VERSION "dbc-export 1 2026.26.6.5"

NS_ :

BS_:

BU_: ADSP APSB BB CMP DAS DPB EPAS3P EPASTP EPASTS GTW IDB OCS1P PTC RCM RCU TCU TCU2 UDS UI UIS VCLEFT VCSEAT2L VCSEAT2R

BO_ 942 APSB_warningMatrix2: 8 APSB
 SG_ APSB_w129_ECU_Power_Issue : 0|1@1+ (1,0) [0|1] "" Vector__XXX
 SG_ APSB_w130_ECU_Thermal_Issue : 1|1@1+ (1,0) [0|1] "" Vector__XXX
 SG_ APSB_w131_trap_exception : 2|1@1+ (1,0) [0|1] "" Vector__XXX
 SG_ APSB_w132_appVersionMismatch : 3|1@1+ (1,0) [0|1] "" Vector__XXX
 SG_ APSB_w133_ETHSwitchError : 4|1@1+ (1,0) [0|1] "" Vector__XXX
 SG_ APSB_w134_appMia : 5|1@1+ (1,0) [0|1] "" Vector__XXX
 SG_ APSB_w135_appCritical : 6|1@1+ (1,0) [0|1] "" Vector__XXX
 SG_ APSB_w136_gpsDisabled : 7|1@1+ (1,0) [0|1] "" Vector__XXX
 SG_ APSB_w137_gpsFaultReset : 8|1@1+ (1,0) [0|1] "" Vector__XXX
 SG_ APSB_w138_gpsComIssue : 9|1@1+ (1,0) [0|1] "" Vector__XXX
 SG_ APSB_w139_udpBufferOverflow : 10|1@1+ (1,0) [0|1] "" Vector__XXX
 SG_ APSB_w140_vcfrontMiaVehicleBus : 11|1@1+ (1,0) [0|1] "" Vector__XXX
 SG_ APSB_w141_rcmMiaPartyBus : 12|1@1+ (1,0) [0|1] "" Vector__XXX
 SG_ APSB_w142_diMiaPartyBus : 13|1@1+ (1,0) [0|1] "" Vector__XXX
 SG_ APSB_w143_espMiaPartyBus : 14|1@1+ (1,0) [0|1] "" Vector__XXX
 SG_ APSB_w144_vcleftMiaPartyBus : 15|1@1+ (1,0) [0|1] "" Vector__XXX
 SG_ APSB_w145_vcrightMiaPartyBus : 16|1@1+ (1,0) [0|1] "" Vector__XXX
 SG_ APSB_w146_epas3pMiaPartyBus : 17|1@1+ (1,0) [0|1] "" Vector__XXX
 SG_ APSB_w147_vcleftMiaVehBus : 18|1@1+ (1,0) [0|1] "" Vector__XXX
 SG_ APSB_w148_vcrightMiaVehBus : 19|1@1+ (1,0) [0|1] "" Vector__XXX
 SG_ APSB_w149_epblMiaVehBus : 20|1@1+ (1,0) [0|1] "" Vector__XXX
 SG_ APSB_w150_sccmMiaVehBus : 21|1@1+ (1,0) [0|1] "" Vector__XXX
 SG_ APSB_w151_apRecovered : 22|1@1+ (1,0) [0|1] "" Vector__XXX
 SG_ APSB_w152_gpsFusionStatus : 23|1@1+ (1,0) [0|1] "" Vector__XXX
 SG_ APSB_w153_eacInhibit : 24|1@1+ (1,0) [0|1] "" Vector__XXX
 SG_ APSB_w155_ethLwipError : 26|1@1+ (1,0) [0|1] "" Vector__XXX
 SG_ APSB_w156_lwipAssert : 27|1@1+ (1,0) [0|1] "" Vector__XXX
 SG_ APSB_w157_autopilotReboot : 28|1@1+ (1,0) [0|1] "" Vector__XXX
 SG_ APSB_w158_apbMia : 29|1@1+ (1,0) [0|1] "" Vector__XXX
 SG_ APSB_w159_apbCritical : 30|1@1+ (1,0) [0|1] "" Vector__XXX
 SG_ APSB_w160_apbVersionMismatch : 31|1@1+ (1,0) [0|1] "" Vector__XXX
 SG_ APSB_w161_gpsAntennaDisconnected : 32|1@1+ (1,0) [0|1] "" Vector__XXX
 SG_ APSB_w162_TurboA_DisRegPgoodErr : 33|1@1+ (1,0) [0|1] "" Vector__XXX
 SG_ APSB_w163_TurboA_DisRegNFault : 34|1@1+ (1,0) [0|1] "" Vector__XXX
 SG_ APSB_w164_TurboA_12VFuseFault : 35|1@1+ (1,0) [0|1] "" Vector__XXX
 SG_ APSB_w165_TurboA_Temp_NOS : 36|1@1+ (1,0) [0|1] "" Vector__XXX
 SG_ APSB_w166_TurboA_SMSLockStepErr : 37|1@1+ (1,0) [0|1] "" Vector__XXX
 SG_ APSB_w167_TurboA_TMU_Throttle : 38|1@1+ (1,0) [0|1] "" Vector__XXX
 SG_ APSB_w168_TurboA_SMS_WDOG : 39|1@1+ (1,0) [0|1] "" Vector__XXX
 SG_ APSB_w169_TurboA_SCS_LKUP : 40|1@1+ (1,0) [0|1] "" Vector__XXX
 SG_ APSB_w170_TurboA_A72_watchdog : 41|1@1+ (1,0) [0|1] "" Vector__XXX
 SG_ APSB_w171_TurboA_SMS_taskUtilErr : 42|1@1+ (1,0) [0|1] "" Vector__XXX
 SG_ APSB_w172_apFeaturesUnavailable : 43|1@1+ (1,0) [0|1] "" Vector__XXX
 SG_ APSB_w178_TurboB_DisRegPgoodErr : 49|1@1+ (1,0) [0|1] "" Vector__XXX
 SG_ APSB_w179_TurboB_DisRegNFault : 50|1@1+ (1,0) [0|1] "" Vector__XXX
 SG_ APSB_w180_TurboB_12VFuseFault : 51|1@1+ (1,0) [0|1] "" Vector__XXX
 SG_ APSB_w181_TurboB_Temp_NOS : 52|1@1+ (1,0) [0|1] "" Vector__XXX
 SG_ APSB_w182_TurboB_SMSLockStepErr : 53|1@1+ (1,0) [0|1] "" Vector__XXX
 SG_ APSB_w183_TurboB_TMU_Throttle : 54|1@1+ (1,0) [0|1] "" Vector__XXX
 SG_ APSB_w184_TurboB_SMS_WDOG : 55|1@1+ (1,0) [0|1] "" Vector__XXX
 SG_ APSB_w185_TurboB_SCS_LKUP : 56|1@1+ (1,0) [0|1] "" Vector__XXX
 SG_ APSB_w186_TurboB_A72_watchdog : 57|1@1+ (1,0) [0|1] "" Vector__XXX
 SG_ APSB_w187_TurboB_SMS_taskUtilErr : 58|1@1+ (1,0) [0|1] "" Vector__XXX
 SG_ APSB_w188_otherTurboUartMIA : 59|1@1+ (1,0) [0|1] "" Vector__XXX
 SG_ APSB_w189_vcfrontMiaPartyBus : 60|1@1+ (1,0) [0|1] "" Vector__XXX
 SG_ APSB_w190_iboosterMia : 61|1@1+ (1,0) [0|1] "" Vector__XXX
 SG_ APSB_w191_timesyncError : 62|1@1+ (1,0) [0|1] "" Vector__XXX
 SG_ APSB_w192_CANFault : 63|1@1+ (1,0) [0|1] "" Vector__XXX

BO_ 976 APSB_warningMatrix3: 8 APSB
 SG_ APSB_w193_camWindshieldUnclean : 0|1@1+ (1,0) [0|1] "" Vector__XXX
 SG_ APSB_w194_accDriverResumeRqrd : 1|1@1+ (1,0) [0|1] "" Vector__XXX
 SG_ APSB_w195_scwUnavailable : 2|1@1+ (1,0) [0|1] "" Vector__XXX
 SG_ APSB_w196_stopSignWarning : 3|1@1+ (1,0) [0|1] "" Vector__XXX
 SG_ APSB_w197_redLightWarning : 4|1@1+ (1,0) [0|1] "" Vector__XXX
 SG_ APSB_w198_tsrUnavailable : 5|1@1+ (1,0) [0|1] "" Vector__XXX
 SG_ APSB_w199_apcAbort : 6|1@1+ (1,0) [0|1] "" Vector__XXX
 SG_ APSB_w200_lcSlowdown : 7|1@1+ (1,0) [0|1] "" Vector__XXX
 SG_ APSB_w201_lcAborting : 8|1@1+ (1,0) [0|1] "" Vector__XXX
 SG_ APSB_w202_scwNoisyEnvironment : 9|1@1+ (1,0) [0|1] "" Vector__XXX
 SG_ APSB_w203_apcActivation : 10|1@1+ (1,0) [0|1] "" Vector__XXX
 SG_ APSB_w204_apcFinalFront : 11|1@1+ (1,0) [0|1] "" Vector__XXX
 SG_ APSB_w205_apcFinalRear : 12|1@1+ (1,0) [0|1] "" Vector__XXX
 SG_ APSB_w206_autosteerNotEnabled : 13|1@1+ (1,0) [0|1] "" Vector__XXX
 SG_ APSB_w207_autosteerUnavailable : 14|1@1+ (1,0) [0|1] "" Vector__XXX
 SG_ APSB_w208_rackDetected : 15|1@1+ (1,0) [0|1] "" Vector__XXX
 SG_ APSB_w209_autoSummonRequest : 16|1@1+ (1,0) [0|1] "" Vector__XXX
 SG_ APSB_w210_camObstrcted : 17|1@1+ (1,0) [0|1] "" Vector__XXX
 SG_ APSB_w211_accNoSeatBelt : 18|1@1+ (1,0) [0|1] "" Vector__XXX
 SG_ APSB_w212_lcUnavailableStrikeOut : 19|1@1+ (1,0) [0|1] "" Vector__XXX
 SG_ APSB_w213_autosteerStruckOut : 20|1@1+ (1,0) [0|1] "" Vector__XXX
 SG_ APSB_w214_driverNotIntracting : 21|1@1+ (1,0) [0|1] "" Vector__XXX
 SG_ APSB_w215_contDriverNotIntractin : 22|1@1+ (1,0) [0|1] "" Vector__XXX
 SG_ APSB_w216_driverOverriding : 23|1@1+ (1,0) [0|1] "" Vector__XXX
 SG_ APSB_w217_lcUnavailableSpeeding : 24|1@1+ (1,0) [0|1] "" Vector__XXX
 SG_ APSB_w218_lcSpeedExceededLimit : 25|1@1+ (1,0) [0|1] "" Vector__XXX
 SG_ APSB_w219_lcTempUnavailableSpeed : 26|1@1+ (1,0) [0|1] "" Vector__XXX
 SG_ APSB_w220_lcTempUnavailableRoad : 27|1@1+ (1,0) [0|1] "" Vector__XXX
 SG_ APSB_w221_accRadarBlind : 28|1@1+ (1,0) [0|1] "" Vector__XXX
 SG_ APSB_w222_accCameraBlind : 29|1@1+ (1,0) [0|1] "" Vector__XXX
 SG_ APSB_w223_accObjectInPath : 30|1@1+ (1,0) [0|1] "" Vector__XXX
 SG_ APSB_w224_accCameraCalibration : 31|1@1+ (1,0) [0|1] "" Vector__XXX
 SG_ APSB_w225_lcDegradedVisSpeedLmt : 32|1@1+ (1,0) [0|1] "" Vector__XXX
 SG_ APSB_w226_lcCamCalNeededSpeedLmt : 33|1@1+ (1,0) [0|1] "" Vector__XXX
 SG_ APSB_w227_virtualWallBlocked : 34|1@1+ (1,0) [0|1] "" Vector__XXX
 SG_ APSB_w228_DEPRECATED : 35|1@1+ (1,0) [0|1] "" Vector__XXX
 SG_ APSB_w229_alcUltrasoundDamaged : 36|1@1+ (1,0) [0|1] "" Vector__XXX
 SG_ APSB_w230_alcUltrasoundBlocked : 37|1@1+ (1,0) [0|1] "" Vector__XXX
 SG_ APSB_w231_idfEvent : 38|1@1+ (1,0) [0|1] "" Vector__XXX
 SG_ APSB_w232_laneChangeRequested : 39|1@1+ (1,0) [0|1] "" Vector__XXX
 SG_ APSB_w235_a72LoopDetected : 42|1@1+ (1,0) [0|1] "" Vector__XXX
 SG_ APSB_w236_canSharedMemError : 43|1@1+ (1,0) [0|1] "" Vector__XXX
 SG_ APSB_w237_faultMgrEventDetected : 44|1@1+ (1,0) [0|1] "" Vector__XXX
 SG_ APSB_w238_resetReason : 45|1@1+ (1,0) [0|1] "" Vector__XXX
 SG_ APSB_w241_ddrInitFailures : 48|1@1+ (1,0) [0|1] "" Vector__XXX
 SG_ APSB_w242_tripMBISTFailure : 49|1@1+ (1,0) [0|1] "" Vector__XXX
 SG_ APSB_w243_tripHWErrorStatus : 50|1@1+ (1,0) [0|1] "" Vector__XXX
 SG_ APSB_w244_gpuHWFaultStatus : 51|1@1+ (1,0) [0|1] "" Vector__XXX
 SG_ APSB_w245_eloopRxFromUnexpectedS : 52|1@1+ (1,0) [0|1] "" Vector__XXX
 SG_ APSB_w246_ethloopSwitchPortLinkD : 53|1@1+ (1,0) [0|1] "" Vector__XXX
 SG_ APSB_w247_ethernetFrameError : 54|1@1+ (1,0) [0|1] "" Vector__XXX
 SG_ APSB_w248_ethloopSwitchPoorSqi : 55|1@1+ (1,0) [0|1] "" Vector__XXX
 SG_ APSB_w249_ufsFailures : 56|1@1+ (1,0) [0|1] "" Vector__XXX
 SG_ APSB_w250_ethloopSwitchMemUsageT : 57|1@1+ (1,0) [0|1] "" Vector__XXX
 SG_ APSB_w251_ethloopSwitchMemUsageT : 58|1@1+ (1,0) [0|1] "" Vector__XXX
 SG_ APSB_w252_ethSwitchPortLinkDown : 59|1@1+ (1,0) [0|1] "" Vector__XXX
 SG_ APSB_w253_powerStateTimeout : 60|1@1+ (1,0) [0|1] "" Vector__XXX
 SG_ APSB_w254_sleepStateTimeout : 61|1@1+ (1,0) [0|1] "" Vector__XXX
 SG_ APSB_w255_bootHealth : 62|1@1+ (1,0) [0|1] "" Vector__XXX

BO_ 1003 APSB_warningMatrix4: 8 APSB
 SG_ APSB_w257_assertFailure : 0|1@1+ (1,0) [0|1] "" Vector__XXX
 SG_ APSB_w258_qspiFlashSectorChecksu : 1|1@1+ (1,0) [0|1] "" Vector__XXX
 SG_ APSB_w259_qspiFailure : 2|1@1+ (1,0) [0|1] "" Vector__XXX
 SG_ APSB_w260_pgoodFailure : 3|1@1+ (1,0) [0|1] "" Vector__XXX
 SG_ APSB_w261_vrmFaultGrpA : 4|1@1+ (1,0) [0|1] "" Vector__XXX
 SG_ APSB_w262_vrmFaultGrpB : 5|1@1+ (1,0) [0|1] "" Vector__XXX
 SG_ APSB_w263_vrmFaultGrpC : 6|1@1+ (1,0) [0|1] "" Vector__XXX
 SG_ APSB_w264_ddrPhy0Failures : 7|1@1+ (1,0) [0|1] "" Vector__XXX
 SG_ APSB_w265_ddrPhy1Failures : 8|1@1+ (1,0) [0|1] "" Vector__XXX
 SG_ APSB_w266_ddrPhy2Failures : 9|1@1+ (1,0) [0|1] "" Vector__XXX
 SG_ APSB_w267_ddrPhy3Failures : 10|1@1+ (1,0) [0|1] "" Vector__XXX
 SG_ APSB_w268_ddrControllerFailures : 11|1@1+ (1,0) [0|1] "" Vector__XXX
 SG_ APSB_w269_ethSwitchRxPageCountTo : 12|1@1+ (1,0) [0|1] "" Vector__XXX
 SG_ APSB_w270_ethSwitchRxPageCountTo : 13|1@1+ (1,0) [0|1] "" Vector__XXX
 SG_ APSB_w271_ddrScheduler0EccErrors : 14|1@1+ (1,0) [0|1] "" Vector__XXX
 SG_ APSB_w272_ddrScheduler1EccErrors : 15|1@1+ (1,0) [0|1] "" Vector__XXX
 SG_ APSB_w273_ddrScheduler2EccErrors : 16|1@1+ (1,0) [0|1] "" Vector__XXX
 SG_ APSB_w274_ddrScheduler3EccErrors : 17|1@1+ (1,0) [0|1] "" Vector__XXX
 SG_ APSB_w275_ddrScheduler4EccErrors : 18|1@1+ (1,0) [0|1] "" Vector__XXX
 SG_ APSB_w276_ddrScheduler5EccErrors : 19|1@1+ (1,0) [0|1] "" Vector__XXX
 SG_ APSB_w277_ddrScheduler6EccErrors : 20|1@1+ (1,0) [0|1] "" Vector__XXX
 SG_ APSB_w278_ddrScheduler7EccErrors : 21|1@1+ (1,0) [0|1] "" Vector__XXX
 SG_ APSB_w279_ufsPartitionError : 22|1@1+ (1,0) [0|1] "" Vector__XXX
 SG_ APSB_w280_pepsMia : 23|1@1+ (1,0) [0|1] "" Vector__XXX
 SG_ APSB_w281_rsaMia : 24|1@1+ (1,0) [0|1] "" Vector__XXX
 SG_ APSB_w282_smmuError : 25|1@1+ (1,0) [0|1] "" Vector__XXX
 SG_ APSB_w283_psfaMia : 26|1@1+ (1,0) [0|1] "" Vector__XXX
 SG_ APSB_w284_cam12VBuckBoostAPwrIss : 27|1@1+ (1,0) [0|1] "" Vector__XXX
 SG_ APSB_w285_cam12VBuckBoostBPwrIss : 28|1@1+ (1,0) [0|1] "" Vector__XXX
 SG_ APSB_w286_cam12VEFuseAPrimaryIss : 29|1@1+ (1,0) [0|1] "" Vector__XXX
 SG_ APSB_w287_cam12VEFuseASecondaryI : 30|1@1+ (1,0) [0|1] "" Vector__XXX
 SG_ APSB_w288_brakeboosterMia : 31|1@1+ (1,0) [0|1] "" Vector__XXX
 SG_ APSB_w289_turboTemperatureWarnin : 32|1@1+ (1,0) [0|1] "" Vector__XXX
 SG_ APSB_w290_cam12VBuckBoostBPwrRin : 33|1@1+ (1,0) [0|1] "" Vector__XXX
 SG_ APSB_w291_eplannerError : 34|1@1+ (1,0) [0|1] "" Vector__XXX
 SG_ APSB_w292_CH_busOff : 35|1@1+ (1,0) [0|1] "" Vector__XXX
 SG_ APSB_w293_PARTY_busOff : 36|1@1+ (1,0) [0|1] "" Vector__XXX
 SG_ APSB_w294_VEH_busOff : 37|1@1+ (1,0) [0|1] "" Vector__XXX
 SG_ APSB_w295_PT_busOff : 38|1@1+ (1,0) [0|1] "" Vector__XXX
 SG_ APSB_w296_wdogMonTaskDeadlineMis : 39|1@1+ (1,0) [0|1] "" Vector__XXX
 SG_ APSB_w297_earlyWDogAlert : 40|1@1+ (1,0) [0|1] "" Vector__XXX
 SG_ APSB_w298_cpuToApCanSharedMemErr : 41|1@1+ (1,0) [0|1] "" Vector__XXX
 SG_ APSB_w299_apToCpuCanSharedMemErr : 42|1@1+ (1,0) [0|1] "" Vector__XXX
 SG_ APSB_w300_sharedMemoryAccessErro : 43|1@1+ (1,0) [0|1] "" Vector__XXX
 SG_ APSB_w301_nocTimeoutDetected : 44|1@1+ (1,0) [0|1] "" Vector__XXX
 SG_ APSB_w302_canAPShmFifoFull : 45|1@1+ (1,0) [0|1] "" Vector__XXX
 SG_ APSB_w303_canAPShmFifoEmpty : 46|1@1+ (1,0) [0|1] "" Vector__XXX
 SG_ APSB_w304_dataAbort : 47|1@1+ (1,0) [0|1] "" Vector__XXX
 SG_ APSB_w305_gpsPgoodFailure : 48|1@1+ (1,0) [0|1] "" Vector__XXX
 SG_ APSB_w306_ethPgoodFailure : 49|1@1+ (1,0) [0|1] "" Vector__XXX
 SG_ APSB_w307_eccEventDetected : 50|1@1+ (1,0) [0|1] "" Vector__XXX
 SG_ APSB_w308_pmicErrorDetected : 51|1@1+ (1,0) [0|1] "" Vector__XXX
 SG_ APSB_w309_ethBridgeDown : 52|1@1+ (1,0) [0|1] "" Vector__XXX
 SG_ APSB_w310_wakeBootMetrics : 53|1@1+ (1,0) [0|1] "" Vector__XXX
 SG_ APSB_w311_apbdgDasMia : 54|1@1+ (1,0) [0|1] "" Vector__XXX
 SG_ APSB_w312_apbdgApMia : 55|1@1+ (1,0) [0|1] "" Vector__XXX
 SG_ APSB_w313_BDY_busOff : 56|1@1+ (1,0) [0|1] "" Vector__XXX
 SG_ APSB_w315_epas3pMiaBdyBus : 58|1@1+ (1,0) [0|1] "" Vector__XXX
 SG_ APSB_w316_apBootHealth : 59|1@1+ (1,0) [0|1] "" Vector__XXX
 SG_ APSB_w317_uiMia : 60|1@1+ (1,0) [0|1] "" Vector__XXX
 SG_ APSB_w318_ethernetNetworkBufferH : 61|1@1+ (1,0) [0|1] "" Vector__XXX
 SG_ APSB_w319_vehDasImposterDetected : 62|1@1+ (1,0) [0|1] "" Vector__XXX
 SG_ APSB_w320_eplannerPreconditionsM : 63|1@1+ (1,0) [0|1] "" Vector__XXX

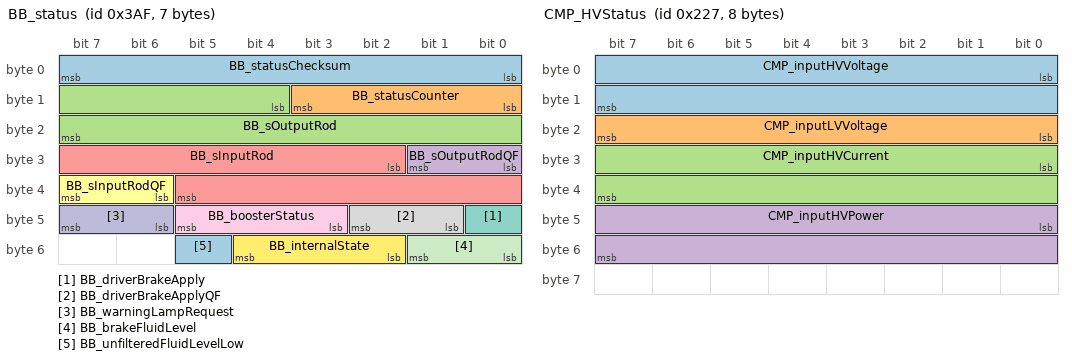
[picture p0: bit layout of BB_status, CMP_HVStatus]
BO_ 943 BB_status: 7 BB
 SG_ BB_statusChecksum : 0|8@1+ (1,0) [0|255] "" Vector__XXX
 SG_ BB_statusCounter : 8|4@1+ (1,0) [0|15] "" Vector__XXX
 SG_ BB_sOutputRod : 12|12@1+ (0.015625,-5) [-5|47] "mm" Vector__XXX
 SG_ BB_sOutputRodQF : 24|2@1+ (1,0) [0|3] "" Vector__XXX
 SG_ BB_sInputRod : 26|12@1+ (0.015625,-5) [-5|47] "mm" Vector__XXX
 SG_ BB_sInputRodQF : 38|2@1+ (1,0) [0|3] "" Vector__XXX
 SG_ BB_driverBrakeApply : 40|1@1+ (1,0) [0|1] "" Vector__XXX
 SG_ BB_driverBrakeApplyQF : 41|2@1+ (1,0) [0|3] "" Vector__XXX
 SG_ BB_boosterStatus : 43|3@1+ (1,0) [0|7] "" Vector__XXX
 SG_ BB_warningLampRequest : 46|2@1+ (1,0) [0|3] "" Vector__XXX
 SG_ BB_brakeFluidLevel : 48|2@1+ (1,0) [0|3] "" Vector__XXX
 SG_ BB_internalState : 50|3@1+ (1,0) [0|7] "" Vector__XXX
 SG_ BB_unfilteredFluidLevelLow : 53|1@1+ (1,0) [0|1] "" Vector__XXX

BO_ 551 CMP_HVStatus: 8 CMP
 SG_ CMP_inputHVVoltage : 0|16@1+ (0.1,0) [0|6553.4] "V" Vector__XXX
 SG_ CMP_inputLVVoltage : 16|8@1+ (0.1,0) [0|25.5] "V" Vector__XXX
 SG_ CMP_inputHVCurrent : 24|16@1+ (0.1,0) [0|6553.4] "A" Vector__XXX
 SG_ CMP_inputHVPower : 40|16@1+ (1,0) [0|65534] "W" Vector__XXX

BO_ 778 DAS_object: 8 DAS
 SG_ DAS_objectId M : 0|3@1+ (1,0) [0|7] "" Vector__XXX
 SG_ DAS_leadVehType m0 : 3|3@1+ (1,0) [0|7] "" Vector__XXX
 SG_ DAS_leadVehRelevantForControl m0 : 7|1@1+ (1,0) [0|1] "" Vector__XXX
 SG_ DAS_leadVehDx m0 : 8|8@1+ (0.5,0) [0|127] "m" Vector__XXX
 SG_ DAS_leadVehVxRel m0 : 16|4@1+ (4,-30) [-30|26] "m/s" Vector__XXX
 SG_ DAS_leadVehDy m0 : 20|7@1+ (0.35,-22.05) [-22.05|22.4] "m" Vector__XXX
 SG_ DAS_leadVehId m0 : 27|7@1+ (1,0) [0|126] "" Vector__XXX
 SG_ DAS_leadVeh2Type m0 : 34|3@1+ (1,0) [0|7] "" Vector__XXX
 SG_ DAS_leadVeh2RelevantForControl m0 : 38|1@1+ (1,0) [0|1] "" Vector__XXX
 SG_ DAS_leadVeh2Dx m0 : 39|8@1+ (0.5,0) [0|127] "m" Vector__XXX
 SG_ DAS_leadVeh2VxRel m0 : 47|4@1+ (4,-30) [-30|26] "m/s" Vector__XXX
 SG_ DAS_leadVeh2Dy m0 : 51|7@1+ (0.35,-22.05) [-22.05|22.4] "m" Vector__XXX
 SG_ DAS_leadVeh2Id m0 : 58|6@1+ (1,0) [1|63] "" Vector__XXX
 SG_ DAS_leftVehType m1 : 3|3@1+ (1,0) [0|7] "" Vector__XXX
 SG_ DAS_leftVehRelevantForControl m1 : 7|1@1+ (1,0) [0|1] "" Vector__XXX
 SG_ DAS_leftVehDx m1 : 8|8@1+ (0.5,0) [0|127] "m" Vector__XXX
 SG_ DAS_leftVehVxRel m1 : 16|4@1+ (4,-30) [-30|26] "m/s" Vector__XXX
 SG_ DAS_leftVehDy m1 : 20|7@1+ (0.35,-22.05) [-22.05|22.4] "m" Vector__XXX
 SG_ DAS_leftVehId m1 : 27|7@1+ (1,0) [0|126] "" Vector__XXX
 SG_ DAS_leftVeh2Type m1 : 34|3@1+ (1,0) [0|7] "" Vector__XXX
 SG_ DAS_leftVeh2RelevantForControl m1 : 38|1@1+ (1,0) [0|1] "" Vector__XXX
 SG_ DAS_leftVeh2Dx m1 : 39|8@1+ (0.5,0) [0|127] "m" Vector__XXX
 SG_ DAS_leftVeh2VxRel m1 : 47|4@1+ (4,-30) [-30|26] "m/s" Vector__XXX
 SG_ DAS_leftVeh2Dy m1 : 51|7@1+ (0.35,-22.05) [-22.05|22.4] "m" Vector__XXX
 SG_ DAS_leftVeh2Id m1 : 58|6@1+ (1,0) [1|63] "" Vector__XXX
 SG_ DAS_rightVehType m2 : 3|3@1+ (1,0) [0|7] "" Vector__XXX
 SG_ DAS_rightVehRelevantForControl m2 : 7|1@1+ (1,0) [0|1] "" Vector__XXX
 SG_ DAS_rightVehDx m2 : 8|8@1+ (0.5,0) [0|127] "m" Vector__XXX
 SG_ DAS_rightVehVxRel m2 : 16|4@1+ (4,-30) [-30|26] "m/s" Vector__XXX
 SG_ DAS_rightVehDy m2 : 20|7@1+ (0.35,-22.05) [-22.05|22.4] "m" Vector__XXX
 SG_ DAS_rightVehId m2 : 27|7@1+ (1,0) [0|126] "" Vector__XXX
 SG_ DAS_rightVeh2Type m2 : 34|3@1+ (1,0) [0|7] "" Vector__XXX
 SG_ DAS_rightVeh2RelevantForControl m2 : 38|1@1+ (1,0) [0|1] "" Vector__XXX
 SG_ DAS_rightVeh2Dx m2 : 39|8@1+ (0.5,0) [0|127] "m" Vector__XXX
 SG_ DAS_rightVeh2VxRel m2 : 47|4@1+ (4,-30) [-30|26] "m/s" Vector__XXX
 SG_ DAS_rightVeh2Dy m2 : 51|7@1+ (0.35,-22.05) [-22.05|22.4] "m" Vector__XXX
 SG_ DAS_rightVeh2Id m2 : 58|6@1+ (1,0) [1|63] "" Vector__XXX
 SG_ DAS_cutinVehType m3 : 3|3@1+ (1,0) [0|7] "" Vector__XXX
 SG_ DAS_cutinVehRelevantForControl m3 : 7|1@1+ (1,0) [0|1] "" Vector__XXX
 SG_ DAS_cutinVehDx m3 : 8|8@1+ (0.5,0) [0|127] "m" Vector__XXX
 SG_ DAS_cutinVehVxRel m3 : 16|4@1+ (4,-30) [-30|26] "m/s" Vector__XXX
 SG_ DAS_cutinVehDy m3 : 20|7@1+ (0.35,-22.05) [-22.05|22.4] "m" Vector__XXX
 SG_ DAS_cutinVehId m3 : 27|7@1+ (1,0) [0|126] "" Vector__XXX
 SG_ DAS_roadSignColor m4 : 3|3@1+ (1,0) [0|7] "" Vector__XXX
 SG_ DAS_roadSignId m4 : 6|8@1+ (1,0) [0|254] "" Vector__XXX
 SG_ DAS_roadSignStopLineDist m4 : 14|10@1+ (0.2,-20) [-20|184.4] "m" Vector__XXX
 SG_ DAS_roadSignControlActive m4 : 24|1@1+ (1,0) [0|1] "" Vector__XXX
 SG_ DAS_roadSignSource m4 : 25|2@1+ (1,0) [0|3] "" Vector__XXX
 SG_ DAS_roadSignArrow m4 : 27|3@1+ (1,0) [0|7] "" Vector__XXX
 SG_ DAS_roadSignOrientation m4 : 30|2@1+ (1,0) [0|3] "" Vector__XXX

BO_ 781 DAS_positioningEngineStatus: 8 DAS
 SG_ DAS_positioningEngineStatusMulti M : 0|4@1+ (1,0) [0|15] "" Vector__XXX
 SG_ DAS_meoSolverNumRuns m2 : 4|2@1+ (1,0) [0|3] "" Vector__XXX
 SG_ DAS_meoSolverReportTerminationTy m2 : 6|3@1+ (1,0) [0|7] "" Vector__XXX
 SG_ DAS_meoSolverReportTotalTimeS m2 : 9|3@1+ (1,0) [0|7] "" Vector__XXX
 SG_ DAS_meoHorizontalAccuracyM m2 : 12|6@1+ (1,0) [0|63] "m" Vector__XXX
 SG_ DAS_meoVerticalAccuracyM m2 : 18|6@1+ (1,0) [0|63] "m" Vector__XXX
 SG_ DAS_meoHeadingAccuracyDeg m2 : 24|3@1+ (1,0) [0|7] "deg" Vector__XXX
 SG_ DAS_meoHeadingValid m2 : 27|1@1+ (1,0) [0|1] "" Vector__XXX
 SG_ DAS_meoNumSatellitesUsed m2 : 28|5@1+ (1,0) [0|31] "" Vector__XXX
 SG_ DAS_meoGpsQualityLevel m2 : 33|3@1+ (1,0) [0|7] "" Vector__XXX
 SG_ DAS_meoFixType m2 : 36|3@1+ (1,0) [0|7] "" Vector__XXX
 SG_ DAS_meoResetCount m2 : 39|3@1+ (1,0) [0|7] "" Vector__XXX
 SG_ DAS_lastMeoResetReason m2 : 42|2@1+ (1,0) [0|3] "" Vector__XXX
 SG_ DAS_vioMultiGpsSelectedSource m3 : 4|3@1+ (1,0) [0|7] "" Vector__XXX
 SG_ DAS_vioMultiGpsPeCooldownActive m3 : 7|1@1+ (1,0) [0|1] "" Vector__XXX
 SG_ DAS_vioMultiGpsPeSppTdcpConsiste m3 : 8|1@1+ (1,0) [0|1] "" Vector__XXX
 SG_ DAS_vioMultiGpsPeMeoConsistentWi m3 : 9|1@1+ (1,0) [0|1] "" Vector__XXX
 SG_ DAS_vioMultiGpsPeSppTdcpVsR_0001 m3 : 10|4@1+ (1,0) [0|15] "m" Vector__XXX
 SG_ DAS_vioMultiGpsPeMeoVsRawGpsTran m3 : 14|4@1+ (1,0) [0|15] "m" Vector__XXX
 SG_ DAS_vioMultiGpsPeSppTdcpVsRawGps m3 : 18|3@1+ (1,0) [0|7] "deg" Vector__XXX
 SG_ DAS_vioMultiGpsPeMeoVsRawGpsRotD m3 : 21|3@1+ (1,0) [0|7] "deg" Vector__XXX
 SG_ DAS_publishedGpsSource m3 : 24|2@1+ (1,0) [0|3] "" Vector__XXX
 SG_ DAS_bluefinEnabled m3 : 26|1@1+ (1,0) [0|1] "" Vector__XXX
 SG_ DAS_orioleDisabled m3 : 27|1@1+ (1,0) [0|1] "" Vector__XXX
 SG_ DAS_disableMonarch m3 : 28|1@1+ (1,0) [0|1] "" Vector__XXX

BO_ 1548 DAS_telemetryRadar: 8 DAS
 SG_ DAS_TR_ObjIndex M : 0|5@1+ (1,0) [0|31] "" Vector__XXX
 SG_ DAS_TR_Counter : 54|2@1+ (1,0) [0|3] "" Vector__XXX
 SG_ DAS_TR_Obj00_Class m0 : 5|3@1+ (1,0) [0|7] "" Vector__XXX
 SG_ DAS_TR_Obj00_Dx m0 : 8|10@1+ (0.15625,0) [0|159.84375] "m" Vector__XXX
 SG_ DAS_TR_Obj00_Dy m0 : 18|6@1+ (0.5,-15.5) [-15.5|16] "m" Vector__XXX
 SG_ DAS_TR_Obj00_Vx m0 : 24|8@1+ (0.5,-63.5) [-63.5|64] "m/s" Vector__XXX
 SG_ DAS_TR_Obj00_RCS m0 : 32|8@1+ (0.25,-14) [-14|49.75] "dB" Vector__XXX
 SG_ DAS_TR_Obj00_Length m0 : 40|6@1+ (0.125,0) [0|7.875] "m" Vector__XXX
 SG_ DAS_TR_Obj00_MovingState m0 : 46|2@1+ (1,0) [0|3] "" Vector__XXX
 SG_ DAS_TR_Obj00_Dz m0 : 48|6@1+ (0.25,-5) [-5|10.75] "m" Vector__XXX
 SG_ DAS_TR_Obj00_Exist m0 : 56|5@1+ (3.125,0) [0|96.875] "%" Vector__XXX

BO_ 1237 DPB_alertLog: 8 DPB
 SG_ DPB_alertID : 0|9@1+ (1,0) [0|511] "" Vector__XXX
 SG_ DPB_alertState : 15|1@1+ (1,0) [0|1] "" Vector__XXX

BO_ 999 DPB_alertMatrix: 8 DPB
 SG_ DPB_matrixIndex M : 0|4@1+ (1,0) [0|15] "" Vector__XXX
 SG_ DPB_a001_pPlungerSensorOffsetHig m0 : 4|1@1+ (1,0) [0|1] "" Vector__XXX
 SG_ DPB_a002_pMC2SensorOffsetHigh m0 : 5|1@1+ (1,0) [0|1] "" Vector__XXX
 SG_ DPB_a003_AswEEPROMReadFailure m0 : 6|1@1+ (1,0) [0|1] "" Vector__XXX
 SG_ DPB_a004_assertionFault m0 : 7|1@1+ (1,0) [0|1] "" Vector__XXX
 SG_ DPB_a005_hardPedalChar m0 : 8|1@1+ (1,0) [0|1] "" Vector__XXX
 SG_ DPB_a006_hardPedalCharGoodCheck m0 : 9|1@1+ (1,0) [0|1] "" Vector__XXX
 SG_ DPB_a007_PMCLeakageDetected m0 : 10|1@1+ (1,0) [0|1] "" Vector__XXX
 SG_ DPB_a008_LiPSPts1Offset m0 : 11|1@1+ (1,0) [0|1] "" Vector__XXX
 SG_ DPB_a009_LiPSPts2Offset m0 : 12|1@1+ (1,0) [0|1] "" Vector__XXX
 SG_ DPB_a010_LiPSPtsConsistency m0 : 13|1@1+ (1,0) [0|1] "" Vector__XXX
 SG_ DPB_a011_PtsNonZeroStage1 m0 : 14|1@1+ (1,0) [0|1] "" Vector__XXX
 SG_ DPB_a012_PtsNonZeroStage2 m0 : 15|1@1+ (1,0) [0|1] "" Vector__XXX
 SG_ DPB_a013_softPedalChar m0 : 16|1@1+ (1,0) [0|1] "" Vector__XXX
 SG_ DPB_a014_CANControllerHWFault m0 : 17|1@1+ (1,0) [0|1] "" Vector__XXX
 SG_ DPB_a015_CAN1BusOff m0 : 18|1@1+ (1,0) [0|1] "" Vector__XXX
 SG_ DPB_a016_CAN2BusOff m0 : 19|1@1+ (1,0) [0|1] "" Vector__XXX
 SG_ DPB_a017_largeLeakageDetected m0 : 20|1@1+ (1,0) [0|1] "" Vector__XXX
 SG_ DPB_a018_largeLeakageDetectedGoo m0 : 21|1@1+ (1,0) [0|1] "" Vector__XXX
 SG_ DPB_a019_DETReportError m0 : 22|1@1+ (1,0) [0|1] "" Vector__XXX
 SG_ DPB_a020_ecuHuMismatch m0 : 23|1@1+ (1,0) [0|1] "" Vector__XXX
 SG_ DPB_a021_brakeSystemOverheatLvl1 m0 : 24|1@1+ (1,0) [0|1] "" Vector__XXX
 SG_ DPB_a022_brakeSystemOverheatLvl2 m0 : 25|1@1+ (1,0) [0|1] "" Vector__XXX
 SG_ DPB_a023_initialPlungerCheckFail m0 : 26|1@1+ (1,0) [0|1] "" Vector__XXX
 SG_ DPB_a024_ESPLDMFailure m0 : 27|1@1+ (1,0) [0|1] "" Vector__XXX
 SG_ DPB_a025_backupCircuitLeakage m0 : 28|1@1+ (1,0) [0|1] "" Vector__XXX
 SG_ DPB_a026_LiPSIDTimeout m0 : 29|1@1+ (1,0) [0|1] "" Vector__XXX
 SG_ DPB_a027_motorTempHighLevel1 m0 : 30|1@1+ (1,0) [0|1] "" Vector__XXX
 SG_ DPB_a028_motorTempHighLevel2 m0 : 31|1@1+ (1,0) [0|1] "" Vector__XXX
 SG_ DPB_a029_motorTestFault m0 : 32|1@1+ (1,0) [0|1] "" Vector__XXX
 SG_ DPB_a030_notShutDownRight m0 : 33|1@1+ (1,0) [0|1] "" Vector__XXX
 SG_ DPB_a031_HWParamReadFailed m0 : 34|1@1+ (1,0) [0|1] "" Vector__XXX
 SG_ DPB_a032_HWParamWriteFailed m0 : 35|1@1+ (1,0) [0|1] "" Vector__XXX
 SG_ DPB_a033_motorDynamicLimited m0 : 36|1@1+ (1,0) [0|1] "" Vector__XXX
 SG_ DPB_a034_lipsMemoryEmpty m0 : 37|1@1+ (1,0) [0|1] "" Vector__XXX
 SG_ DPB_a035_PDURouterinitialization m0 : 38|1@1+ (1,0) [0|1] "" Vector__XXX
 SG_ DPB_a036_lossOfPDUInstanceDetect m0 : 39|1@1+ (1,0) [0|1] "" Vector__XXX
 SG_ DPB_a037_plungerCircuitPressHigh m0 : 40|1@1+ (1,0) [0|1] "" Vector__XXX
 SG_ DPB_a038_plungerCircuitPressHigh m0 : 41|1@1+ (1,0) [0|1] "" Vector__XXX
 SG_ DPB_a039_plungerCircuitPressLow m0 : 42|1@1+ (1,0) [0|1] "" Vector__XXX
 SG_ DPB_a040_plungerCircuitPressLowG m0 : 43|1@1+ (1,0) [0|1] "" Vector__XXX
 SG_ DPB_a041_PSCGearRatioReadFault m0 : 44|1@1+ (1,0) [0|1] "" Vector__XXX
 SG_ DPB_a042_motorLoadPressImplausib m0 : 45|1@1+ (1,0) [0|1] "" Vector__XXX
 SG_ DPB_a043_PSCMotorSizeReadFault m0 : 46|1@1+ (1,0) [0|1] "" Vector__XXX
 SG_ DPB_a044_supplyOvervoltageLvl1 m0 : 47|1@1+ (1,0) [0|1] "" Vector__XXX
 SG_ DPB_a045_supplyOvervoltageLvl2 m0 : 48|1@1+ (1,0) [0|1] "" Vector__XXX
 SG_ DPB_a046_supplyOvervoltageLvl3 m0 : 49|1@1+ (1,0) [0|1] "" Vector__XXX
 SG_ DPB_a047_pPlungerPlausCheckFailu m0 : 50|1@1+ (1,0) [0|1] "" Vector__XXX
 SG_ DPB_a048_supplyUndervoltageLvl1 m0 : 51|1@1+ (1,0) [0|1] "" Vector__XXX
 SG_ DPB_a049_supplyUndervoltageLvl2 m0 : 52|1@1+ (1,0) [0|1] "" Vector__XXX
 SG_ DPB_a050_supplyUndervoltageLvl3 m0 : 53|1@1+ (1,0) [0|1] "" Vector__XXX
 SG_ DPB_a051_PSCVoltageImplausible m0 : 54|1@1+ (1,0) [0|1] "" Vector__XXX
 SG_ DPB_a052_PSIDTimeOut m0 : 55|1@1+ (1,0) [0|1] "" Vector__XXX
 SG_ DPB_a053_hydraulicAssemblyModeAc m0 : 56|1@1+ (1,0) [0|1] "" Vector__XXX
 SG_ DPB_a054_unsupportedHW m0 : 57|1@1+ (1,0) [0|1] "" Vector__XXX
 SG_ DPB_a055_unsupportedSeriesHWDete m0 : 58|1@1+ (1,0) [0|1] "" Vector__XXX
 SG_ DPB_a056_AdcPeripheralFault m0 : 59|1@1+ (1,0) [0|1] "" Vector__XXX
 SG_ DPB_a057_AdcPinTest m0 : 60|1@1+ (1,0) [0|1] "" Vector__XXX
 SG_ DPB_a058_AdcSelftestC5P m0 : 61|1@1+ (1,0) [0|1] "" Vector__XXX
 SG_ DPB_a059_factoryModeActive m0 : 62|1@1+ (1,0) [0|1] "" Vector__XXX
 SG_ DPB_a060_motorBridgeDriverFault m0 : 63|1@1+ (1,0) [0|1] "" Vector__XXX
 SG_ DPB_a061_bridgeSwitchInitError m1 : 4|1@1+ (1,0) [0|1] "" Vector__XXX
 SG_ DPB_a062_loadDumpOnFSLTest m1 : 5|1@1+ (1,0) [0|1] "" Vector__XXX
 SG_ DPB_a063_motorConfigMismatch m1 : 6|1@1+ (1,0) [0|1] "" Vector__XXX
 SG_ DPB_a064_current1OffsetHigh m1 : 7|1@1+ (1,0) [0|1] "" Vector__XXX
 SG_ DPB_a065_current1OffsetLow m1 : 8|1@1+ (1,0) [0|1] "" Vector__XXX
 SG_ DPB_a066_current2OffsetHigh m1 : 9|1@1+ (1,0) [0|1] "" Vector__XXX
 SG_ DPB_a067_current2OffsetLow m1 : 10|1@1+ (1,0) [0|1] "" Vector__XXX
 SG_ DPB_a068_BLMMuxerTimeoutError m1 : 11|1@1+ (1,0) [0|1] "" Vector__XXX
 SG_ DPB_a069_OBDCurrent1OORHigh m1 : 12|1@1+ (1,0) [0|1] "" Vector__XXX
 SG_ DPB_a070_OBDCurrent1OORLow m1 : 13|1@1+ (1,0) [0|1] "" Vector__XXX
 SG_ DPB_a071_OBDCurrent2OORHigh m1 : 14|1@1+ (1,0) [0|1] "" Vector__XXX
 SG_ DPB_a072_OBDCurrent2OORLow m1 : 15|1@1+ (1,0) [0|1] "" Vector__XXX
 SG_ DPB_a073_rotorCosOutOfRangeHigh m1 : 16|1@1+ (1,0) [0|1] "" Vector__XXX
 SG_ DPB_a074_rotorCosOutOfRangeLow m1 : 17|1@1+ (1,0) [0|1] "" Vector__XXX
 SG_ DPB_a075_rotorSinOutOfRangeHigh m1 : 18|1@1+ (1,0) [0|1] "" Vector__XXX
 SG_ DPB_a076_rotorSinOutOfRangeLow m1 : 19|1@1+ (1,0) [0|1] "" Vector__XXX
 SG_ DPB_a077_tempSens1ShortToSupply m1 : 20|1@1+ (1,0) [0|1] "" Vector__XXX
 SG_ DPB_a078_tempSens1ShortToGround m1 : 21|1@1+ (1,0) [0|1] "" Vector__XXX
 SG_ DPB_a079_tempSens2ShortToSupply m1 : 22|1@1+ (1,0) [0|1] "" Vector__XXX
 SG_ DPB_a080_tempSens2ShortToGround m1 : 23|1@1+ (1,0) [0|1] "" Vector__XXX
 SG_ DPB_a081_tempSensImplausVoltage m1 : 24|1@1+ (1,0) [0|1] "" Vector__XXX
 SG_ DPB_a082_chargePumpFault m1 : 25|1@1+ (1,0) [0|1] "" Vector__XXX
 SG_ DPB_a083_chargePumpUndervoltage m1 : 26|1@1+ (1,0) [0|1] "" Vector__XXX
 SG_ DPB_a084_RBCPUException m1 : 27|1@1+ (1,0) [0|1] "" Vector__XXX
 SG_ DPB_a085_infoFailureWrongCUBASHa m1 : 28|1@1+ (1,0) [0|1] "" Vector__XXX
 SG_ DPB_a086_diagHydProtectionPressF m1 : 29|1@1+ (1,0) [0|1] "" Vector__XXX
 SG_ DPB_a087_diagHydProtectionVlvFau m1 : 30|1@1+ (1,0) [0|1] "" Vector__XXX
 SG_ DPB_a088_DMATransferError m1 : 31|1@1+ (1,0) [0|1] "" Vector__XXX
 SG_ DPB_a089_ecuBandgap m1 : 32|1@1+ (1,0) [0|1] "" Vector__XXX
 SG_ DPB_a090_flashFault m1 : 33|1@1+ (1,0) [0|1] "" Vector__XXX
 SG_ DPB_a091_MRGPathTestFault m1 : 34|1@1+ (1,0) [0|1] "" Vector__XXX
 SG_ DPB_a092_decoupleBitTestFault m1 : 35|1@1+ (1,0) [0|1] "" Vector__XXX
 SG_ DPB_a093_ecuBistFaultCtrFault m1 : 36|1@1+ (1,0) [0|1] "" Vector__XXX
 SG_ DPB_a094_ecuClockTestFault m1 : 37|1@1+ (1,0) [0|1] "" Vector__XXX
 SG_ DPB_a095_ecuEnableElHighFault m1 : 38|1@1+ (1,0) [0|1] "" Vector__XXX
 SG_ DPB_a096_ecuEnableElLowFault m1 : 39|1@1+ (1,0) [0|1] "" Vector__XXX
 SG_ DPB_a097_ecuEnableHyHighFault m1 : 40|1@1+ (1,0) [0|1] "" Vector__XXX
 SG_ DPB_a098_ecuEnableHyLowFault m1 : 41|1@1+ (1,0) [0|1] "" Vector__XXX
 SG_ DPB_a099_ecuEnContinuousError m1 : 42|1@1+ (1,0) [0|1] "" Vector__XXX
 SG_ DPB_a100_ecuErrpinCounterFault m1 : 43|1@1+ (1,0) [0|1] "" Vector__XXX
 SG_ DPB_a101_ecuFastWdTestFault m1 : 44|1@1+ (1,0) [0|1] "" Vector__XXX
 SG_ DPB_a102_ecuVrOnWhileWdTimeout m1 : 45|1@1+ (1,0) [0|1] "" Vector__XXX
 SG_ DPB_a103_ecuVrViaSpiFails m1 : 46|1@1+ (1,0) [0|1] "" Vector__XXX
 SG_ DPB_a104_ecuWdStartuptestFault m1 : 47|1@1+ (1,0) [0|1] "" Vector__XXX
 SG_ DPB_a105_ecuWdSContinuousError m1 : 48|1@1+ (1,0) [0|1] "" Vector__XXX
 SG_ DPB_a106_ecuBistCmdTestFault m1 : 49|1@1+ (1,0) [0|1] "" Vector__XXX
 SG_ DPB_a107_vrOnFails m1 : 50|1@1+ (1,0) [0|1] "" Vector__XXX
 SG_ DPB_a108_GTMRefFrequencyError m1 : 51|1@1+ (1,0) [0|1] "" Vector__XXX
 SG_ DPB_a109_GTMTbuMonError m1 : 52|1@1+ (1,0) [0|1] "" Vector__XXX
 SG_ DPB_a110_HWBISTError m1 : 53|1@1+ (1,0) [0|1] "" Vector__XXX
 SG_ DPB_a111_hydraulicHardUndervolta m1 : 54|1@1+ (1,0) [0|1] "" Vector__XXX
 SG_ DPB_a112_hydraulicUndervoltage m1 : 55|1@1+ (1,0) [0|1] "" Vector__XXX
 SG_ DPB_a113_LiPS1SentLineHigh m1 : 56|1@1+ (1,0) [0|1] "" Vector__XXX
 SG_ DPB_a114_LiPS1SentLineLow m1 : 57|1@1+ (1,0) [0|1] "" Vector__XXX
 SG_ DPB_a115_LiPS1SentSensor m1 : 58|1@1+ (1,0) [0|1] "" Vector__XXX
 SG_ DPB_a116_LiPS1SentTransmission m1 : 59|1@1+ (1,0) [0|1] "" Vector__XXX
 SG_ DPB_a117_LiPS2PwmLineHigh m1 : 60|1@1+ (1,0) [0|1] "" Vector__XXX
 SG_ DPB_a118_LiPS2PwmLineLow m1 : 61|1@1+ (1,0) [0|1] "" Vector__XXX
 SG_ DPB_a119_LiPS2PwmTransmission m1 : 62|1@1+ (1,0) [0|1] "" Vector__XXX
 SG_ DPB_a120_LiPSOutOfRangeHigh m1 : 63|1@1+ (1,0) [0|1] "" Vector__XXX
 SG_ DPB_a121_LiPSOutOfRangeLow m2 : 4|1@1+ (1,0) [0|1] "" Vector__XXX
 SG_ DPB_a122_micAsicClkInError m2 : 5|1@1+ (1,0) [0|1] "" Vector__XXX
 SG_ DPB_a123_micAsicInitTestError m2 : 6|1@1+ (1,0) [0|1] "" Vector__XXX
 SG_ DPB_a124_asicOscillatorError m2 : 7|1@1+ (1,0) [0|1] "" Vector__XXX
 SG_ DPB_a125_B6AsicFault m2 : 8|1@1+ (1,0) [0|1] "" Vector__XXX
 SG_ DPB_a126_MICB6TransferError m2 : 9|1@1+ (1,0) [0|1] "" Vector__XXX
 SG_ DPB_a127_hydraulicAsicShortCircu m2 : 10|1@1+ (1,0) [0|1] "" Vector__XXX
 SG_ DPB_a128_micSpiTransferError m2 : 11|1@1+ (1,0) [0|1] "" Vector__XXX
 SG_ DPB_a129_AsicTrimmingNotComplete m2 : 12|1@1+ (1,0) [0|1] "" Vector__XXX
 SG_ DPB_a130_AsicMalfunctionDetected m2 : 13|1@1+ (1,0) [0|1] "" Vector__XXX
 SG_ DPB_a131_ASICOvercurrentOnGPIO25 m2 : 14|1@1+ (1,0) [0|1] "" Vector__XXX
 SG_ DPB_a132_ASICOvercurrentOnGPIO25 m2 : 15|1@1+ (1,0) [0|1] "" Vector__XXX
 SG_ DPB_a133_ASICOvercurrentOnGPIO50 m2 : 16|1@1+ (1,0) [0|1] "" Vector__XXX
 SG_ DPB_a134_ASICOvercurrentOnGPIO50 m2 : 17|1@1+ (1,0) [0|1] "" Vector__XXX
 SG_ DPB_a135_ASICOvercurrentOnGPIO50 m2 : 18|1@1+ (1,0) [0|1] "" Vector__XXX
 SG_ DPB_a136_ASICOvercurrentOnGPIO50 m2 : 19|1@1+ (1,0) [0|1] "" Vector__XXX
 SG_ DPB_a137_ASICOvercurrentOnWRHS m2 : 20|1@1+ (1,0) [0|1] "" Vector__XXX
 SG_ DPB_a138_DIchassisControlCounter m2 : 21|1@1+ (1,0) [0|1] "" Vector__XXX
 SG_ DPB_a139_DIchassisControlChecksu m2 : 22|1@1+ (1,0) [0|1] "" Vector__XXX
 SG_ DPB_a140_DIchassisControlDLC m2 : 23|1@1+ (1,0) [0|1] "" Vector__XXX
 SG_ DPB_a141_DIchassisControlTimeout m2 : 24|1@1+ (1,0) [0|1] "" Vector__XXX
 SG_ DPB_a142_DIsystemStatusCounter m2 : 25|1@1+ (1,0) [0|1] "" Vector__XXX
 SG_ DPB_a143_DIsystemStatusChecksum m2 : 26|1@1+ (1,0) [0|1] "" Vector__XXX
 SG_ DPB_a144_DIsystemStatusDLC m2 : 27|1@1+ (1,0) [0|1] "" Vector__XXX
 SG_ DPB_a145_DIsystemStatusTimeout m2 : 28|1@1+ (1,0) [0|1] "" Vector__XXX
 SG_ DPB_a146_DIFtorqueCounter m2 : 29|1@1+ (1,0) [0|1] "" Vector__XXX
 SG_ DPB_a147_DIFtorqueChecksum m2 : 30|1@1+ (1,0) [0|1] "" Vector__XXX
 SG_ DPB_a148_DIFtorqueDLC m2 : 31|1@1+ (1,0) [0|1] "" Vector__XXX
 SG_ DPB_a149_DIFtorqueTimeout m2 : 32|1@1+ (1,0) [0|1] "" Vector__XXX
 SG_ DPB_a150_DIRtorqueCounter m2 : 33|1@1+ (1,0) [0|1] "" Vector__XXX
 SG_ DPB_a151_DIRtorqueChecksum m2 : 34|1@1+ (1,0) [0|1] "" Vector__XXX
 SG_ DPB_a152_DIRtorqueDLC m2 : 35|1@1+ (1,0) [0|1] "" Vector__XXX
 SG_ DPB_a153_DIRtorqueTimeout m2 : 36|1@1+ (1,0) [0|1] "" Vector__XXX
 SG_ DPB_a154_EPBLstatusCounter m2 : 37|1@1+ (1,0) [0|1] "" Vector__XXX
 SG_ DPB_a155_EPBLstatusChecksum m2 : 38|1@1+ (1,0) [0|1] "" Vector__XXX
 SG_ DPB_a156_EPBLstatusDLC m2 : 39|1@1+ (1,0) [0|1] "" Vector__XXX
 SG_ DPB_a157_EPBLstatusTimeout m2 : 40|1@1+ (1,0) [0|1] "" Vector__XXX
 SG_ DPB_a158_EPBRstatusCounter m2 : 41|1@1+ (1,0) [0|1] "" Vector__XXX
 SG_ DPB_a159_EPBRstatusChecksum m2 : 42|1@1+ (1,0) [0|1] "" Vector__XXX
 SG_ DPB_a160_EPBRstatusDLC m2 : 43|1@1+ (1,0) [0|1] "" Vector__XXX
 SG_ DPB_a161_EPBRstatusTimeout m2 : 44|1@1+ (1,0) [0|1] "" Vector__XXX
 SG_ DPB_a162_ESP_modulator1Counter m2 : 45|1@1+ (1,0) [0|1] "" Vector__XXX
 SG_ DPB_a163_ESP_modulator1Checksum m2 : 46|1@1+ (1,0) [0|1] "" Vector__XXX
 SG_ DPB_a164_ESP_modulator1DLC m2 : 47|1@1+ (1,0) [0|1] "" Vector__XXX
 SG_ DPB_a165_ESP_modulator1Timeout m2 : 48|1@1+ (1,0) [0|1] "" Vector__XXX
 SG_ DPB_a166_ESP_chassis3Counter m2 : 49|1@1+ (1,0) [0|1] "" Vector__XXX
 SG_ DPB_a167_ESP_chassis3Checksum m2 : 50|1@1+ (1,0) [0|1] "" Vector__XXX
 SG_ DPB_a168_ESP_chassis3DLC m2 : 51|1@1+ (1,0) [0|1] "" Vector__XXX
 SG_ DPB_a169_ESP_chassis3Timeout m2 : 52|1@1+ (1,0) [0|1] "" Vector__XXX
 SG_ DPB_a170_ESP_modulator2Counter m2 : 53|1@1+ (1,0) [0|1] "" Vector__XXX
 SG_ DPB_a171_ESP_modulator2Checksum m2 : 54|1@1+ (1,0) [0|1] "" Vector__XXX
 SG_ DPB_a172_ESP_modulator2DLC m2 : 55|1@1+ (1,0) [0|1] "" Vector__XXX
 SG_ DPB_a173_ESP_modulator2Timeout m2 : 56|1@1+ (1,0) [0|1] "" Vector__XXX
 SG_ DPB_a174_ESP_modulator3Counter m2 : 57|1@1+ (1,0) [0|1] "" Vector__XXX
 SG_ DPB_a175_ESP_modulator3Checksum m2 : 58|1@1+ (1,0) [0|1] "" Vector__XXX
 SG_ DPB_a176_ESP_modulator3DLC m2 : 59|1@1+ (1,0) [0|1] "" Vector__XXX
 SG_ DPB_a177_ESP_modulator3Timeout m2 : 60|1@1+ (1,0) [0|1] "" Vector__XXX
 SG_ DPB_a178_PMstate2Counter m2 : 61|1@1+ (1,0) [0|1] "" Vector__XXX
 SG_ DPB_a179_PMstate2Checksum m2 : 62|1@1+ (1,0) [0|1] "" Vector__XXX
 SG_ DPB_a180_PMstate2DLC m2 : 63|1@1+ (1,0) [0|1] "" Vector__XXX
 SG_ DPB_a181_PMstate2Timeout m3 : 4|1@1+ (1,0) [0|1] "" Vector__XXX
 SG_ DPB_a182_RCMInertial2Counter m3 : 5|1@1+ (1,0) [0|1] "" Vector__XXX
 SG_ DPB_a183_RCMInertial2Checksum m3 : 6|1@1+ (1,0) [0|1] "" Vector__XXX
 SG_ DPB_a184_RCMInertial2DLC m3 : 7|1@1+ (1,0) [0|1] "" Vector__XXX
 SG_ DPB_a185_RCMInertial2Timeout m3 : 8|1@1+ (1,0) [0|1] "" Vector__XXX
 SG_ DPB_a186_LVPowerStateTimeout m3 : 9|1@1+ (1,0) [0|1] "" Vector__XXX
 SG_ DPB_a187_LVPowerStateChecksum m3 : 10|1@1+ (1,0) [0|1] "" Vector__XXX
 SG_ DPB_a188_LVPowerStateDLC m3 : 11|1@1+ (1,0) [0|1] "" Vector__XXX
 SG_ DPB_a189_LVPowerStateCounter m3 : 12|1@1+ (1,0) [0|1] "" Vector__XXX
 SG_ DPB_a190_VCLEFTepbmStatusCounter m3 : 13|1@1+ (1,0) [0|1] "" Vector__XXX
 SG_ DPB_a191_VCLEFTepbmStatusChecksu m3 : 14|1@1+ (1,0) [0|1] "" Vector__XXX
 SG_ DPB_a192_VCLEFTepbmStatusDLC m3 : 15|1@1+ (1,0) [0|1] "" Vector__XXX
 SG_ DPB_a193_VCLEFTepbmStatusTimeout m3 : 16|1@1+ (1,0) [0|1] "" Vector__XXX
 SG_ DPB_a194_VCRIGHTepbmStatusCounte m3 : 17|1@1+ (1,0) [0|1] "" Vector__XXX
 SG_ DPB_a195_VCRIGHTepbmStatusChecks m3 : 18|1@1+ (1,0) [0|1] "" Vector__XXX
 SG_ DPB_a196_VCRIGHTepbmStatusDLC m3 : 19|1@1+ (1,0) [0|1] "" Vector__XXX
 SG_ DPB_a197_VCRIGHTepbmStatusTimeou m3 : 20|1@1+ (1,0) [0|1] "" Vector__XXX
 SG_ DPB_a198_CANOvervoltage m3 : 21|1@1+ (1,0) [0|1] "" Vector__XXX
 SG_ DPB_a199_pMC1QFaulty m3 : 22|1@1+ (1,0) [0|1] "" Vector__XXX
 SG_ DPB_a200_ESPRunoutSupportNotAvai m3 : 23|1@1+ (1,0) [0|1] "" Vector__XXX
 SG_ DPB_a201_vehicleSpeedQFaulty m3 : 24|1@1+ (1,0) [0|1] "" Vector__XXX
 SG_ DPB_a202_vehicleStandstillQFault m3 : 25|1@1+ (1,0) [0|1] "" Vector__XXX
 SG_ DPB_a203_ABSNotAvailable m3 : 26|1@1+ (1,0) [0|1] "" Vector__XXX
 SG_ DPB_a204_CANUndervoltage m3 : 27|1@1+ (1,0) [0|1] "" Vector__XXX
 SG_ DPB_a205_NvMWriteCycleExceed m3 : 28|1@1+ (1,0) [0|1] "" Vector__XXX
 SG_ DPB_a206_OSTaskSchemeError m3 : 29|1@1+ (1,0) [0|1] "" Vector__XXX
 SG_ DPB_a207_hydraulicOvervoltage m3 : 30|1@1+ (1,0) [0|1] "" Vector__XXX
 SG_ DPB_a208_pressureSensor1Short m3 : 31|1@1+ (1,0) [0|1] "" Vector__XXX
 SG_ DPB_a209_pressureSensor1High m3 : 32|1@1+ (1,0) [0|1] "" Vector__XXX
 SG_ DPB_a210_pressureSensor1Low m3 : 33|1@1+ (1,0) [0|1] "" Vector__XXX
 SG_ DPB_a211_pressureSensor1Fault m3 : 34|1@1+ (1,0) [0|1] "" Vector__XXX
 SG_ DPB_a212_pressureSensor1Temp m3 : 35|1@1+ (1,0) [0|1] "" Vector__XXX
 SG_ DPB_a213_pressureSensor1Fault m3 : 36|1@1+ (1,0) [0|1] "" Vector__XXX
 SG_ DPB_a214_pressureSensor2Short m3 : 37|1@1+ (1,0) [0|1] "" Vector__XXX
 SG_ DPB_a215_pressureSensor2High m3 : 38|1@1+ (1,0) [0|1] "" Vector__XXX
 SG_ DPB_a216_pressureSensor2Low m3 : 39|1@1+ (1,0) [0|1] "" Vector__XXX
 SG_ DPB_a217_pressureSensor2Fault m3 : 40|1@1+ (1,0) [0|1] "" Vector__XXX
 SG_ DPB_a218_pressureSensor2Temp m3 : 41|1@1+ (1,0) [0|1] "" Vector__XXX
 SG_ DPB_a219_pressureSensor2Fault m3 : 42|1@1+ (1,0) [0|1] "" Vector__XXX
 SG_ DPB_a220_excessiveBoostWakeupsDe m3 : 43|1@1+ (1,0) [0|1] "" Vector__XXX
 SG_ DPB_a221_notShutdownRight m3 : 44|1@1+ (1,0) [0|1] "" Vector__XXX
 SG_ DPB_a222_excessiveEcuResetsDetec m3 : 45|1@1+ (1,0) [0|1] "" Vector__XXX
 SG_ DPB_a223_RAMFault m3 : 46|1@1+ (1,0) [0|1] "" Vector__XXX
 SG_ DPB_a224_brakeBoostLost m3 : 47|1@1+ (1,0) [0|1] "" Vector__XXX
 SG_ DPB_a225_U5VOutOfRange m3 : 48|1@1+ (1,0) [0|1] "" Vector__XXX
 SG_ DPB_a226_U5VTestFault m3 : 49|1@1+ (1,0) [0|1] "" Vector__XXX
 SG_ DPB_a227_brakeFluidLoss m3 : 50|1@1+ (1,0) [0|1] "" Vector__XXX
 SG_ DPB_a228_supplyASICInitFault m3 : 51|1@1+ (1,0) [0|1] "" Vector__XXX
 SG_ DPB_a229_IREFOutOfRange m3 : 52|1@1+ (1,0) [0|1] "" Vector__XXX
 SG_ DPB_a230_OSErrorHook m3 : 53|1@1+ (1,0) [0|1] "" Vector__XXX
 SG_ DPB_a231_stackOverUnderFlow m3 : 54|1@1+ (1,0) [0|1] "" Vector__XXX
 SG_ DPB_a232_systemErrorHook m3 : 55|1@1+ (1,0) [0|1] "" Vector__XXX
 SG_ DPB_a233_systemTaskJitter m3 : 56|1@1+ (1,0) [0|1] "" Vector__XXX
 SG_ DPB_a234_systemTaskOverRun m3 : 57|1@1+ (1,0) [0|1] "" Vector__XXX
 SG_ DPB_a235_UB6PlausiMonFault m3 : 58|1@1+ (1,0) [0|1] "" Vector__XXX
 SG_ DPB_a236_UB6SupplyPathFault m3 : 59|1@1+ (1,0) [0|1] "" Vector__XXX
 SG_ DPB_a237_uCVoltageDividerDrift m3 : 60|1@1+ (1,0) [0|1] "" Vector__XXX
 SG_ DPB_a238_microRegisterFault m3 : 61|1@1+ (1,0) [0|1] "" Vector__XXX
 SG_ DPB_a239_microSafetyFault m3 : 62|1@1+ (1,0) [0|1] "" Vector__XXX
 SG_ DPB_a240_microSafetyLogicFault m3 : 63|1@1+ (1,0) [0|1] "" Vector__XXX
 SG_ DPB_a241_uCSafetyNotification m4 : 4|1@1+ (1,0) [0|1] "" Vector__XXX
 SG_ DPB_a242_uCSafetyNotificationGRA m4 : 5|1@1+ (1,0) [0|1] "" Vector__XXX
 SG_ DPB_a243_microSupplyError m4 : 6|1@1+ (1,0) [0|1] "" Vector__XXX
 SG_ DPB_a244_valvesGenericFault m4 : 7|1@1+ (1,0) [0|1] "" Vector__XXX
 SG_ DPB_a245_valveMV0Fault m4 : 8|1@1+ (1,0) [0|1] "" Vector__XXX
 SG_ DPB_a246_valveMV5Fault m4 : 9|1@1+ (1,0) [0|1] "" Vector__XXX
 SG_ DPB_a247_valveMV6Fault m4 : 10|1@1+ (1,0) [0|1] "" Vector__XXX
 SG_ DPB_a248_valveMV61Fault m4 : 11|1@1+ (1,0) [0|1] "" Vector__XXX
 SG_ DPB_a249_valveMV62Fault m4 : 12|1@1+ (1,0) [0|1] "" Vector__XXX
 SG_ DPB_a250_valveMV7Fault m4 : 13|1@1+ (1,0) [0|1] "" Vector__XXX
 SG_ DPB_a251_valveMV8Fault m4 : 14|1@1+ (1,0) [0|1] "" Vector__XXX
 SG_ DPB_a252_valveMV81Fault m4 : 15|1@1+ (1,0) [0|1] "" Vector__XXX
 SG_ DPB_a253_valveMV82Fault m4 : 16|1@1+ (1,0) [0|1] "" Vector__XXX
 SG_ DPB_a254_valveMV9Fault m4 : 17|1@1+ (1,0) [0|1] "" Vector__XXX
 SG_ DPB_a255_valveRelayShort m4 : 18|1@1+ (1,0) [0|1] "" Vector__XXX
 SG_ DPB_a256_valveRelayActuationFaul m4 : 19|1@1+ (1,0) [0|1] "" Vector__XXX
 SG_ DPB_a257_valveRelayOnContinuous m4 : 20|1@1+ (1,0) [0|1] "" Vector__XXX
 SG_ DPB_a258_valveRelayOffContinuous m4 : 21|1@1+ (1,0) [0|1] "" Vector__XXX
 SG_ DPB_a259_valveRelayTestUndervolt m4 : 22|1@1+ (1,0) [0|1] "" Vector__XXX
 SG_ DPB_a260_valveRelaySafetySwitchF m4 : 23|1@1+ (1,0) [0|1] "" Vector__XXX
 SG_ DPB_a261_WdhAsicWdCmdMissing m4 : 24|1@1+ (1,0) [0|1] "" Vector__XXX
 SG_ DPB_a262_WdhAsicWdErrorCntLimit m4 : 25|1@1+ (1,0) [0|1] "" Vector__XXX
 SG_ DPB_a263_WdhAsicWdErrorCntStuck m4 : 26|1@1+ (1,0) [0|1] "" Vector__XXX
 SG_ DPB_a264_WdhSwBistConCnt m4 : 27|1@1+ (1,0) [0|1] "" Vector__XXX
 SG_ DPB_a265_WdhTaskMonConCnt m4 : 28|1@1+ (1,0) [0|1] "" Vector__XXX
 SG_ DPB_a266_RPSNvMReadFault m4 : 29|1@1+ (1,0) [0|1] "" Vector__XXX
 SG_ DPB_a267_RpsAngleImplausible m4 : 30|1@1+ (1,0) [0|1] "" Vector__XXX
 SG_ DPB_a268_RPSVectorOscillating m4 : 31|1@1+ (1,0) [0|1] "" Vector__XXX
 SG_ DPB_a269_RPSVectorRangeHigh m4 : 32|1@1+ (1,0) [0|1] "" Vector__XXX
 SG_ DPB_a270_RPSVectorRangeLow m4 : 33|1@1+ (1,0) [0|1] "" Vector__XXX
 SG_ DPB_a271_RPSWrongCalibData m4 : 34|1@1+ (1,0) [0|1] "" Vector__XXX
 SG_ DPB_a272_runtimeAssertionFault m4 : 35|1@1+ (1,0) [0|1] "" Vector__XXX
 SG_ DPB_a273_SMMOneRequestsInit m4 : 36|1@1+ (1,0) [0|1] "" Vector__XXX
 SG_ DPB_a274_AswSystemTimeOut m4 : 37|1@1+ (1,0) [0|1] "" Vector__XXX
 SG_ DPB_a275_Ps1Ps2PlausibilityFault m4 : 38|1@1+ (1,0) [0|1] "" Vector__XXX
 SG_ DPB_a276_VCFRONTsensorsCounter m4 : 39|1@1+ (1,0) [0|1] "" Vector__XXX
 SG_ DPB_a277_VCFRONTsensorsChecksum m4 : 40|1@1+ (1,0) [0|1] "" Vector__XXX
 SG_ DPB_a278_VCFRONTsensorsDLC m4 : 41|1@1+ (1,0) [0|1] "" Vector__XXX
 SG_ DPB_a279_VCFRONTsensorsTimeout m4 : 42|1@1+ (1,0) [0|1] "" Vector__XXX
 SG_ DPB_a280_LowBrakeFluid m4 : 43|1@1+ (1,0) [0|1] "" Vector__XXX
 SG_ DPB_a281_brakeFluidOORHigh m4 : 44|1@1+ (1,0) [0|1] "" Vector__XXX
 SG_ DPB_a282_DIbrakeCommandCounter m4 : 45|1@1+ (1,0) [0|1] "" Vector__XXX
 SG_ DPB_a283_DIbrakeCommandChecksum m4 : 46|1@1+ (1,0) [0|1] "" Vector__XXX
 SG_ DPB_a284_DIbrakeCommandDLC m4 : 47|1@1+ (1,0) [0|1] "" Vector__XXX
 SG_ DPB_a285_DIbrakeCommandTimeout m4 : 48|1@1+ (1,0) [0|1] "" Vector__XXX
 SG_ DPB_a286_ebrCmdStateInvalid m4 : 49|1@1+ (1,0) [0|1] "" Vector__XXX
 SG_ DPB_a287_brakeCmdStateInvalid m4 : 50|1@1+ (1,0) [0|1] "" Vector__XXX
 SG_ DPB_a288_PlantDegradedSW m4 : 51|1@1+ (1,0) [0|1] "" Vector__XXX
 SG_ DPB_a289_evacFillNotComplete m4 : 52|1@1+ (1,0) [0|1] "" Vector__XXX
 SG_ DPB_a290_securityInfo m4 : 53|1@1+ (1,0) [0|1] "" Vector__XXX
 SG_ DPB_a291_extDBRRequestTooLow m4 : 54|1@1+ (1,0) [0|1] "" Vector__XXX
 SG_ DPB_a292_CBDS_fillBufferThreshol m4 : 55|1@1+ (1,0) [0|1] "" Vector__XXX
 SG_ DPB_a293_CBDS_fmeInternalEvent m4 : 56|1@1+ (1,0) [0|1] "" Vector__XXX
 SG_ DPB_a294_hbaNormalModeActive m4 : 57|1@1+ (1,0) [0|1] "" Vector__XXX
 SG_ DPB_a295_hbaTrackModeActive m4 : 58|1@1+ (1,0) [0|1] "" Vector__XXX
 SG_ DPB_a296_StatInvalid_DI_FullSNA m4 : 59|1@1+ (1,0) [0|1] "" Vector__XXX
 SG_ DPB_a297_undefinedAlertDetected m4 : 60|1@1+ (1,0) [0|1] "" Vector__XXX
 SG_ DPB_a298_runningPlungerCircuitTe m4 : 61|1@1+ (1,0) [0|1] "" Vector__XXX
 SG_ DPB_a299_PM_locStateCounter m4 : 62|1@1+ (1,0) [0|1] "" Vector__XXX
 SG_ DPB_a300_PM_locStateChecksum m4 : 63|1@1+ (1,0) [0|1] "" Vector__XXX
 SG_ DPB_a301_PM_locStateDLC m5 : 4|1@1+ (1,0) [0|1] "" Vector__XXX
 SG_ DPB_a302_PM_locStateTimeout m5 : 5|1@1+ (1,0) [0|1] "" Vector__XXX
 SG_ DPB_a303_actuatingDIFullTorqueCm m5 : 6|1@1+ (1,0) [0|1] "" Vector__XXX
 SG_ DPB_a304_actuatingDITorqueCmd m5 : 7|1@1+ (1,0) [0|1] "" Vector__XXX
 SG_ DPB_a305_DIbrakeTorqueCommandAnd m5 : 8|1@1+ (1,0) [0|1] "" Vector__XXX
 SG_ DPB_a306_actuatorFallbackBasicMa m5 : 9|1@1+ (1,0) [0|1] "" Vector__XXX
 SG_ DPB_a307_actuatorDegradedMap m5 : 10|1@1+ (1,0) [0|1] "" Vector__XXX
 SG_ DPB_a308_backupMode m5 : 11|1@1+ (1,0) [0|1] "" Vector__XXX
 SG_ DPB_a309_DIFAxleTorqueInvalid m5 : 12|1@1+ (1,0) [0|1] "" Vector__XXX
 SG_ DPB_a310_DIRAxleTorqueInvalid m5 : 13|1@1+ (1,0) [0|1] "" Vector__XXX
 SG_ DPB_a311_postrunDurationTooLong m5 : 14|1@1+ (1,0) [0|1] "" Vector__XXX
 SG_ DPB_a312_continuouslyActivatedVa m5 : 15|1@1+ (1,0) [0|1] "" Vector__XXX
 SG_ DPB_a313_qualifiedBrakeEventDete m5 : 16|1@1+ (1,0) [0|1] "" Vector__XXX
 SG_ DPB_a314_runningCyclicVolumeChec m5 : 17|1@1+ (1,0) [0|1] "" Vector__XXX
 SG_ DPB_a315_runningLeakageAndAirMon m5 : 18|1@1+ (1,0) [0|1] "" Vector__XXX
 SG_ DPB_a316_lowBrakeFluidDetectedOn m5 : 19|1@1+ (1,0) [0|1] "" Vector__XXX
 SG_ DPB_a317_DASredundantBrakingCont m5 : 20|1@1+ (1,0) [0|1] "" Vector__XXX
 SG_ DPB_a318_DASredundantBrakingCont m5 : 21|1@1+ (1,0) [0|1] "" Vector__XXX
 SG_ DPB_a319_DASredundantBrakingCont m5 : 22|1@1+ (1,0) [0|1] "" Vector__XXX
 SG_ DPB_a320_DASredundantBrakingCont m5 : 23|1@1+ (1,0) [0|1] "" Vector__XXX
 SG_ DPB_a321_DASredundantBrakingCont m5 : 24|1@1+ (1,0) [0|1] "" Vector__XXX
 SG_ DPB_a322_DASredundantBrakingCont m5 : 25|1@1+ (1,0) [0|1] "" Vector__XXX
 SG_ DPB_a323_DASredundantBrakingCont m5 : 26|1@1+ (1,0) [0|1] "" Vector__XXX
 SG_ DPB_a324_DASredundantBrakingCont m5 : 27|1@1+ (1,0) [0|1] "" Vector__XXX
 SG_ DPB_a325_DIlocStatus2Checksum m5 : 28|1@1+ (1,0) [0|1] "" Vector__XXX
 SG_ DPB_a326_DIlocStatus2Counter m5 : 29|1@1+ (1,0) [0|1] "" Vector__XXX
 SG_ DPB_a327_DIlocStatus2DLC m5 : 30|1@1+ (1,0) [0|1] "" Vector__XXX
 SG_ DPB_a328_DIlocStatus2Timeout m5 : 31|1@1+ (1,0) [0|1] "" Vector__XXX
 SG_ DPB_a329_standaloneEBRActive m5 : 32|1@1+ (1,0) [0|1] "" Vector__XXX
 SG_ DPB_a330_EMCMain11Checksum m5 : 33|1@1+ (1,0) [0|1] "" Vector__XXX
 SG_ DPB_a331_EMCMain11Counter m5 : 34|1@1+ (1,0) [0|1] "" Vector__XXX
 SG_ DPB_a332_EMCMain11DLC m5 : 35|1@1+ (1,0) [0|1] "" Vector__XXX
 SG_ DPB_a333_EMCMain11Timeout m5 : 36|1@1+ (1,0) [0|1] "" Vector__XXX
 SG_ DPB_a334_EMCMain21Checksum m5 : 37|1@1+ (1,0) [0|1] "" Vector__XXX
 SG_ DPB_a335_EMCMain21Counter m5 : 38|1@1+ (1,0) [0|1] "" Vector__XXX
 SG_ DPB_a336_EMCMain21DLC m5 : 39|1@1+ (1,0) [0|1] "" Vector__XXX
 SG_ DPB_a337_EMCMain21Timeout m5 : 40|1@1+ (1,0) [0|1] "" Vector__XXX

BO_ 1592 EPAS3P_udsResponseCH: 8 EPAS3P
 SG_ EPAS3P_udsResponseDataCH : 7|64@0+ (1,0) [0|1.84467440737e+19] "" Vector__XXX

BO_ 1427 EPASTP_alertLog: 8 EPASTP
 SG_ EPASTP_alertID M : 0|9@1+ (1,0) [0|511] "" Vector__XXX
 SG_ EPASTP_alertState : 15|1@1+ (1,0) [0|1] "" Vector__XXX
 SG_ EPASTP_a001_debugInfo m1 : 16|48@1+ (1,0) [0|281474976710655] "" Vector__XXX
 SG_ EPASTP_a002_debugInfo m2 : 16|48@1+ (1,0) [0|281474976710655] "" Vector__XXX
 SG_ EPASTP_a003_debugInfo m3 : 16|48@1+ (1,0) [0|281474976710655] "" Vector__XXX
 SG_ EPASTP_a004_debugInfo m4 : 16|48@1+ (1,0) [0|281474976710655] "" Vector__XXX
 SG_ EPASTP_a005_debugInfo m5 : 16|48@1+ (1,0) [0|281474976710655] "" Vector__XXX
 SG_ EPASTP_a006_debugInfo m6 : 16|48@1+ (1,0) [0|281474976710655] "" Vector__XXX
 SG_ EPASTP_a007_debugInfo m7 : 16|48@1+ (1,0) [0|281474976710655] "" Vector__XXX
 SG_ EPASTP_a009_debugInfo m9 : 16|48@1+ (1,0) [0|281474976710655] "" Vector__XXX
 SG_ EPASTP_a010_debugInfo m10 : 16|48@1+ (1,0) [0|281474976710655] "" Vector__XXX
 SG_ EPASTP_a011_debugInfo m11 : 16|48@1+ (1,0) [0|281474976710655] "" Vector__XXX
 SG_ EPASTP_a012_debugInfo m12 : 16|48@1+ (1,0) [0|281474976710655] "" Vector__XXX
 SG_ EPASTP_a013_debugInfo m13 : 16|48@1+ (1,0) [0|281474976710655] "" Vector__XXX
 SG_ EPASTP_a014_debugInfo m14 : 16|48@1+ (1,0) [0|281474976710655] "" Vector__XXX
 SG_ EPASTP_a015_debugInfo m15 : 16|48@1+ (1,0) [0|281474976710655] "" Vector__XXX
 SG_ EPASTP_a016_debugInfo m16 : 16|48@1+ (1,0) [0|281474976710655] "" Vector__XXX
 SG_ EPASTP_a017_debugInfo m17 : 16|48@1+ (1,0) [0|281474976710655] "" Vector__XXX
 SG_ EPASTP_a018_debugInfo m18 : 16|48@1+ (1,0) [0|281474976710655] "" Vector__XXX
 SG_ EPASTP_a019_debugInfo m19 : 16|48@1+ (1,0) [0|281474976710655] "" Vector__XXX
 SG_ EPASTP_a020_debugInfo m20 : 16|48@1+ (1,0) [0|281474976710655] "" Vector__XXX
 SG_ EPASTP_a021_debugInfo m21 : 16|48@1+ (1,0) [0|281474976710655] "" Vector__XXX
 SG_ EPASTP_a022_debugInfo m22 : 16|48@1+ (1,0) [0|281474976710655] "" Vector__XXX
 SG_ EPASTP_a023_debugInfo m23 : 16|48@1+ (1,0) [0|281474976710655] "" Vector__XXX
 SG_ EPASTP_a024_debugInfo m24 : 16|48@1+ (1,0) [0|281474976710655] "" Vector__XXX
 SG_ EPASTP_a025_debugInfo m25 : 16|48@1+ (1,0) [0|281474976710655] "" Vector__XXX
 SG_ EPASTP_a026_debugInfo m26 : 16|48@1+ (1,0) [0|281474976710655] "" Vector__XXX
 SG_ EPASTP_a027_debugInfo m27 : 16|48@1+ (1,0) [0|281474976710655] "" Vector__XXX
 SG_ EPASTP_a028_debugInfo m28 : 16|48@1+ (1,0) [0|281474976710655] "" Vector__XXX
 SG_ EPASTP_a029_debugInfo m29 : 16|48@1+ (1,0) [0|281474976710655] "" Vector__XXX
 SG_ EPASTP_a030_debugInfo m30 : 16|48@1+ (1,0) [0|281474976710655] "" Vector__XXX
 SG_ EPASTP_a031_debugInfo m31 : 16|48@1+ (1,0) [0|281474976710655] "" Vector__XXX
 SG_ EPASTP_a032_debugInfo m32 : 16|48@1+ (1,0) [0|281474976710655] "" Vector__XXX
 SG_ EPASTP_a033_debugInfo m33 : 16|48@1+ (1,0) [0|281474976710655] "" Vector__XXX
 SG_ EPASTP_a034_debugInfo m34 : 16|48@1+ (1,0) [0|281474976710655] "" Vector__XXX
 SG_ EPASTP_a035_debugInfo m35 : 16|48@1+ (1,0) [0|281474976710655] "" Vector__XXX
 SG_ EPASTP_a036_debugInfo m36 : 16|48@1+ (1,0) [0|281474976710655] "" Vector__XXX
 SG_ EPASTP_a037_debugInfo m37 : 16|48@1+ (1,0) [0|281474976710655] "" Vector__XXX
 SG_ EPASTP_a038_debugInfo m38 : 16|48@1+ (1,0) [0|281474976710655] "" Vector__XXX
 SG_ EPASTP_a039_debugInfo m39 : 16|48@1+ (1,0) [0|281474976710655] "" Vector__XXX
 SG_ EPASTP_a040_debugInfo m40 : 16|48@1+ (1,0) [0|281474976710655] "" Vector__XXX
 SG_ EPASTP_a041_debugInfo m41 : 16|48@1+ (1,0) [0|281474976710655] "" Vector__XXX
 SG_ EPASTP_a042_debugInfo m42 : 16|48@1+ (1,0) [0|281474976710655] "" Vector__XXX
 SG_ EPASTP_a043_debugInfo m43 : 16|48@1+ (1,0) [0|281474976710655] "" Vector__XXX
 SG_ EPASTP_a044_debugInfo m44 : 16|48@1+ (1,0) [0|281474976710655] "" Vector__XXX
 SG_ EPASTP_a045_debugInfo m45 : 16|48@1+ (1,0) [0|281474976710655] "" Vector__XXX
 SG_ EPASTP_a046_debugInfo m46 : 16|48@1+ (1,0) [0|281474976710655] "" Vector__XXX
 SG_ EPASTP_a047_debugInfo m47 : 16|48@1+ (1,0) [0|281474976710655] "" Vector__XXX
 SG_ EPASTP_a048_debugInfo m48 : 16|48@1+ (1,0) [0|281474976710655] "" Vector__XXX
 SG_ EPASTP_a049_debugInfo m49 : 16|48@1+ (1,0) [0|281474976710655] "" Vector__XXX
 SG_ EPASTP_a050_debugInfo m50 : 16|48@1+ (1,0) [0|281474976710655] "" Vector__XXX
 SG_ EPASTP_a051_debugInfo m51 : 16|48@1+ (1,0) [0|281474976710655] "" Vector__XXX
 SG_ EPASTP_a052_debugInfo m52 : 16|48@1+ (1,0) [0|281474976710655] "" Vector__XXX
 SG_ EPASTP_a053_debugInfo m53 : 16|48@1+ (1,0) [0|281474976710655] "" Vector__XXX
 SG_ EPASTP_a054_debugInfo m54 : 16|48@1+ (1,0) [0|281474976710655] "" Vector__XXX
 SG_ EPASTP_a055_debugInfo m55 : 16|48@1+ (1,0) [0|281474976710655] "" Vector__XXX
 SG_ EPASTP_a056_debugInfo m56 : 16|48@1+ (1,0) [0|281474976710655] "" Vector__XXX
 SG_ EPASTP_a057_debugInfo m57 : 16|48@1+ (1,0) [0|281474976710655] "" Vector__XXX
 SG_ EPASTP_a058_debugInfo m58 : 16|48@1+ (1,0) [0|281474976710655] "" Vector__XXX
 SG_ EPASTP_a059_debugInfo m59 : 16|48@1+ (1,0) [0|281474976710655] "" Vector__XXX
 SG_ EPASTP_a060_debugInfo m60 : 16|48@1+ (1,0) [0|281474976710655] "" Vector__XXX
 SG_ EPASTP_a061_debugInfo m61 : 16|48@1+ (1,0) [0|281474976710655] "" Vector__XXX
 SG_ EPASTP_a062_debugInfo m62 : 16|48@1+ (1,0) [0|281474976710655] "" Vector__XXX
 SG_ EPASTP_a063_debugInfo m63 : 16|48@1+ (1,0) [0|281474976710655] "" Vector__XXX
 SG_ EPASTP_a064_debugInfo m64 : 16|48@1+ (1,0) [0|281474976710655] "" Vector__XXX
 SG_ EPASTP_a065_debugInfo m65 : 16|48@1+ (1,0) [0|281474976710655] "" Vector__XXX
 SG_ EPASTP_a066_debugInfo m66 : 16|48@1+ (1,0) [0|281474976710655] "" Vector__XXX
 SG_ EPASTP_a067_debugInfo m67 : 16|48@1+ (1,0) [0|281474976710655] "" Vector__XXX
 SG_ EPASTP_a068_debugInfo m68 : 16|48@1+ (1,0) [0|281474976710655] "" Vector__XXX
 SG_ EPASTP_a069_debugInfo m69 : 16|48@1+ (1,0) [0|281474976710655] "" Vector__XXX
 SG_ EPASTP_a070_debugInfo m70 : 16|48@1+ (1,0) [0|281474976710655] "" Vector__XXX
 SG_ EPASTP_a071_debugInfo m71 : 16|48@1+ (1,0) [0|281474976710655] "" Vector__XXX
 SG_ EPASTP_a072_debugInfo m72 : 16|48@1+ (1,0) [0|281474976710655] "" Vector__XXX
 SG_ EPASTP_a073_debugInfo m73 : 16|48@1+ (1,0) [0|281474976710655] "" Vector__XXX
 SG_ EPASTP_a074_debugInfo m74 : 16|48@1+ (1,0) [0|281474976710655] "" Vector__XXX
 SG_ EPASTP_a075_debugInfo m75 : 16|48@1+ (1,0) [0|281474976710655] "" Vector__XXX
 SG_ EPASTP_a076_debugInfo m76 : 16|48@1+ (1,0) [0|281474976710655] "" Vector__XXX
 SG_ EPASTP_a077_debugInfo m77 : 16|48@1+ (1,0) [0|281474976710655] "" Vector__XXX
 SG_ EPASTP_a078_debugInfo m78 : 16|48@1+ (1,0) [0|281474976710655] "" Vector__XXX
 SG_ EPASTP_a079_debugInfo m79 : 16|48@1+ (1,0) [0|281474976710655] "" Vector__XXX
 SG_ EPASTP_a080_debugInfo m80 : 16|48@1+ (1,0) [0|281474976710655] "" Vector__XXX
 SG_ EPASTP_a081_debugInfo m81 : 16|48@1+ (1,0) [0|281474976710655] "" Vector__XXX
 SG_ EPASTP_a082_debugInfo m82 : 16|48@1+ (1,0) [0|281474976710655] "" Vector__XXX
 SG_ EPASTP_a083_debugInfo m83 : 16|48@1+ (1,0) [0|281474976710655] "" Vector__XXX
 SG_ EPASTP_a084_debugInfo m84 : 16|48@1+ (1,0) [0|281474976710655] "" Vector__XXX
 SG_ EPASTP_a085_debugInfo m85 : 16|48@1+ (1,0) [0|281474976710655] "" Vector__XXX
 SG_ EPASTP_a086_debugInfo m86 : 16|48@1+ (1,0) [0|281474976710655] "" Vector__XXX
 SG_ EPASTP_a087_debugInfo m87 : 16|48@1+ (1,0) [0|281474976710655] "" Vector__XXX
 SG_ EPASTP_a088_debugInfo m88 : 16|48@1+ (1,0) [0|281474976710655] "" Vector__XXX
 SG_ EPASTP_a089_debugInfo m89 : 16|48@1+ (1,0) [0|281474976710655] "" Vector__XXX
 SG_ EPASTP_a090_debugInfo m90 : 16|48@1+ (1,0) [0|281474976710655] "" Vector__XXX
 SG_ EPASTP_a091_debugInfo m91 : 16|48@1+ (1,0) [0|281474976710655] "" Vector__XXX
 SG_ EPASTP_a092_debugInfo m92 : 16|48@1+ (1,0) [0|281474976710655] "" Vector__XXX
 SG_ EPASTP_a093_debugInfo m93 : 16|48@1+ (1,0) [0|281474976710655] "" Vector__XXX
 SG_ EPASTP_a094_debugInfo m94 : 16|48@1+ (1,0) [0|281474976710655] "" Vector__XXX
 SG_ EPASTP_a095_debugInfo m95 : 16|48@1+ (1,0) [0|281474976710655] "" Vector__XXX
 SG_ EPASTP_a096_debugInfo m96 : 16|48@1+ (1,0) [0|281474976710655] "" Vector__XXX
 SG_ EPASTP_a097_debugInfo m97 : 16|48@1+ (1,0) [0|281474976710655] "" Vector__XXX
 SG_ EPASTP_a098_debugInfo m98 : 16|48@1+ (1,0) [0|281474976710655] "" Vector__XXX
 SG_ EPASTP_a099_debugInfo m99 : 16|48@1+ (1,0) [0|281474976710655] "" Vector__XXX
 SG_ EPASTP_a100_debugInfo m100 : 16|48@1+ (1,0) [0|281474976710655] "" Vector__XXX
 SG_ EPASTP_a101_debugInfo m101 : 16|48@1+ (1,0) [0|281474976710655] "" Vector__XXX
 SG_ EPASTP_a102_debugInfo m102 : 16|48@1+ (1,0) [0|281474976710655] "" Vector__XXX
 SG_ EPASTP_a103_debugInfo m103 : 16|48@1+ (1,0) [0|281474976710655] "" Vector__XXX
 SG_ EPASTP_a104_debugInfo m104 : 16|48@1+ (1,0) [0|281474976710655] "" Vector__XXX
 SG_ EPASTP_a105_debugInfo m105 : 16|48@1+ (1,0) [0|281474976710655] "" Vector__XXX
 SG_ EPASTP_a106_debugInfo m106 : 16|48@1+ (1,0) [0|281474976710655] "" Vector__XXX
 SG_ EPASTP_a107_debugInfo m107 : 16|48@1+ (1,0) [0|281474976710655] "" Vector__XXX
 SG_ EPASTP_a108_debugInfo m108 : 16|48@1+ (1,0) [0|281474976710655] "" Vector__XXX
 SG_ EPASTP_a109_debugInfo m109 : 16|48@1+ (1,0) [0|281474976710655] "" Vector__XXX
 SG_ EPASTP_a110_debugInfo m110 : 16|48@1+ (1,0) [0|281474976710655] "" Vector__XXX
 SG_ EPASTP_a111_debugInfo m111 : 16|48@1+ (1,0) [0|281474976710655] "" Vector__XXX
 SG_ EPASTP_a112_debugInfo m112 : 16|48@1+ (1,0) [0|281474976710655] "" Vector__XXX
 SG_ EPASTP_a113_debugInfo m113 : 16|48@1+ (1,0) [0|281474976710655] "" Vector__XXX
 SG_ EPASTP_a114_debugInfo m114 : 16|48@1+ (1,0) [0|281474976710655] "" Vector__XXX
 SG_ EPASTP_a115_debugInfo m115 : 16|48@1+ (1,0) [0|281474976710655] "" Vector__XXX
 SG_ EPASTP_a116_debugInfo m116 : 16|48@1+ (1,0) [0|281474976710655] "" Vector__XXX
 SG_ EPASTP_a117_debugInfo m117 : 16|48@1+ (1,0) [0|281474976710655] "" Vector__XXX
 SG_ EPASTP_a118_debugInfo m118 : 16|48@1+ (1,0) [0|281474976710655] "" Vector__XXX
 SG_ EPASTP_a119_debugInfo m119 : 16|48@1+ (1,0) [0|281474976710655] "" Vector__XXX
 SG_ EPASTP_a120_debugInfo m120 : 16|48@1+ (1,0) [0|281474976710655] "" Vector__XXX
 SG_ EPASTP_a121_debugInfo m121 : 16|48@1+ (1,0) [0|281474976710655] "" Vector__XXX
 SG_ EPASTP_a122_debugInfo m122 : 16|48@1+ (1,0) [0|281474976710655] "" Vector__XXX
 SG_ EPASTP_a123_debugInfo m123 : 16|48@1+ (1,0) [0|281474976710655] "" Vector__XXX
 SG_ EPASTP_a124_debugInfo m124 : 16|48@1+ (1,0) [0|281474976710655] "" Vector__XXX
 SG_ EPASTP_a125_debugInfo m125 : 16|48@1+ (1,0) [0|281474976710655] "" Vector__XXX
 SG_ EPASTP_a126_debugInfo m126 : 16|48@1+ (1,0) [0|281474976710655] "" Vector__XXX
 SG_ EPASTP_a127_debugInfo m127 : 16|48@1+ (1,0) [0|281474976710655] "" Vector__XXX
 SG_ EPASTP_a128_debugInfo m128 : 16|48@1+ (1,0) [0|281474976710655] "" Vector__XXX
 SG_ EPASTP_a129_debugInfo m129 : 16|48@1+ (1,0) [0|281474976710655] "" Vector__XXX
 SG_ EPASTP_a130_debugInfo m130 : 16|48@1+ (1,0) [0|281474976710655] "" Vector__XXX
 SG_ EPASTP_a131_debugInfo m131 : 16|48@1+ (1,0) [0|281474976710655] "" Vector__XXX
 SG_ EPASTP_a132_debugInfo m132 : 16|48@1+ (1,0) [0|281474976710655] "" Vector__XXX
 SG_ EPASTP_a133_debugInfo m133 : 16|48@1+ (1,0) [0|281474976710655] "" Vector__XXX
 SG_ EPASTP_a134_debugInfo m134 : 16|48@1+ (1,0) [0|281474976710655] "" Vector__XXX
 SG_ EPASTP_a135_debugInfo m135 : 16|48@1+ (1,0) [0|281474976710655] "" Vector__XXX
 SG_ EPASTP_a136_debugInfo m136 : 16|48@1+ (1,0) [0|281474976710655] "" Vector__XXX
 SG_ EPASTP_a137_debugInfo m137 : 16|48@1+ (1,0) [0|281474976710655] "" Vector__XXX
 SG_ EPASTP_a138_debugInfo m138 : 16|48@1+ (1,0) [0|281474976710655] "" Vector__XXX
 SG_ EPASTP_a139_debugInfo m139 : 16|48@1+ (1,0) [0|281474976710655] "" Vector__XXX
 SG_ EPASTP_a140_debugInfo m140 : 16|48@1+ (1,0) [0|281474976710655] "" Vector__XXX
 SG_ EPASTP_a141_debugInfo m141 : 16|48@1+ (1,0) [0|281474976710655] "" Vector__XXX
 SG_ EPASTP_a142_debugInfo m142 : 16|48@1+ (1,0) [0|281474976710655] "" Vector__XXX
 SG_ EPASTP_a143_debugInfo m143 : 16|48@1+ (1,0) [0|281474976710655] "" Vector__XXX
 SG_ EPASTP_a144_debugInfo m144 : 16|48@1+ (1,0) [0|281474976710655] "" Vector__XXX
 SG_ EPASTP_a145_debugInfo m145 : 16|48@1+ (1,0) [0|281474976710655] "" Vector__XXX
 SG_ EPASTP_a146_debugInfo m146 : 16|48@1+ (1,0) [0|281474976710655] "" Vector__XXX
 SG_ EPASTP_a147_debugInfo m147 : 16|48@1+ (1,0) [0|281474976710655] "" Vector__XXX
 SG_ EPASTP_a148_debugInfo m148 : 16|48@1+ (1,0) [0|281474976710655] "" Vector__XXX
 SG_ EPASTP_a149_debugInfo m149 : 16|48@1+ (1,0) [0|281474976710655] "" Vector__XXX
 SG_ EPASTP_a150_debugInfo m150 : 16|48@1+ (1,0) [0|281474976710655] "" Vector__XXX
 SG_ EPASTP_a152_debugInfo m152 : 16|48@1+ (1,0) [0|281474976710655] "" Vector__XXX
 SG_ EPASTP_a153_debugInfo m153 : 16|48@1+ (1,0) [0|281474976710655] "" Vector__XXX
 SG_ EPASTP_a154_debugInfo m154 : 16|48@1+ (1,0) [0|281474976710655] "" Vector__XXX
 SG_ EPASTP_a155_debugInfo m155 : 16|48@1+ (1,0) [0|281474976710655] "" Vector__XXX
 SG_ EPASTP_a156_debugInfo m156 : 16|48@1+ (1,0) [0|281474976710655] "" Vector__XXX
 SG_ EPASTP_a157_debugInfo m157 : 16|48@1+ (1,0) [0|281474976710655] "" Vector__XXX
 SG_ EPASTP_a158_debugInfo m158 : 16|48@1+ (1,0) [0|281474976710655] "" Vector__XXX
 SG_ EPASTP_a159_debugInfo m159 : 16|48@1+ (1,0) [0|281474976710655] "" Vector__XXX
 SG_ EPASTP_a160_debugInfo m160 : 16|48@1+ (1,0) [0|281474976710655] "" Vector__XXX
 SG_ EPASTP_a161_debugInfo m161 : 16|48@1+ (1,0) [0|281474976710655] "" Vector__XXX
 SG_ EPASTP_a162_debugInfo m162 : 16|48@1+ (1,0) [0|281474976710655] "" Vector__XXX
 SG_ EPASTP_a163_debugInfo m163 : 16|48@1+ (1,0) [0|281474976710655] "" Vector__XXX
 SG_ EPASTP_a164_debugInfo m164 : 16|48@1+ (1,0) [0|281474976710655] "" Vector__XXX
 SG_ EPASTP_a165_debugInfo m165 : 16|48@1+ (1,0) [0|281474976710655] "" Vector__XXX
 SG_ EPASTP_a166_debugInfo m166 : 16|48@1+ (1,0) [0|281474976710655] "" Vector__XXX
 SG_ EPASTP_a167_debugInfo m167 : 16|48@1+ (1,0) [0|281474976710655] "" Vector__XXX
 SG_ EPASTP_a168_debugInfo m168 : 16|48@1+ (1,0) [0|281474976710655] "" Vector__XXX
 SG_ EPASTP_a169_debugInfo m169 : 16|48@1+ (1,0) [0|281474976710655] "" Vector__XXX
 SG_ EPASTP_a170_debugInfo m170 : 16|48@1+ (1,0) [0|281474976710655] "" Vector__XXX
 SG_ EPASTP_a171_debugInfo m171 : 16|48@1+ (1,0) [0|281474976710655] "" Vector__XXX
 SG_ EPASTP_a172_debugInfo m172 : 16|48@1+ (1,0) [0|281474976710655] "" Vector__XXX
 SG_ EPASTP_a173_debugInfo m173 : 16|48@1+ (1,0) [0|281474976710655] "" Vector__XXX
 SG_ EPASTP_a174_debugInfo m174 : 16|48@1+ (1,0) [0|281474976710655] "" Vector__XXX
 SG_ EPASTP_a175_debugInfo m175 : 16|48@1+ (1,0) [0|281474976710655] "" Vector__XXX
 SG_ EPASTP_a176_debugInfo m176 : 16|48@1+ (1,0) [0|281474976710655] "" Vector__XXX
 SG_ EPASTP_a177_debugInfo m177 : 16|48@1+ (1,0) [0|281474976710655] "" Vector__XXX
 SG_ EPASTP_a178_debugInfo m178 : 16|48@1+ (1,0) [0|281474976710655] "" Vector__XXX
 SG_ EPASTP_a179_debugInfo m179 : 16|48@1+ (1,0) [0|281474976710655] "" Vector__XXX
 SG_ EPASTP_a180_debugInfo m180 : 16|48@1+ (1,0) [0|281474976710655] "" Vector__XXX
 SG_ EPASTP_a181_debugInfo m181 : 16|48@1+ (1,0) [0|281474976710655] "" Vector__XXX
 SG_ EPASTP_a182_debugInfo m182 : 16|48@1+ (1,0) [0|281474976710655] "" Vector__XXX
 SG_ EPASTP_a183_debugInfo m183 : 16|48@1+ (1,0) [0|281474976710655] "" Vector__XXX
 SG_ EPASTP_a184_debugInfo m184 : 16|48@1+ (1,0) [0|281474976710655] "" Vector__XXX
 SG_ EPASTP_a185_debugInfo m185 : 16|48@1+ (1,0) [0|281474976710655] "" Vector__XXX
 SG_ EPASTP_a186_debugInfo m186 : 16|48@1+ (1,0) [0|281474976710655] "" Vector__XXX
 SG_ EPASTP_a188_debugInfo m188 : 16|48@1+ (1,0) [0|281474976710655] "" Vector__XXX
 SG_ EPASTP_a189_debugInfo m189 : 16|48@1+ (1,0) [0|281474976710655] "" Vector__XXX
 SG_ EPASTP_a190_debugInfo m190 : 16|48@1+ (1,0) [0|281474976710655] "" Vector__XXX
 SG_ EPASTP_a191_debugInfo m191 : 16|48@1+ (1,0) [0|281474976710655] "" Vector__XXX
 SG_ EPASTP_a192_debugInfo m192 : 16|48@1+ (1,0) [0|281474976710655] "" Vector__XXX
 SG_ EPASTP_a193_debugInfo m193 : 16|48@1+ (1,0) [0|281474976710655] "" Vector__XXX
 SG_ EPASTP_a194_debugInfo m194 : 16|48@1+ (1,0) [0|281474976710655] "" Vector__XXX
 SG_ EPASTP_a195_debugInfo m195 : 16|48@1+ (1,0) [0|281474976710655] "" Vector__XXX
 SG_ EPASTP_a196_debugInfo m196 : 16|48@1+ (1,0) [0|281474976710655] "" Vector__XXX
 SG_ EPASTP_a197_debugInfo m197 : 16|48@1+ (1,0) [0|281474976710655] "" Vector__XXX
 SG_ EPASTP_a198_debugInfo m198 : 16|48@1+ (1,0) [0|281474976710655] "" Vector__XXX
 SG_ EPASTP_a199_debugInfo m199 : 16|48@1+ (1,0) [0|281474976710655] "" Vector__XXX
 SG_ EPASTP_a200_debugInfo m200 : 16|48@1+ (1,0) [0|281474976710655] "" Vector__XXX
 SG_ EPASTP_a201_debugInfo m201 : 16|48@1+ (1,0) [0|281474976710655] "" Vector__XXX
 SG_ EPASTP_a202_debugInfo m202 : 16|48@1+ (1,0) [0|281474976710655] "" Vector__XXX
 SG_ EPASTP_a203_debugInfo m203 : 16|48@1+ (1,0) [0|281474976710655] "" Vector__XXX
 SG_ EPASTP_a204_debugInfo m204 : 16|48@1+ (1,0) [0|281474976710655] "" Vector__XXX
 SG_ EPASTP_a205_debugInfo m205 : 16|48@1+ (1,0) [0|281474976710655] "" Vector__XXX
 SG_ EPASTP_a206_debugInfo m206 : 16|48@1+ (1,0) [0|281474976710655] "" Vector__XXX
 SG_ EPASTP_a207_debugInfo m207 : 16|48@1+ (1,0) [0|281474976710655] "" Vector__XXX
 SG_ EPASTP_a208_debugInfo m208 : 16|48@1+ (1,0) [0|281474976710655] "" Vector__XXX
 SG_ EPASTP_a209_debugInfo m209 : 16|48@1+ (1,0) [0|281474976710655] "" Vector__XXX
 SG_ EPASTP_a210_debugInfo m210 : 16|48@1+ (1,0) [0|281474976710655] "" Vector__XXX
 SG_ EPASTP_a211_debugInfo m211 : 16|48@1+ (1,0) [0|281474976710655] "" Vector__XXX
 SG_ EPASTP_a212_debugInfo m212 : 16|48@1+ (1,0) [0|281474976710655] "" Vector__XXX
 SG_ EPASTP_a213_debugInfo m213 : 16|48@1+ (1,0) [0|281474976710655] "" Vector__XXX
 SG_ EPASTP_a214_debugInfo m214 : 16|48@1+ (1,0) [0|281474976710655] "" Vector__XXX
 SG_ EPASTP_a215_debugInfo m215 : 16|48@1+ (1,0) [0|281474976710655] "" Vector__XXX
 SG_ EPASTP_a216_debugInfo m216 : 16|48@1+ (1,0) [0|281474976710655] "" Vector__XXX
 SG_ EPASTP_a217_debugInfo m217 : 16|48@1+ (1,0) [0|281474976710655] "" Vector__XXX
 SG_ EPASTP_a218_debugInfo m218 : 16|48@1+ (1,0) [0|281474976710655] "" Vector__XXX
 SG_ EPASTP_a219_debugInfo m219 : 16|48@1+ (1,0) [0|281474976710655] "" Vector__XXX
 SG_ EPASTP_a221_debugInfo m221 : 16|48@1+ (1,0) [0|281474976710655] "" Vector__XXX
 SG_ EPASTP_a222_debugInfo m222 : 16|48@1+ (1,0) [0|281474976710655] "" Vector__XXX
 SG_ EPASTP_a223_debugInfo m223 : 16|48@1+ (1,0) [0|281474976710655] "" Vector__XXX
 SG_ EPASTP_a224_debugInfo m224 : 16|48@1+ (1,0) [0|281474976710655] "" Vector__XXX
 SG_ EPASTP_a225_debugInfo m225 : 16|48@1+ (1,0) [0|281474976710655] "" Vector__XXX
 SG_ EPASTP_a226_debugInfo m226 : 16|48@1+ (1,0) [0|281474976710655] "" Vector__XXX
 SG_ EPASTP_a227_debugInfo m227 : 16|48@1+ (1,0) [0|281474976710655] "" Vector__XXX
 SG_ EPASTP_a228_debugInfo m228 : 16|48@1+ (1,0) [0|281474976710655] "" Vector__XXX
 SG_ EPASTP_a229_debugInfo m229 : 16|48@1+ (1,0) [0|281474976710655] "" Vector__XXX
 SG_ EPASTP_a230_debugInfo m230 : 16|48@1+ (1,0) [0|281474976710655] "" Vector__XXX
 SG_ EPASTP_a231_debugInfo m231 : 16|48@1+ (1,0) [0|281474976710655] "" Vector__XXX
 SG_ EPASTP_a232_debugInfo m232 : 16|48@1+ (1,0) [0|281474976710655] "" Vector__XXX
 SG_ EPASTP_a233_debugInfo m233 : 16|48@1+ (1,0) [0|281474976710655] "" Vector__XXX
 SG_ EPASTP_a234_debugInfo m234 : 16|48@1+ (1,0) [0|281474976710655] "" Vector__XXX
 SG_ EPASTP_a235_debugInfo m235 : 16|48@1+ (1,0) [0|281474976710655] "" Vector__XXX
 SG_ EPASTP_a236_debugInfo m236 : 16|48@1+ (1,0) [0|281474976710655] "" Vector__XXX
 SG_ EPASTP_a237_debugInfo m237 : 16|48@1+ (1,0) [0|281474976710655] "" Vector__XXX
 SG_ EPASTP_a238_debugInfo m238 : 16|48@1+ (1,0) [0|281474976710655] "" Vector__XXX
 SG_ EPASTP_a239_debugInfo m239 : 16|48@1+ (1,0) [0|281474976710655] "" Vector__XXX
 SG_ EPASTP_a240_debugInfo m240 : 16|48@1+ (1,0) [0|281474976710655] "" Vector__XXX
 SG_ EPASTP_a241_debugInfo m241 : 16|48@1+ (1,0) [0|281474976710655] "" Vector__XXX
 SG_ EPASTP_a242_debugInfo m242 : 16|48@1+ (1,0) [0|281474976710655] "" Vector__XXX
 SG_ EPASTP_a243_debugInfo m243 : 16|48@1+ (1,0) [0|281474976710655] "" Vector__XXX
 SG_ EPASTP_a244_debugInfo m244 : 16|48@1+ (1,0) [0|281474976710655] "" Vector__XXX
 SG_ EPASTP_a245_debugInfo m245 : 16|48@1+ (1,0) [0|281474976710655] "" Vector__XXX
 SG_ EPASTP_a246_debugInfo m246 : 16|48@1+ (1,0) [0|281474976710655] "" Vector__XXX
 SG_ EPASTP_a247_debugInfo m247 : 16|48@1+ (1,0) [0|281474976710655] "" Vector__XXX
 SG_ EPASTP_a248_debugInfo m248 : 16|48@1+ (1,0) [0|281474976710655] "" Vector__XXX
 SG_ EPASTP_a249_debugInfo m249 : 16|48@1+ (1,0) [0|281474976710655] "" Vector__XXX
 SG_ EPASTP_a250_debugInfo m250 : 16|48@1+ (1,0) [0|281474976710655] "" Vector__XXX
 SG_ EPASTP_a252_debugInfo m252 : 16|48@1+ (1,0) [0|281474976710655] "" Vector__XXX
 SG_ EPASTP_a253_debugInfo m253 : 16|48@1+ (1,0) [0|281474976710655] "" Vector__XXX
 SG_ EPASTP_a254_debugInfo m254 : 16|48@1+ (1,0) [0|281474976710655] "" Vector__XXX
 SG_ EPASTP_a255_debugInfo m255 : 16|48@1+ (1,0) [0|281474976710655] "" Vector__XXX
 SG_ EPASTP_a256_debugInfo m256 : 16|48@1+ (1,0) [0|281474976710655] "" Vector__XXX
 SG_ EPASTP_a257_debugInfo m257 : 16|48@1+ (1,0) [0|281474976710655] "" Vector__XXX
 SG_ EPASTP_a258_debugInfo m258 : 16|48@1+ (1,0) [0|281474976710655] "" Vector__XXX
 SG_ EPASTP_a259_debugInfo m259 : 16|48@1+ (1,0) [0|281474976710655] "" Vector__XXX
 SG_ EPASTP_a260_debugInfo m260 : 16|48@1+ (1,0) [0|281474976710655] "" Vector__XXX
 SG_ EPASTP_a261_debugInfo m261 : 16|48@1+ (1,0) [0|281474976710655] "" Vector__XXX
 SG_ EPASTP_a262_debugInfo m262 : 16|48@1+ (1,0) [0|281474976710655] "" Vector__XXX
 SG_ EPASTP_a263_debugInfo m263 : 16|48@1+ (1,0) [0|281474976710655] "" Vector__XXX
 SG_ EPASTP_a264_degradedECU m264 : 16|8@1+ (1,0) [0|255] "" Vector__XXX
 SG_ EPASTP_a264_vehicleSpeed m264 : 24|16@1+ (0.1,0) [0|6553.5] "kph" Vector__XXX
 SG_ EPASTP_a264_powerRatio m264 : 40|8@1+ (1,0) [0|255] "percent" Vector__XXX
 SG_ EPASTP_a264_ownSideDegradationRe m264 : 48|8@1+ (1,0) [0|255] "" Vector__XXX
 SG_ EPASTP_a264_otherSideDegradation m264 : 56|8@1+ (1,0) [0|255] "" Vector__XXX
 SG_ EPASTP_a265_degradedECU m265 : 16|8@1+ (1,0) [0|255] "" Vector__XXX
 SG_ EPASTP_a265_vehicleSpeed m265 : 24|16@1+ (0.1,0) [0|6553.5] "kph" Vector__XXX
 SG_ EPASTP_a265_rawMcuTemperature m265 : 40|16@1+ (1,-100) [-100|65435] "C" Vector__XXX
 SG_ EPASTP_a265_degradedCurrentLimit m265 : 56|8@1+ (1,0) [0|255] "A" Vector__XXX
 SG_ EPASTP_a266_cdpAssistFactor m266 : 16|8@1+ (1,0) [0|255] "percent" Vector__XXX
 SG_ EPASTP_a266_vehicleSpeed m266 : 24|16@1+ (0.1,0) [0|6553.5] "kph" Vector__XXX
 SG_ EPASTP_a267_vehicleSpeed m267 : 16|16@1+ (0.1,0) [0|6553.5] "kph" Vector__XXX
 SG_ EPASTP_a267_velocityEstimatorSta m267 : 32|8@1+ (1,0) [0|255] "" Vector__XXX
 SG_ EPASTP_a269_vehicleSpeed m269 : 16|16@1+ (0.1,0) [0|6553.5] "kph" Vector__XXX
 SG_ EPASTP_a270_debugInfo m270 : 16|48@1+ (1,0) [0|281474976710655] "" Vector__XXX

BO_TX_BU_ 942 : APSB;
BO_TX_BU_ 976 : APSB;
BO_TX_BU_ 1003 : APSB;
BO_TX_BU_ 943 : BB;
BO_TX_BU_ 551 : CMP;
BO_TX_BU_ 778 : DAS;
BO_TX_BU_ 781 : DAS;
BO_TX_BU_ 1548 : DAS;
BO_TX_BU_ 1237 : DPB;
BO_TX_BU_ 999 : DPB;
BO_TX_BU_ 1592 : EPAS3P;
BO_TX_BU_ 1427 : EPASTP;
CM_ BO_ 942 "APSB ECU message: warning matrix2";
CM_ SG_ 942 APSB_w129_ECU_Power_Issue "APSB ECU: w129 ECU power issue";
CM_ SG_ 942 APSB_w130_ECU_Thermal_Issue "APSB ECU: w130 ECU thermal issue";
CM_ SG_ 942 APSB_w131_trap_exception "APSB ECU: w131 trap exception";
CM_ SG_ 942 APSB_w132_appVersionMismatch "APSB ECU: w132 app version mismatch";
CM_ SG_ 942 APSB_w133_ETHSwitchError "APSB ECU: w133 ETH switch error";
CM_ SG_ 942 APSB_w134_appMia "APSB ECU: w134 app mia";
CM_ SG_ 942 APSB_w135_appCritical "APSB ECU: w135 app critical";
CM_ SG_ 942 APSB_w136_gpsDisabled "APSB ECU: w136 gps disabled";
CM_ SG_ 942 APSB_w137_gpsFaultReset "APSB ECU: w137 gps fault reset";
CM_ SG_ 942 APSB_w138_gpsComIssue "APSB ECU: w138 gps com issue";
CM_ SG_ 942 APSB_w139_udpBufferOverflow "APSB ECU: w139 udp buffer overflow";
CM_ SG_ 942 APSB_w140_vcfrontMiaVehicleBus "APSB ECU: w140 vcfront mia vehicle bus";
CM_ SG_ 942 APSB_w141_rcmMiaPartyBus "APSB ECU: w141 rcm mia party bus";
CM_ SG_ 942 APSB_w142_diMiaPartyBus "APSB ECU: w142 di mia party bus";
CM_ SG_ 942 APSB_w143_espMiaPartyBus "APSB ECU: w143 esp mia party bus";
CM_ SG_ 942 APSB_w144_vcleftMiaPartyBus "APSB ECU: w144 vcleft mia party bus";
CM_ SG_ 942 APSB_w145_vcrightMiaPartyBus "APSB ECU: w145 vcright mia party bus";
CM_ SG_ 942 APSB_w146_epas3pMiaPartyBus "APSB ECU: w146 epas3p mia party bus";
CM_ SG_ 942 APSB_w147_vcleftMiaVehBus "APSB ECU: w147 vcleft mia veh bus";
CM_ SG_ 942 APSB_w148_vcrightMiaVehBus "APSB ECU: w148 vcright mia veh bus";
CM_ SG_ 942 APSB_w149_epblMiaVehBus "APSB ECU: w149 epbl mia veh bus";
CM_ SG_ 942 APSB_w150_sccmMiaVehBus "APSB ECU: w150 sccm mia veh bus";
CM_ SG_ 942 APSB_w151_apRecovered "APSB ECU: w151 ap recovered";
CM_ SG_ 942 APSB_w152_gpsFusionStatus "APSB ECU: w152 gps fusion status";
CM_ SG_ 942 APSB_w153_eacInhibit "APSB ECU: w153 eac inhibit";
CM_ SG_ 942 APSB_w155_ethLwipError "APSB ECU: w155 eth lwip error";
CM_ SG_ 942 APSB_w156_lwipAssert "APSB ECU: w156 lwip assert";
CM_ SG_ 942 APSB_w157_autopilotReboot "APSB ECU: w157 autopilot reboot";
CM_ SG_ 942 APSB_w158_apbMia "APSB ECU: w158 apb mia";
CM_ SG_ 942 APSB_w159_apbCritical "APSB ECU: w159 apb critical";
CM_ SG_ 942 APSB_w160_apbVersionMismatch "APSB ECU: w160 apb version mismatch";
CM_ SG_ 942 APSB_w161_gpsAntennaDisconnected "APSB ECU: w161 gps antenna disconnected";
CM_ SG_ 942 APSB_w162_TurboA_DisRegPgoodErr "APSB ECU: w162 turbo a dis reg pgood err";
CM_ SG_ 942 APSB_w163_TurboA_DisRegNFault "APSB ECU: w163 turbo a dis reg n fault";
CM_ SG_ 942 APSB_w164_TurboA_12VFuseFault "APSB ECU: w164 turbo a 12 v fuse fault";
CM_ SG_ 942 APSB_w165_TurboA_Temp_NOS "APSB ECU: w165 turbo a temp NOS";
CM_ SG_ 942 APSB_w166_TurboA_SMSLockStepErr "APSB ECU: w166 turbo a SMS lock step err";
CM_ SG_ 942 APSB_w167_TurboA_TMU_Throttle "APSB ECU: w167 turbo a TMU throttle";
CM_ SG_ 942 APSB_w168_TurboA_SMS_WDOG "APSB ECU: w168 turbo a SMS WDOG";
CM_ SG_ 942 APSB_w169_TurboA_SCS_LKUP "APSB ECU: w169 turbo a SCS LKUP";
CM_ SG_ 942 APSB_w170_TurboA_A72_watchdog "APSB ECU: w170 turbo a A72 watchdog";
CM_ SG_ 942 APSB_w171_TurboA_SMS_taskUtilErr "APSB ECU: w171 turbo a SMS task util err";
CM_ SG_ 942 APSB_w172_apFeaturesUnavailable "APSB ECU: w172 ap features unavailable";
CM_ SG_ 942 APSB_w178_TurboB_DisRegPgoodErr "APSB ECU: w178 turbo b dis reg pgood err";
CM_ SG_ 942 APSB_w179_TurboB_DisRegNFault "APSB ECU: w179 turbo b dis reg n fault";
CM_ SG_ 942 APSB_w180_TurboB_12VFuseFault "APSB ECU: w180 turbo b 12 v fuse fault";
CM_ SG_ 942 APSB_w181_TurboB_Temp_NOS "APSB ECU: w181 turbo b temp NOS";
CM_ SG_ 942 APSB_w182_TurboB_SMSLockStepErr "APSB ECU: w182 turbo b SMS lock step err";
CM_ SG_ 942 APSB_w183_TurboB_TMU_Throttle "APSB ECU: w183 turbo b TMU throttle";
CM_ SG_ 942 APSB_w184_TurboB_SMS_WDOG "APSB ECU: w184 turbo b SMS WDOG";
CM_ SG_ 942 APSB_w185_TurboB_SCS_LKUP "APSB ECU: w185 turbo b SCS LKUP";
CM_ SG_ 942 APSB_w186_TurboB_A72_watchdog "APSB ECU: w186 turbo b A72 watchdog";
CM_ SG_ 942 APSB_w187_TurboB_SMS_taskUtilErr "APSB ECU: w187 turbo b SMS task util err";
CM_ SG_ 942 APSB_w188_otherTurboUartMIA "APSB ECU: w188 other turbo uart MIA";
CM_ SG_ 942 APSB_w189_vcfrontMiaPartyBus "APSB ECU: w189 vcfront mia party bus";
CM_ SG_ 942 APSB_w190_iboosterMia "APSB ECU: w190 ibooster mia";
CM_ SG_ 942 APSB_w191_timesyncError "APSB ECU: w191 timesync error";
CM_ SG_ 942 APSB_w192_CANFault "APSB ECU: w192 CAN fault";
CM_ BO_ 976 "APSB ECU message: warning matrix3";
CM_ SG_ 976 APSB_w193_camWindshieldUnclean "APSB ECU: w193 cam windshield unclean";
CM_ SG_ 976 APSB_w194_accDriverResumeRqrd "APSB ECU: w194 acc driver resume rqrd";
CM_ SG_ 976 APSB_w195_scwUnavailable "APSB ECU: w195 scw unavailable";
CM_ SG_ 976 APSB_w196_stopSignWarning "APSB ECU: w196 stop sign warning";
CM_ SG_ 976 APSB_w197_redLightWarning "APSB ECU: w197 red light warning";
CM_ SG_ 976 APSB_w198_tsrUnavailable "APSB ECU: w198 tsr unavailable";
CM_ SG_ 976 APSB_w199_apcAbort "APSB ECU: w199 apc abort";
CM_ SG_ 976 APSB_w200_lcSlowdown "APSB ECU: w200 lc slowdown";
CM_ SG_ 976 APSB_w201_lcAborting "APSB ECU: w201 lc aborting";
CM_ SG_ 976 APSB_w202_scwNoisyEnvironment "APSB ECU: w202 scw noisy environment";
CM_ SG_ 976 APSB_w203_apcActivation "APSB ECU: w203 apc activation";
CM_ SG_ 976 APSB_w204_apcFinalFront "APSB ECU: w204 apc final front";
CM_ SG_ 976 APSB_w205_apcFinalRear "APSB ECU: w205 apc final rear";
CM_ SG_ 976 APSB_w206_autosteerNotEnabled "APSB ECU: w206 autosteer not enabled";
CM_ SG_ 976 APSB_w207_autosteerUnavailable "APSB ECU: w207 autosteer unavailable";
CM_ SG_ 976 APSB_w208_rackDetected "APSB ECU: w208 rack detected";
CM_ SG_ 976 APSB_w209_autoSummonRequest "APSB ECU: w209 auto summon request";
CM_ SG_ 976 APSB_w210_camObstrcted "APSB ECU: w210 cam obstrcted";
CM_ SG_ 976 APSB_w211_accNoSeatBelt "APSB ECU: w211 acc no seat belt";
CM_ SG_ 976 APSB_w212_lcUnavailableStrikeOut "APSB ECU: w212 lc unavailable strike out";
CM_ SG_ 976 APSB_w213_autosteerStruckOut "APSB ECU: w213 autosteer struck out";
CM_ SG_ 976 APSB_w214_driverNotIntracting "APSB ECU: w214 driver not intracting";
CM_ SG_ 976 APSB_w215_contDriverNotIntractin "APSB ECU: w215 cont driver not intracting";
CM_ SG_ 976 APSB_w216_driverOverriding "APSB ECU: w216 driver overriding";
CM_ SG_ 976 APSB_w217_lcUnavailableSpeeding "APSB ECU: w217 lc unavailable speeding";
CM_ SG_ 976 APSB_w218_lcSpeedExceededLimit "APSB ECU: w218 lc speed exceeded limit";
CM_ SG_ 976 APSB_w219_lcTempUnavailableSpeed "APSB ECU: w219 lc temp unavailable speed";
CM_ SG_ 976 APSB_w220_lcTempUnavailableRoad "APSB ECU: w220 lc temp unavailable road";
CM_ SG_ 976 APSB_w221_accRadarBlind "APSB ECU: w221 acc radar blind";
CM_ SG_ 976 APSB_w222_accCameraBlind "APSB ECU: w222 acc camera blind";
CM_ SG_ 976 APSB_w223_accObjectInPath "APSB ECU: w223 acc object in path";
CM_ SG_ 976 APSB_w224_accCameraCalibration "APSB ECU: w224 acc camera calibration";
CM_ SG_ 976 APSB_w225_lcDegradedVisSpeedLmt "APSB ECU: w225 lc degraded vis speed lmt";
CM_ SG_ 976 APSB_w226_lcCamCalNeededSpeedLmt "APSB ECU: w226 lc cam cal needed speed lmt";
CM_ SG_ 976 APSB_w227_virtualWallBlocked "APSB ECU: w227 virtual wall blocked";
CM_ SG_ 976 APSB_w228_DEPRECATED "APSB ECU: w228 DEPRECATED";
CM_ SG_ 976 APSB_w229_alcUltrasoundDamaged "APSB ECU: w229 alc ultrasound damaged";
CM_ SG_ 976 APSB_w230_alcUltrasoundBlocked "APSB ECU: w230 alc ultrasound blocked";
CM_ SG_ 976 APSB_w231_idfEvent "APSB ECU: w231 idf event";
CM_ SG_ 976 APSB_w232_laneChangeRequested "APSB ECU: w232 lane change requested";
CM_ SG_ 976 APSB_w235_a72LoopDetected "APSB ECU: w235 a72 loop detected";
CM_ SG_ 976 APSB_w236_canSharedMemError "APSB ECU: w236 can shared mem error";
CM_ SG_ 976 APSB_w237_faultMgrEventDetected "APSB ECU: w237 fault mgr event detected";
CM_ SG_ 976 APSB_w238_resetReason "APSB ECU: w238 reset reason";
CM_ SG_ 976 APSB_w241_ddrInitFailures "APSB ECU: w241 ddr init failures";
CM_ SG_ 976 APSB_w242_tripMBISTFailure "APSB ECU: w242 trip MBIST failure";
CM_ SG_ 976 APSB_w243_tripHWErrorStatus "APSB ECU: w243 trip HW error status";
CM_ SG_ 976 APSB_w244_gpuHWFaultStatus "APSB ECU: w244 gpu HW fault status";
CM_ SG_ 976 APSB_w245_eloopRxFromUnexpectedS "APSB ECU: w245 eloop rx from unexpected source MAC";
CM_ SG_ 976 APSB_w246_ethloopSwitchPortLinkD "APSB ECU: w246 ethloop switch port link down";
CM_ SG_ 976 APSB_w247_ethernetFrameError "APSB ECU: w247 ethernet frame error";
CM_ SG_ 976 APSB_w248_ethloopSwitchPoorSqi "APSB ECU: w248 ethloop switch poor sqi";
CM_ SG_ 976 APSB_w249_ufsFailures "APSB ECU: w249 ufs failures";
CM_ SG_ 976 APSB_w250_ethloopSwitchMemUsageT "APSB ECU: w250 ethloop switch mem usage too high port2";
CM_ SG_ 976 APSB_w251_ethloopSwitchMemUsageT "APSB ECU: w251 ethloop switch mem usage too high port3";
CM_ SG_ 976 APSB_w252_ethSwitchPortLinkDown "APSB ECU: w252 eth switch port link down";
CM_ SG_ 976 APSB_w253_powerStateTimeout "APSB ECU: w253 power state timeout";
CM_ SG_ 976 APSB_w254_sleepStateTimeout "APSB ECU: w254 sleep state timeout";
CM_ SG_ 976 APSB_w255_bootHealth "APSB ECU: w255 boot health";
CM_ BO_ 1003 "APSB ECU message: warning matrix4";
CM_ SG_ 1003 APSB_w257_assertFailure "APSB ECU: w257 assert failure";
CM_ SG_ 1003 APSB_w258_qspiFlashSectorChecksu "APSB ECU: w258 qspi flash sector checksum mismatch";
CM_ SG_ 1003 APSB_w259_qspiFailure "APSB ECU: w259 qspi failure";
CM_ SG_ 1003 APSB_w260_pgoodFailure "APSB ECU: w260 pgood failure";
CM_ SG_ 1003 APSB_w261_vrmFaultGrpA "APSB ECU: w261 vrm fault grp a";
CM_ SG_ 1003 APSB_w262_vrmFaultGrpB "APSB ECU: w262 vrm fault grp b";
CM_ SG_ 1003 APSB_w263_vrmFaultGrpC "APSB ECU: w263 vrm fault grp c";
CM_ SG_ 1003 APSB_w264_ddrPhy0Failures "APSB ECU: w264 ddr phy0 failures";
CM_ SG_ 1003 APSB_w265_ddrPhy1Failures "APSB ECU: w265 ddr phy1 failures";
CM_ SG_ 1003 APSB_w266_ddrPhy2Failures "APSB ECU: w266 ddr phy2 failures";
CM_ SG_ 1003 APSB_w267_ddrPhy3Failures "APSB ECU: w267 ddr phy3 failures";
CM_ SG_ 1003 APSB_w268_ddrControllerFailures "APSB ECU: w268 ddr controller failures";
CM_ SG_ 1003 APSB_w269_ethSwitchRxPageCountTo "APSB ECU: w269 eth switch rx page count too high port0 3";
CM_ SG_ 1003 APSB_w270_ethSwitchRxPageCountTo "APSB ECU: w270 eth switch rx page count too high port4 7";
CM_ SG_ 1003 APSB_w271_ddrScheduler0EccErrors "APSB ECU: w271 ddr scheduler0 ecc errors";
CM_ SG_ 1003 APSB_w272_ddrScheduler1EccErrors "APSB ECU: w272 ddr scheduler1 ecc errors";
CM_ SG_ 1003 APSB_w273_ddrScheduler2EccErrors "APSB ECU: w273 ddr scheduler2 ecc errors";
CM_ SG_ 1003 APSB_w274_ddrScheduler3EccErrors "APSB ECU: w274 ddr scheduler3 ecc errors";
CM_ SG_ 1003 APSB_w275_ddrScheduler4EccErrors "APSB ECU: w275 ddr scheduler4 ecc errors";
CM_ SG_ 1003 APSB_w276_ddrScheduler5EccErrors "APSB ECU: w276 ddr scheduler5 ecc errors";
CM_ SG_ 1003 APSB_w277_ddrScheduler6EccErrors "APSB ECU: w277 ddr scheduler6 ecc errors";
CM_ SG_ 1003 APSB_w278_ddrScheduler7EccErrors "APSB ECU: w278 ddr scheduler7 ecc errors";
CM_ SG_ 1003 APSB_w279_ufsPartitionError "APSB ECU: w279 ufs partition error";
CM_ SG_ 1003 APSB_w280_pepsMia "APSB ECU: w280 peps mia";
CM_ SG_ 1003 APSB_w281_rsaMia "APSB ECU: w281 rsa mia";
CM_ SG_ 1003 APSB_w282_smmuError "APSB ECU: w282 smmu error";
CM_ SG_ 1003 APSB_w283_psfaMia "APSB ECU: w283 psfa mia";
CM_ SG_ 1003 APSB_w284_cam12VBuckBoostAPwrIss "APSB ECU: w284 cam12 v buck boost a pwr issue";
CM_ SG_ 1003 APSB_w285_cam12VBuckBoostBPwrIss "APSB ECU: w285 cam12 v buck boost b pwr issue";
CM_ SG_ 1003 APSB_w286_cam12VEFuseAPrimaryIss "APSB ECU: w286 cam12 VE fuse a primary issue";
CM_ SG_ 1003 APSB_w287_cam12VEFuseASecondaryI "APSB ECU: w287 cam12 VE fuse a secondary issue";
CM_ SG_ 1003 APSB_w288_brakeboosterMia "APSB ECU: w288 brakebooster mia";
CM_ SG_ 1003 APSB_w289_turboTemperatureWarnin "APSB ECU: w289 turbo temperature warning";
CM_ SG_ 1003 APSB_w290_cam12VBuckBoostBPwrRin "APSB ECU: w290 cam12 v buck boost b pwr ringing";
CM_ SG_ 1003 APSB_w291_eplannerError "APSB ECU: w291 eplanner error";
CM_ SG_ 1003 APSB_w292_CH_busOff "APSB ECU: w292 CH bus off";
CM_ SG_ 1003 APSB_w293_PARTY_busOff "APSB ECU: w293 PARTY bus off";
CM_ SG_ 1003 APSB_w294_VEH_busOff "APSB ECU: w294 VEH bus off";
CM_ SG_ 1003 APSB_w295_PT_busOff "APSB ECU: w295 PT bus off";
CM_ SG_ 1003 APSB_w296_wdogMonTaskDeadlineMis "APSB ECU: w296 wdog mon task deadline miss";
CM_ SG_ 1003 APSB_w297_earlyWDogAlert "APSB ECU: w297 early w dog alert";
CM_ SG_ 1003 APSB_w298_cpuToApCanSharedMemErr "APSB ECU: w298 cpu to ap can shared mem error";
CM_ SG_ 1003 APSB_w299_apToCpuCanSharedMemErr "APSB ECU: w299 ap to cpu can shared mem error";
CM_ SG_ 1003 APSB_w300_sharedMemoryAccessErro "APSB ECU: w300 shared memory access error";
CM_ SG_ 1003 APSB_w301_nocTimeoutDetected "APSB ECU: w301 noc timeout detected";
CM_ SG_ 1003 APSB_w302_canAPShmFifoFull "APSB ECU: w302 can AP shm fifo full";
CM_ SG_ 1003 APSB_w303_canAPShmFifoEmpty "APSB ECU: w303 can AP shm fifo empty";
CM_ SG_ 1003 APSB_w304_dataAbort "APSB ECU: w304 data abort";
CM_ SG_ 1003 APSB_w305_gpsPgoodFailure "APSB ECU: w305 gps pgood failure";
CM_ SG_ 1003 APSB_w306_ethPgoodFailure "APSB ECU: w306 eth pgood failure";
CM_ SG_ 1003 APSB_w307_eccEventDetected "APSB ECU: w307 ecc event detected";
CM_ SG_ 1003 APSB_w308_pmicErrorDetected "APSB ECU: w308 pmic error detected";
CM_ SG_ 1003 APSB_w309_ethBridgeDown "APSB ECU: w309 eth bridge down";
CM_ SG_ 1003 APSB_w310_wakeBootMetrics "APSB ECU: w310 wake boot metrics";
CM_ SG_ 1003 APSB_w311_apbdgDasMia "APSB ECU: w311 apbdg das mia";
CM_ SG_ 1003 APSB_w312_apbdgApMia "APSB ECU: w312 apbdg ap mia";
CM_ SG_ 1003 APSB_w313_BDY_busOff "APSB ECU: w313 BDY bus off";
CM_ SG_ 1003 APSB_w315_epas3pMiaBdyBus "APSB ECU: w315 epas3p mia bdy bus";
CM_ SG_ 1003 APSB_w316_apBootHealth "APSB ECU: w316 ap boot health";
CM_ SG_ 1003 APSB_w317_uiMia "APSB ECU: w317 ui mia";
CM_ SG_ 1003 APSB_w318_ethernetNetworkBufferH "APSB ECU: w318 ethernet network buffer high watermark";
CM_ SG_ 1003 APSB_w319_vehDasImposterDetected "APSB ECU: w319 veh das imposter detected";
CM_ SG_ 1003 APSB_w320_eplannerPreconditionsM "APSB ECU: w320 eplanner preconditions met";
CM_ BO_ 943 "BB ECU message: status";
CM_ SG_ 943 BB_statusChecksum "BB ECU: status checksum";
CM_ SG_ 943 BB_statusCounter "BB ECU: status counter";
CM_ SG_ 943 BB_sOutputRod "Reports the measured brake booster (BB) plunger piston position";
CM_ SG_ 943 BB_sOutputRodQF "Reports the BB_sOutputRod signal qualifier";
CM_ SG_ 943 BB_sInputRod "Reports the measured brake booster (BB) input rod stroke.";
CM_ SG_ 943 BB_sInputRodQF "Reports the BB_sInputRod signal qualifier.";
CM_ SG_ 943 BB_driverBrakeApply "Indicates whether the driver operates the brake pedal. Only active when the driver brakes, not when an external brake command implemented on brake booster (BB).";
CM_ SG_ 943 BB_driverBrakeApplyQF "Qualifier for BB_driverBrakeApply";
CM_ SG_ 943 BB_boosterStatus "Indication of the brake booster (BB) functional state";
CM_ SG_ 943 BB_warningLampRequest "Request from brake booster (BB) to enable the red brake lamp";
CM_ SG_ 943 BB_brakeFluidLevel "Indication of the brake fluid reservoir fluid level sensor status measured by the brake booster (BB).";
CM_ SG_ 943 BB_internalState "Indication of the brake booster (BB) internal state";
CM_ SG_ 943 BB_unfilteredFluidLevelLow "Indicates whether the unfiltered brake fluid level is detected as low.";
CM_ BO_ 551 "A/C compressor message: HV status";
CM_ SG_ 551 CMP_inputHVVoltage "Compressor high voltage input voltage";
CM_ SG_ 551 CMP_inputLVVoltage "A/C compressor: input LV voltage";
CM_ SG_ 551 CMP_inputHVCurrent "A/C compressor: input HV current";
CM_ SG_ 551 CMP_inputHVPower "Compressor high voltage input power";
CM_ BO_ 778 "Driver assistance computer message: object";
CM_ SG_ 778 DAS_objectId "Driver assistance computer: object id";
CM_ SG_ 778 DAS_leadVehType "Driver assistance computer: lead veh type";
CM_ SG_ 778 DAS_leadVehRelevantForControl "Driver assistance computer: lead veh relevant for control";
CM_ SG_ 778 DAS_leadVehDx "Measures the distance to lead vehicle, or vehicle in the ego lane; raw 255 = signal not available (SNA)";
CM_ SG_ 778 DAS_leadVehVxRel "Driver assistance computer: lead veh vx rel; raw 15 = signal not available (SNA)";
CM_ SG_ 778 DAS_leadVehDy "Driver assistance computer: lead veh dy";
CM_ SG_ 778 DAS_leadVehId "Driver assistance computer: lead veh id; raw 127 = signal not available (SNA)";
CM_ SG_ 778 DAS_leadVeh2Type "Driver assistance computer: lead veh2 type";
CM_ SG_ 778 DAS_leadVeh2RelevantForControl "Driver assistance computer: lead veh2 relevant for control";
CM_ SG_ 778 DAS_leadVeh2Dx "Driver assistance computer: lead veh2 dx; raw 255 = signal not available (SNA)";
CM_ SG_ 778 DAS_leadVeh2VxRel "Driver assistance computer: lead veh2 vx rel; raw 15 = signal not available (SNA)";
CM_ SG_ 778 DAS_leadVeh2Dy "Driver assistance computer: lead veh2 dy";
CM_ SG_ 778 DAS_leadVeh2Id "Driver assistance computer: lead veh2 id; raw 0 = signal not available (SNA)";
CM_ SG_ 778 DAS_leftVehType "Driver assistance computer: left veh type";
CM_ SG_ 778 DAS_leftVehRelevantForControl "Driver assistance computer: left veh relevant for control";
CM_ SG_ 778 DAS_leftVehDx "Driver assistance computer: left veh dx; raw 255 = signal not available (SNA)";
CM_ SG_ 778 DAS_leftVehVxRel "Driver assistance computer: left veh vx rel; raw 15 = signal not available (SNA)";
CM_ SG_ 778 DAS_leftVehDy "Driver assistance computer: left veh dy";
CM_ SG_ 778 DAS_leftVehId "Driver assistance computer: left veh id; raw 127 = signal not available (SNA)";
CM_ SG_ 778 DAS_leftVeh2Type "Driver assistance computer: left veh2 type";
CM_ SG_ 778 DAS_leftVeh2RelevantForControl "Driver assistance computer: left veh2 relevant for control";
CM_ SG_ 778 DAS_leftVeh2Dx "Driver assistance computer: left veh2 dx; raw 255 = signal not available (SNA)";
CM_ SG_ 778 DAS_leftVeh2VxRel "Driver assistance computer: left veh2 vx rel; raw 15 = signal not available (SNA)";
CM_ SG_ 778 DAS_leftVeh2Dy "Driver assistance computer: left veh2 dy";
CM_ SG_ 778 DAS_leftVeh2Id "Driver assistance computer: left veh2 id; raw 0 = signal not available (SNA)";
CM_ SG_ 778 DAS_rightVehType "Driver assistance computer: right veh type";
CM_ SG_ 778 DAS_rightVehRelevantForControl "Driver assistance computer: right veh relevant for control";
CM_ SG_ 778 DAS_rightVehDx "Driver assistance computer: right veh dx; raw 255 = signal not available (SNA)";
CM_ SG_ 778 DAS_rightVehVxRel "Driver assistance computer: right veh vx rel; raw 15 = signal not available (SNA)";
CM_ SG_ 778 DAS_rightVehDy "Driver assistance computer: right veh dy";
CM_ SG_ 778 DAS_rightVehId "Driver assistance computer: right veh id; raw 127 = signal not available (SNA)";
CM_ SG_ 778 DAS_rightVeh2Type "Driver assistance computer: right veh2 type";
CM_ SG_ 778 DAS_rightVeh2RelevantForControl "Driver assistance computer: right veh2 relevant for control";
CM_ SG_ 778 DAS_rightVeh2Dx "Driver assistance computer: right veh2 dx; raw 255 = signal not available (SNA)";
CM_ SG_ 778 DAS_rightVeh2VxRel "Driver assistance computer: right veh2 vx rel; raw 15 = signal not available (SNA)";
CM_ SG_ 778 DAS_rightVeh2Dy "Driver assistance computer: right veh2 dy";
CM_ SG_ 778 DAS_rightVeh2Id "Driver assistance computer: right veh2 id; raw 0 = signal not available (SNA)";
CM_ SG_ 778 DAS_cutinVehType "Driver assistance computer: cutin veh type";
CM_ SG_ 778 DAS_cutinVehRelevantForControl "Driver assistance computer: cutin veh relevant for control";
CM_ SG_ 778 DAS_cutinVehDx "Driver assistance computer: cutin veh dx; raw 255 = signal not available (SNA)";
CM_ SG_ 778 DAS_cutinVehVxRel "Driver assistance computer: cutin veh vx rel; raw 15 = signal not available (SNA)";
CM_ SG_ 778 DAS_cutinVehDy "Driver assistance computer: cutin veh dy";
CM_ SG_ 778 DAS_cutinVehId "Driver assistance computer: cutin veh id; raw 127 = signal not available (SNA)";
CM_ SG_ 778 DAS_roadSignColor "Driver assistance computer: road sign color";
CM_ SG_ 778 DAS_roadSignId "Driver assistance computer: road sign id; raw 255 = signal not available (SNA)";
CM_ SG_ 778 DAS_roadSignStopLineDist "Driver assistance computer: road sign stop line dist; raw 1023 = signal not available (SNA)";
CM_ SG_ 778 DAS_roadSignControlActive "Driver assistance computer: road sign control active";
CM_ SG_ 778 DAS_roadSignSource "Driver assistance computer: road sign source";
CM_ SG_ 778 DAS_roadSignArrow "Driver assistance computer: road sign arrow";
CM_ SG_ 778 DAS_roadSignOrientation "Driver assistance computer: road sign orientation";
CM_ BO_ 781 "Driver assistance computer message: positioning engine status";
CM_ SG_ 781 DAS_positioningEngineStatusMulti "Driver assistance computer: positioning engine status multiplexer";
CM_ SG_ 781 DAS_meoSolverNumRuns "Driver assistance computer: meo solver num runs";
CM_ SG_ 781 DAS_meoSolverReportTerminationTy "Driver assistance computer: meo solver report termination type";
CM_ SG_ 781 DAS_meoSolverReportTotalTimeS "Driver assistance computer: meo solver report total time s";
CM_ SG_ 781 DAS_meoHorizontalAccuracyM "Driver assistance computer: meo horizontal accuracy m";
CM_ SG_ 781 DAS_meoVerticalAccuracyM "Driver assistance computer: meo vertical accuracy m";
CM_ SG_ 781 DAS_meoHeadingAccuracyDeg "Driver assistance computer: meo heading accuracy deg";
CM_ SG_ 781 DAS_meoHeadingValid "Driver assistance computer: meo heading valid";
CM_ SG_ 781 DAS_meoNumSatellitesUsed "Driver assistance computer: meo num satellites used";
CM_ SG_ 781 DAS_meoGpsQualityLevel "Driver assistance computer: meo gps quality level";
CM_ SG_ 781 DAS_meoFixType "Driver assistance computer: meo fix type";
CM_ SG_ 781 DAS_meoResetCount "Driver assistance computer: meo reset count";
CM_ SG_ 781 DAS_lastMeoResetReason "Driver assistance computer: last meo reset reason";
CM_ SG_ 781 DAS_vioMultiGpsSelectedSource "Driver assistance computer: vio multi gps selected source";
CM_ SG_ 781 DAS_vioMultiGpsPeCooldownActive "Driver assistance computer: vio multi gps pe cooldown active";
CM_ SG_ 781 DAS_vioMultiGpsPeSppTdcpConsiste "Driver assistance computer: vio multi gps pe spp tdcp consistent with raw gps";
CM_ SG_ 781 DAS_vioMultiGpsPeMeoConsistentWi "Driver assistance computer: vio multi gps pe meo consistent with raw gps";
CM_ SG_ 781 DAS_vioMultiGpsPeSppTdcpVsR_0001 "Driver assistance computer: vio multi gps pe spp tdcp vs raw gps trans discrep m";
CM_ SG_ 781 DAS_vioMultiGpsPeMeoVsRawGpsTran "Driver assistance computer: vio multi gps pe meo vs raw gps trans discrep m";
CM_ SG_ 781 DAS_vioMultiGpsPeSppTdcpVsRawGps "Driver assistance computer: vio multi gps pe spp tdcp vs raw gps rot discrep deg";
CM_ SG_ 781 DAS_vioMultiGpsPeMeoVsRawGpsRotD "Driver assistance computer: vio multi gps pe meo vs raw gps rot discrep deg";
CM_ SG_ 781 DAS_publishedGpsSource "Driver assistance computer: published gps source";
CM_ SG_ 781 DAS_bluefinEnabled "Driver assistance computer: bluefin enabled";
CM_ SG_ 781 DAS_orioleDisabled "Driver assistance computer: oriole disabled";
CM_ SG_ 781 DAS_disableMonarch "Indicates the state of the Autopilot (AP) monarch positioning engine.";
CM_ BO_ 1548 "Driver assistance computer message: telemetry radar";
CM_ SG_ 1548 DAS_TR_ObjIndex "Driver assistance computer: TR obj index";
CM_ SG_ 1548 DAS_TR_Counter "Driver assistance computer: TR counter";
CM_ SG_ 1548 DAS_TR_Obj00_Class "Driver assistance computer: TR obj00 class";
CM_ SG_ 1548 DAS_TR_Obj00_Dx "Driver assistance computer: TR obj00 dx";
CM_ SG_ 1548 DAS_TR_Obj00_Dy "Driver assistance computer: TR obj00 dy";
CM_ SG_ 1548 DAS_TR_Obj00_Vx "Driver assistance computer: TR obj00 vx";
CM_ SG_ 1548 DAS_TR_Obj00_RCS "Driver assistance computer: TR obj00 RCS";
CM_ SG_ 1548 DAS_TR_Obj00_Length "Driver assistance computer: TR obj00 length";
CM_ SG_ 1548 DAS_TR_Obj00_MovingState "Driver assistance computer: TR obj00 moving state";
CM_ SG_ 1548 DAS_TR_Obj00_Dz "Driver assistance computer: TR obj00 dz";
CM_ SG_ 1548 DAS_TR_Obj00_Exist "Driver assistance computer: TR obj00 exist";
CM_ BO_ 1237 "DPB ECU message: alert log";
CM_ SG_ 1237 DPB_alertID "DPB ECU: alert ID";
CM_ SG_ 1237 DPB_alertState "DPB ECU: alert state";
CM_ BO_ 999 "DPB ECU message: alert matrix";
CM_ SG_ 999 DPB_matrixIndex "DPB ECU: matrix index";
CM_ SG_ 999 DPB_a001_pPlungerSensorOffsetHig "DPB ECU: a001 p plunger sensor offset high";
CM_ SG_ 999 DPB_a002_pMC2SensorOffsetHigh "DPB ECU: a002 p MC2 sensor offset high";
CM_ SG_ 999 DPB_a003_AswEEPROMReadFailure "DPB ECU: a003 asw EEPROM read failure";
CM_ SG_ 999 DPB_a004_assertionFault "DPB ECU: a004 assertion fault";
CM_ SG_ 999 DPB_a005_hardPedalChar "DPB ECU: a005 hard pedal char";
CM_ SG_ 999 DPB_a006_hardPedalCharGoodCheck "DPB ECU: a006 hard pedal char good check";
CM_ SG_ 999 DPB_a007_PMCLeakageDetected "DPB ECU: a007 PMC leakage detected";
CM_ SG_ 999 DPB_a008_LiPSPts1Offset "DPB ECU: a008 li PS pts1 offset";
CM_ SG_ 999 DPB_a009_LiPSPts2Offset "DPB ECU: a009 li PS pts2 offset";
CM_ SG_ 999 DPB_a010_LiPSPtsConsistency "DPB ECU: a010 li PS pts consistency";
CM_ SG_ 999 DPB_a011_PtsNonZeroStage1 "DPB ECU: a011 pts non zero stage1";
CM_ SG_ 999 DPB_a012_PtsNonZeroStage2 "DPB ECU: a012 pts non zero stage2";
CM_ SG_ 999 DPB_a013_softPedalChar "DPB ECU: a013 soft pedal char";
CM_ SG_ 999 DPB_a014_CANControllerHWFault "DPB ECU: a014 CAN controller HW fault";
CM_ SG_ 999 DPB_a015_CAN1BusOff "DPB ECU: a015 CAN1 bus off";
CM_ SG_ 999 DPB_a016_CAN2BusOff "DPB ECU: a016 CAN2 bus off";
CM_ SG_ 999 DPB_a017_largeLeakageDetected "DPB ECU: a017 large leakage detected";
CM_ SG_ 999 DPB_a018_largeLeakageDetectedGoo "DPB ECU: a018 large leakage detected good check";
CM_ SG_ 999 DPB_a019_DETReportError "DPB ECU: a019 DET report error";
CM_ SG_ 999 DPB_a020_ecuHuMismatch "DPB ECU: a020 ecu hu mismatch";
CM_ SG_ 999 DPB_a021_brakeSystemOverheatLvl1 "DPB ECU: a021 brake system overheat lvl1";
CM_ SG_ 999 DPB_a022_brakeSystemOverheatLvl2 "DPB ECU: a022 brake system overheat lvl2";
CM_ SG_ 999 DPB_a023_initialPlungerCheckFail "DPB ECU: a023 initial plunger check failed";
CM_ SG_ 999 DPB_a024_ESPLDMFailure "DPB ECU: a024 ESPLDM failure";
CM_ SG_ 999 DPB_a025_backupCircuitLeakage "DPB ECU: a025 backup circuit leakage";
CM_ SG_ 999 DPB_a026_LiPSIDTimeout "DPB ECU: a026 li PSID timeout";
CM_ SG_ 999 DPB_a027_motorTempHighLevel1 "DPB ECU: a027 motor temp high level1";
CM_ SG_ 999 DPB_a028_motorTempHighLevel2 "DPB ECU: a028 motor temp high level2";
CM_ SG_ 999 DPB_a029_motorTestFault "DPB ECU: a029 motor test fault";
CM_ SG_ 999 DPB_a030_notShutDownRight "DPB ECU: a030 not shut down right";
CM_ SG_ 999 DPB_a031_HWParamReadFailed "DPB ECU: a031 HW param read failed";
CM_ SG_ 999 DPB_a032_HWParamWriteFailed "DPB ECU: a032 HW param write failed";
CM_ SG_ 999 DPB_a033_motorDynamicLimited "DPB ECU: a033 motor dynamic limited";
CM_ SG_ 999 DPB_a034_lipsMemoryEmpty "DPB ECU: a034 lips memory empty";
CM_ SG_ 999 DPB_a035_PDURouterinitialization "DPB ECU: a035 PDU routerinitialization failed";
CM_ SG_ 999 DPB_a036_lossOfPDUInstanceDetect "DPB ECU: a036 loss of PDU instance detected";
CM_ SG_ 999 DPB_a037_plungerCircuitPressHigh "DPB ECU: a037 plunger circuit press high";
CM_ SG_ 999 DPB_a038_plungerCircuitPressHigh "DPB ECU: a038 plunger circuit press high good check";
CM_ SG_ 999 DPB_a039_plungerCircuitPressLow "DPB ECU: a039 plunger circuit press low";
CM_ SG_ 999 DPB_a040_plungerCircuitPressLowG "DPB ECU: a040 plunger circuit press low good check";
CM_ SG_ 999 DPB_a041_PSCGearRatioReadFault "DPB ECU: a041 PSC gear ratio read fault";
CM_ SG_ 999 DPB_a042_motorLoadPressImplausib "DPB ECU: a042 motor load press implausible";
CM_ SG_ 999 DPB_a043_PSCMotorSizeReadFault "DPB ECU: a043 PSC motor size read fault";
CM_ SG_ 999 DPB_a044_supplyOvervoltageLvl1 "DPB ECU: a044 supply overvoltage lvl1";
CM_ SG_ 999 DPB_a045_supplyOvervoltageLvl2 "DPB ECU: a045 supply overvoltage lvl2";
CM_ SG_ 999 DPB_a046_supplyOvervoltageLvl3 "DPB ECU: a046 supply overvoltage lvl3";
CM_ SG_ 999 DPB_a047_pPlungerPlausCheckFailu "DPB ECU: a047 p plunger plaus check failure";
CM_ SG_ 999 DPB_a048_supplyUndervoltageLvl1 "DPB ECU: a048 supply undervoltage lvl1";
CM_ SG_ 999 DPB_a049_supplyUndervoltageLvl2 "DPB ECU: a049 supply undervoltage lvl2";
CM_ SG_ 999 DPB_a050_supplyUndervoltageLvl3 "DPB ECU: a050 supply undervoltage lvl3";
CM_ SG_ 999 DPB_a051_PSCVoltageImplausible "DPB ECU: a051 PSC voltage implausible";
CM_ SG_ 999 DPB_a052_PSIDTimeOut "DPB ECU: a052 PSID time out";
CM_ SG_ 999 DPB_a053_hydraulicAssemblyModeAc "DPB ECU: a053 hydraulic assembly mode active";
CM_ SG_ 999 DPB_a054_unsupportedHW "DPB ECU: a054 unsupported HW";
CM_ SG_ 999 DPB_a055_unsupportedSeriesHWDete "DPB ECU: a055 unsupported series HW detected";
CM_ SG_ 999 DPB_a056_AdcPeripheralFault "DPB ECU: a056 adc peripheral fault";
CM_ SG_ 999 DPB_a057_AdcPinTest "DPB ECU: a057 adc pin test";
CM_ SG_ 999 DPB_a058_AdcSelftestC5P "DPB ECU: a058 adc selftest C5 p";
CM_ SG_ 999 DPB_a059_factoryModeActive "DPB ECU: a059 factory mode active";
CM_ SG_ 999 DPB_a060_motorBridgeDriverFault "DPB ECU: a060 motor bridge driver fault";
CM_ SG_ 999 DPB_a061_bridgeSwitchInitError "DPB ECU: a061 bridge switch init error";
CM_ SG_ 999 DPB_a062_loadDumpOnFSLTest "DPB ECU: a062 load dump on FSL test";
CM_ SG_ 999 DPB_a063_motorConfigMismatch "DPB ECU: a063 motor config mismatch";
CM_ SG_ 999 DPB_a064_current1OffsetHigh "DPB ECU: a064 current1 offset high";
CM_ SG_ 999 DPB_a065_current1OffsetLow "DPB ECU: a065 current1 offset low";
CM_ SG_ 999 DPB_a066_current2OffsetHigh "DPB ECU: a066 current2 offset high";
CM_ SG_ 999 DPB_a067_current2OffsetLow "DPB ECU: a067 current2 offset low";
CM_ SG_ 999 DPB_a068_BLMMuxerTimeoutError "DPB ECU: a068 BLM muxer timeout error";
CM_ SG_ 999 DPB_a069_OBDCurrent1OORHigh "DPB ECU: a069 OBD current1 OOR high";
CM_ SG_ 999 DPB_a070_OBDCurrent1OORLow "DPB ECU: a070 OBD current1 OOR low";
CM_ SG_ 999 DPB_a071_OBDCurrent2OORHigh "DPB ECU: a071 OBD current2 OOR high";
CM_ SG_ 999 DPB_a072_OBDCurrent2OORLow "DPB ECU: a072 OBD current2 OOR low";
CM_ SG_ 999 DPB_a073_rotorCosOutOfRangeHigh "DPB ECU: a073 rotor cos out of range high";
CM_ SG_ 999 DPB_a074_rotorCosOutOfRangeLow "DPB ECU: a074 rotor cos out of range low";
CM_ SG_ 999 DPB_a075_rotorSinOutOfRangeHigh "DPB ECU: a075 rotor sin out of range high";
CM_ SG_ 999 DPB_a076_rotorSinOutOfRangeLow "DPB ECU: a076 rotor sin out of range low";
CM_ SG_ 999 DPB_a077_tempSens1ShortToSupply "DPB ECU: a077 temp sens1 short to supply";
CM_ SG_ 999 DPB_a078_tempSens1ShortToGround "DPB ECU: a078 temp sens1 short to ground";
CM_ SG_ 999 DPB_a079_tempSens2ShortToSupply "DPB ECU: a079 temp sens2 short to supply";
CM_ SG_ 999 DPB_a080_tempSens2ShortToGround "DPB ECU: a080 temp sens2 short to ground";
CM_ SG_ 999 DPB_a081_tempSensImplausVoltage "DPB ECU: a081 temp sens implaus voltage";
CM_ SG_ 999 DPB_a082_chargePumpFault "DPB ECU: a082 charge pump fault";
CM_ SG_ 999 DPB_a083_chargePumpUndervoltage "DPB ECU: a083 charge pump undervoltage";
CM_ SG_ 999 DPB_a084_RBCPUException "DPB ECU: a084 RBCPU exception";
CM_ SG_ 999 DPB_a085_infoFailureWrongCUBASHa "DPB ECU: a085 info failure wrong CUBAS handling detected";
CM_ SG_ 999 DPB_a086_diagHydProtectionPressF "DPB ECU: a086 diag hyd protection press fault";
CM_ SG_ 999 DPB_a087_diagHydProtectionVlvFau "DPB ECU: a087 diag hyd protection vlv fault";
CM_ SG_ 999 DPB_a088_DMATransferError "DPB ECU: a088 DMA transfer error";
CM_ SG_ 999 DPB_a089_ecuBandgap "DPB ECU: a089 ecu bandgap";
CM_ SG_ 999 DPB_a090_flashFault "DPB ECU: a090 flash fault";
CM_ SG_ 999 DPB_a091_MRGPathTestFault "DPB ECU: a091 MRG path test fault";
CM_ SG_ 999 DPB_a092_decoupleBitTestFault "DPB ECU: a092 decouple bit test fault";
CM_ SG_ 999 DPB_a093_ecuBistFaultCtrFault "DPB ECU: a093 ecu bist fault ctr fault";
CM_ SG_ 999 DPB_a094_ecuClockTestFault "DPB ECU: a094 ecu clock test fault";
CM_ SG_ 999 DPB_a095_ecuEnableElHighFault "DPB ECU: a095 ecu enable el high fault";
CM_ SG_ 999 DPB_a096_ecuEnableElLowFault "DPB ECU: a096 ecu enable el low fault";
CM_ SG_ 999 DPB_a097_ecuEnableHyHighFault "DPB ECU: a097 ecu enable hy high fault";
CM_ SG_ 999 DPB_a098_ecuEnableHyLowFault "DPB ECU: a098 ecu enable hy low fault";
CM_ SG_ 999 DPB_a099_ecuEnContinuousError "DPB ECU: a099 ecu en continuous error";
CM_ SG_ 999 DPB_a100_ecuErrpinCounterFault "DPB ECU: a100 ecu errpin counter fault";
CM_ SG_ 999 DPB_a101_ecuFastWdTestFault "DPB ECU: a101 ecu fast wd test fault";
CM_ SG_ 999 DPB_a102_ecuVrOnWhileWdTimeout "DPB ECU: a102 ecu vr on while wd timeout";
CM_ SG_ 999 DPB_a103_ecuVrViaSpiFails "DPB ECU: a103 ecu vr via spi fails";
CM_ SG_ 999 DPB_a104_ecuWdStartuptestFault "DPB ECU: a104 ecu wd startuptest fault";
CM_ SG_ 999 DPB_a105_ecuWdSContinuousError "DPB ECU: a105 ecu wd s continuous error";
CM_ SG_ 999 DPB_a106_ecuBistCmdTestFault "DPB ECU: a106 ecu bist cmd test fault";
CM_ SG_ 999 DPB_a107_vrOnFails "DPB ECU: a107 vr on fails";
CM_ SG_ 999 DPB_a108_GTMRefFrequencyError "DPB ECU: a108 GTM ref frequency error";
CM_ SG_ 999 DPB_a109_GTMTbuMonError "DPB ECU: a109 GTM tbu mon error";
CM_ SG_ 999 DPB_a110_HWBISTError "DPB ECU: a110 HWBIST error";
CM_ SG_ 999 DPB_a111_hydraulicHardUndervolta "DPB ECU: a111 hydraulic hard undervoltage";
CM_ SG_ 999 DPB_a112_hydraulicUndervoltage "DPB ECU: a112 hydraulic undervoltage";
CM_ SG_ 999 DPB_a113_LiPS1SentLineHigh "DPB ECU: a113 li PS1 sent line high";
CM_ SG_ 999 DPB_a114_LiPS1SentLineLow "DPB ECU: a114 li PS1 sent line low";
CM_ SG_ 999 DPB_a115_LiPS1SentSensor "DPB ECU: a115 li PS1 sent sensor";
CM_ SG_ 999 DPB_a116_LiPS1SentTransmission "DPB ECU: a116 li PS1 sent transmission";
CM_ SG_ 999 DPB_a117_LiPS2PwmLineHigh "DPB ECU: a117 li PS2 pwm line high";
CM_ SG_ 999 DPB_a118_LiPS2PwmLineLow "DPB ECU: a118 li PS2 pwm line low";
CM_ SG_ 999 DPB_a119_LiPS2PwmTransmission "DPB ECU: a119 li PS2 pwm transmission";
CM_ SG_ 999 DPB_a120_LiPSOutOfRangeHigh "DPB ECU: a120 li PS out of range high";
CM_ SG_ 999 DPB_a121_LiPSOutOfRangeLow "DPB ECU: a121 li PS out of range low";
CM_ SG_ 999 DPB_a122_micAsicClkInError "DPB ECU: a122 mic asic clk in error";
CM_ SG_ 999 DPB_a123_micAsicInitTestError "DPB ECU: a123 mic asic init test error";
CM_ SG_ 999 DPB_a124_asicOscillatorError "DPB ECU: a124 asic oscillator error";
CM_ SG_ 999 DPB_a125_B6AsicFault "DPB ECU: a125 B6 asic fault";
CM_ SG_ 999 DPB_a126_MICB6TransferError "DPB ECU: a126 MICB6 transfer error";
CM_ SG_ 999 DPB_a127_hydraulicAsicShortCircu "DPB ECU: a127 hydraulic asic short circuit";
CM_ SG_ 999 DPB_a128_micSpiTransferError "DPB ECU: a128 mic spi transfer error";
CM_ SG_ 999 DPB_a129_AsicTrimmingNotComplete "DPB ECU: a129 asic trimming not completed";
CM_ SG_ 999 DPB_a130_AsicMalfunctionDetected "DPB ECU: a130 asic malfunction detected";
CM_ SG_ 999 DPB_a131_ASICOvercurrentOnGPIO25 "DPB ECU: a131 ASIC overcurrent on GPIO250 1";
CM_ SG_ 999 DPB_a132_ASICOvercurrentOnGPIO25 "DPB ECU: a132 ASIC overcurrent on GPIO250 2";
CM_ SG_ 999 DPB_a133_ASICOvercurrentOnGPIO50 "DPB ECU: a133 ASIC overcurrent on GPIO50 1";
CM_ SG_ 999 DPB_a134_ASICOvercurrentOnGPIO50 "DPB ECU: a134 ASIC overcurrent on GPIO50 2";
CM_ SG_ 999 DPB_a135_ASICOvercurrentOnGPIO50 "DPB ECU: a135 ASIC overcurrent on GPIO50 3";
CM_ SG_ 999 DPB_a136_ASICOvercurrentOnGPIO50 "DPB ECU: a136 ASIC overcurrent on GPIO50 4";
CM_ SG_ 999 DPB_a137_ASICOvercurrentOnWRHS "DPB ECU: a137 ASIC overcurrent on WRHS";
CM_ SG_ 999 DPB_a138_DIchassisControlCounter "DPB ECU: a138 d ichassis control counter";
CM_ SG_ 999 DPB_a139_DIchassisControlChecksu "DPB ECU: a139 d ichassis control checksum";
CM_ SG_ 999 DPB_a140_DIchassisControlDLC "DPB ECU: a140 d ichassis control DLC";
CM_ SG_ 999 DPB_a141_DIchassisControlTimeout "DPB ECU: a141 d ichassis control timeout";
CM_ SG_ 999 DPB_a142_DIsystemStatusCounter "DPB ECU: a142 d isystem status counter";
CM_ SG_ 999 DPB_a143_DIsystemStatusChecksum "DPB ECU: a143 d isystem status checksum";
CM_ SG_ 999 DPB_a144_DIsystemStatusDLC "DPB ECU: a144 d isystem status DLC";
CM_ SG_ 999 DPB_a145_DIsystemStatusTimeout "DPB ECU: a145 d isystem status timeout";
CM_ SG_ 999 DPB_a146_DIFtorqueCounter "DPB ECU: a146 DI ftorque counter";
CM_ SG_ 999 DPB_a147_DIFtorqueChecksum "DPB ECU: a147 DI ftorque checksum";
CM_ SG_ 999 DPB_a148_DIFtorqueDLC "DPB ECU: a148 DI ftorque DLC";
CM_ SG_ 999 DPB_a149_DIFtorqueTimeout "DPB ECU: a149 DI ftorque timeout";
CM_ SG_ 999 DPB_a150_DIRtorqueCounter "DPB ECU: a150 DI rtorque counter";
CM_ SG_ 999 DPB_a151_DIRtorqueChecksum "DPB ECU: a151 DI rtorque checksum";
CM_ SG_ 999 DPB_a152_DIRtorqueDLC "DPB ECU: a152 DI rtorque DLC";
CM_ SG_ 999 DPB_a153_DIRtorqueTimeout "DPB ECU: a153 DI rtorque timeout";
CM_ SG_ 999 DPB_a154_EPBLstatusCounter "DPB ECU: a154 EPB lstatus counter";
CM_ SG_ 999 DPB_a155_EPBLstatusChecksum "DPB ECU: a155 EPB lstatus checksum";
CM_ SG_ 999 DPB_a156_EPBLstatusDLC "DPB ECU: a156 EPB lstatus DLC";
CM_ SG_ 999 DPB_a157_EPBLstatusTimeout "DPB ECU: a157 EPB lstatus timeout";
CM_ SG_ 999 DPB_a158_EPBRstatusCounter "DPB ECU: a158 EPB rstatus counter";
CM_ SG_ 999 DPB_a159_EPBRstatusChecksum "DPB ECU: a159 EPB rstatus checksum";
CM_ SG_ 999 DPB_a160_EPBRstatusDLC "DPB ECU: a160 EPB rstatus DLC";
CM_ SG_ 999 DPB_a161_EPBRstatusTimeout "DPB ECU: a161 EPB rstatus timeout";
CM_ SG_ 999 DPB_a162_ESP_modulator1Counter "DPB ECU: a162 ESP modulator1 counter";
CM_ SG_ 999 DPB_a163_ESP_modulator1Checksum "DPB ECU: a163 ESP modulator1 checksum";
CM_ SG_ 999 DPB_a164_ESP_modulator1DLC "DPB ECU: a164 ESP modulator1 DLC";
CM_ SG_ 999 DPB_a165_ESP_modulator1Timeout "DPB ECU: a165 ESP modulator1 timeout";
CM_ SG_ 999 DPB_a166_ESP_chassis3Counter "DPB ECU: a166 ESP chassis3 counter";
CM_ SG_ 999 DPB_a167_ESP_chassis3Checksum "DPB ECU: a167 ESP chassis3 checksum";
CM_ SG_ 999 DPB_a168_ESP_chassis3DLC "DPB ECU: a168 ESP chassis3 DLC";
CM_ SG_ 999 DPB_a169_ESP_chassis3Timeout "DPB ECU: a169 ESP chassis3 timeout";
CM_ SG_ 999 DPB_a170_ESP_modulator2Counter "DPB ECU: a170 ESP modulator2 counter";
CM_ SG_ 999 DPB_a171_ESP_modulator2Checksum "DPB ECU: a171 ESP modulator2 checksum";
CM_ SG_ 999 DPB_a172_ESP_modulator2DLC "DPB ECU: a172 ESP modulator2 DLC";
CM_ SG_ 999 DPB_a173_ESP_modulator2Timeout "DPB ECU: a173 ESP modulator2 timeout";
CM_ SG_ 999 DPB_a174_ESP_modulator3Counter "DPB ECU: a174 ESP modulator3 counter";
CM_ SG_ 999 DPB_a175_ESP_modulator3Checksum "DPB ECU: a175 ESP modulator3 checksum";
CM_ SG_ 999 DPB_a176_ESP_modulator3DLC "DPB ECU: a176 ESP modulator3 DLC";
CM_ SG_ 999 DPB_a177_ESP_modulator3Timeout "DPB ECU: a177 ESP modulator3 timeout";
CM_ SG_ 999 DPB_a178_PMstate2Counter "DPB ECU: a178 p mstate2 counter";
CM_ SG_ 999 DPB_a179_PMstate2Checksum "DPB ECU: a179 p mstate2 checksum";
CM_ SG_ 999 DPB_a180_PMstate2DLC "DPB ECU: a180 p mstate2 DLC";
CM_ SG_ 999 DPB_a181_PMstate2Timeout "DPB ECU: a181 p mstate2 timeout";
CM_ SG_ 999 DPB_a182_RCMInertial2Counter "DPB ECU: a182 RCM inertial2 counter";
CM_ SG_ 999 DPB_a183_RCMInertial2Checksum "DPB ECU: a183 RCM inertial2 checksum";
CM_ SG_ 999 DPB_a184_RCMInertial2DLC "DPB ECU: a184 RCM inertial2 DLC";
CM_ SG_ 999 DPB_a185_RCMInertial2Timeout "DPB ECU: a185 RCM inertial2 timeout";
CM_ SG_ 999 DPB_a186_LVPowerStateTimeout "DPB ECU: a186 LV power state timeout";
CM_ SG_ 999 DPB_a187_LVPowerStateChecksum "DPB ECU: a187 LV power state checksum";
CM_ SG_ 999 DPB_a188_LVPowerStateDLC "DPB ECU: a188 LV power state DLC";
CM_ SG_ 999 DPB_a189_LVPowerStateCounter "DPB ECU: a189 LV power state counter";
CM_ SG_ 999 DPB_a190_VCLEFTepbmStatusCounter "DPB ECU: a190 VCLEF tepbm status counter";
CM_ SG_ 999 DPB_a191_VCLEFTepbmStatusChecksu "DPB ECU: a191 VCLEF tepbm status checksum";
CM_ SG_ 999 DPB_a192_VCLEFTepbmStatusDLC "DPB ECU: a192 VCLEF tepbm status DLC";
CM_ SG_ 999 DPB_a193_VCLEFTepbmStatusTimeout "DPB ECU: a193 VCLEF tepbm status timeout";
CM_ SG_ 999 DPB_a194_VCRIGHTepbmStatusCounte "DPB ECU: a194 VCRIGH tepbm status counter";
CM_ SG_ 999 DPB_a195_VCRIGHTepbmStatusChecks "DPB ECU: a195 VCRIGH tepbm status checksum";
CM_ SG_ 999 DPB_a196_VCRIGHTepbmStatusDLC "DPB ECU: a196 VCRIGH tepbm status DLC";
CM_ SG_ 999 DPB_a197_VCRIGHTepbmStatusTimeou "DPB ECU: a197 VCRIGH tepbm status timeout";
CM_ SG_ 999 DPB_a198_CANOvervoltage "DPB ECU: a198 CAN overvoltage";
CM_ SG_ 999 DPB_a199_pMC1QFaulty "DPB ECU: a199 p MC1 q faulty";
CM_ SG_ 999 DPB_a200_ESPRunoutSupportNotAvai "DPB ECU: a200 ESP runout support not available";
CM_ SG_ 999 DPB_a201_vehicleSpeedQFaulty "DPB ECU: a201 vehicle speed q faulty";
CM_ SG_ 999 DPB_a202_vehicleStandstillQFault "DPB ECU: a202 vehicle standstill q faulty";
CM_ SG_ 999 DPB_a203_ABSNotAvailable "DPB ECU: a203 ABS not available";
CM_ SG_ 999 DPB_a204_CANUndervoltage "DPB ECU: a204 CAN undervoltage";
CM_ SG_ 999 DPB_a205_NvMWriteCycleExceed "DPB ECU: a205 nv m write cycle exceed";
CM_ SG_ 999 DPB_a206_OSTaskSchemeError "DPB ECU: a206 OS task scheme error";
CM_ SG_ 999 DPB_a207_hydraulicOvervoltage "DPB ECU: a207 hydraulic overvoltage";
CM_ SG_ 999 DPB_a208_pressureSensor1Short "DPB ECU: a208 pressure sensor1 short";
CM_ SG_ 999 DPB_a209_pressureSensor1High "DPB ECU: a209 pressure sensor1 high";
CM_ SG_ 999 DPB_a210_pressureSensor1Low "DPB ECU: a210 pressure sensor1 low";
CM_ SG_ 999 DPB_a211_pressureSensor1Fault "DPB ECU: a211 pressure sensor1 fault";
CM_ SG_ 999 DPB_a212_pressureSensor1Temp "DPB ECU: a212 pressure sensor1 temp";
CM_ SG_ 999 DPB_a213_pressureSensor1Fault "DPB ECU: a213 pressure sensor1 fault";
CM_ SG_ 999 DPB_a214_pressureSensor2Short "DPB ECU: a214 pressure sensor2 short";
CM_ SG_ 999 DPB_a215_pressureSensor2High "DPB ECU: a215 pressure sensor2 high";
CM_ SG_ 999 DPB_a216_pressureSensor2Low "DPB ECU: a216 pressure sensor2 low";
CM_ SG_ 999 DPB_a217_pressureSensor2Fault "DPB ECU: a217 pressure sensor2 fault";
CM_ SG_ 999 DPB_a218_pressureSensor2Temp "DPB ECU: a218 pressure sensor2 temp";
CM_ SG_ 999 DPB_a219_pressureSensor2Fault "DPB ECU: a219 pressure sensor2 fault";
CM_ SG_ 999 DPB_a220_excessiveBoostWakeupsDe "DPB ECU: a220 excessive boost wakeups detected";
CM_ SG_ 999 DPB_a221_notShutdownRight "DPB ECU: a221 not shutdown right";
CM_ SG_ 999 DPB_a222_excessiveEcuResetsDetec "DPB ECU: a222 excessive ecu resets detected";
CM_ SG_ 999 DPB_a223_RAMFault "DPB ECU: a223 RAM fault";
CM_ SG_ 999 DPB_a224_brakeBoostLost "DPB ECU: a224 brake boost lost";
CM_ SG_ 999 DPB_a225_U5VOutOfRange "DPB ECU: a225 U5 v out of range";
CM_ SG_ 999 DPB_a226_U5VTestFault "DPB ECU: a226 U5 v test fault";
CM_ SG_ 999 DPB_a227_brakeFluidLoss "DPB ECU: a227 brake fluid loss";
CM_ SG_ 999 DPB_a228_supplyASICInitFault "DPB ECU: a228 supply ASIC init fault";
CM_ SG_ 999 DPB_a229_IREFOutOfRange "DPB ECU: a229 IREF out of range";
CM_ SG_ 999 DPB_a230_OSErrorHook "DPB ECU: a230 OS error hook";
CM_ SG_ 999 DPB_a231_stackOverUnderFlow "DPB ECU: a231 stack over under flow";
CM_ SG_ 999 DPB_a232_systemErrorHook "DPB ECU: a232 system error hook";
CM_ SG_ 999 DPB_a233_systemTaskJitter "DPB ECU: a233 system task jitter";
CM_ SG_ 999 DPB_a234_systemTaskOverRun "DPB ECU: a234 system task over run";
CM_ SG_ 999 DPB_a235_UB6PlausiMonFault "DPB ECU: a235 UB6 plausi mon fault";
CM_ SG_ 999 DPB_a236_UB6SupplyPathFault "DPB ECU: a236 UB6 supply path fault";
CM_ SG_ 999 DPB_a237_uCVoltageDividerDrift "DPB ECU: a237 u c voltage divider drift";
CM_ SG_ 999 DPB_a238_microRegisterFault "DPB ECU: a238 micro register fault";
CM_ SG_ 999 DPB_a239_microSafetyFault "DPB ECU: a239 micro safety fault";
CM_ SG_ 999 DPB_a240_microSafetyLogicFault "DPB ECU: a240 micro safety logic fault";
CM_ SG_ 999 DPB_a241_uCSafetyNotification "DPB ECU: a241 u c safety notification";
CM_ SG_ 999 DPB_a242_uCSafetyNotificationGRA "DPB ECU: a242 u c safety notification GRAM";
CM_ SG_ 999 DPB_a243_microSupplyError "DPB ECU: a243 micro supply error";
CM_ SG_ 999 DPB_a244_valvesGenericFault "DPB ECU: a244 valves generic fault";
CM_ SG_ 999 DPB_a245_valveMV0Fault "DPB ECU: a245 valve MV0 fault";
CM_ SG_ 999 DPB_a246_valveMV5Fault "DPB ECU: a246 valve MV5 fault";
CM_ SG_ 999 DPB_a247_valveMV6Fault "DPB ECU: a247 valve MV6 fault";
CM_ SG_ 999 DPB_a248_valveMV61Fault "DPB ECU: a248 valve MV61 fault";
CM_ SG_ 999 DPB_a249_valveMV62Fault "DPB ECU: a249 valve MV62 fault";
CM_ SG_ 999 DPB_a250_valveMV7Fault "DPB ECU: a250 valve MV7 fault";
CM_ SG_ 999 DPB_a251_valveMV8Fault "DPB ECU: a251 valve MV8 fault";
CM_ SG_ 999 DPB_a252_valveMV81Fault "DPB ECU: a252 valve MV81 fault";
CM_ SG_ 999 DPB_a253_valveMV82Fault "DPB ECU: a253 valve MV82 fault";
CM_ SG_ 999 DPB_a254_valveMV9Fault "DPB ECU: a254 valve MV9 fault";
CM_ SG_ 999 DPB_a255_valveRelayShort "DPB ECU: a255 valve relay short";
CM_ SG_ 999 DPB_a256_valveRelayActuationFaul "DPB ECU: a256 valve relay actuation fault";
CM_ SG_ 999 DPB_a257_valveRelayOnContinuous "DPB ECU: a257 valve relay on continuous";
CM_ SG_ 999 DPB_a258_valveRelayOffContinuous "DPB ECU: a258 valve relay off continuous";
CM_ SG_ 999 DPB_a259_valveRelayTestUndervolt "DPB ECU: a259 valve relay test undervoltage";
CM_ SG_ 999 DPB_a260_valveRelaySafetySwitchF "DPB ECU: a260 valve relay safety switch fault";
CM_ SG_ 999 DPB_a261_WdhAsicWdCmdMissing "DPB ECU: a261 wdh asic wd cmd missing";
CM_ SG_ 999 DPB_a262_WdhAsicWdErrorCntLimit "DPB ECU: a262 wdh asic wd error cnt limit";
CM_ SG_ 999 DPB_a263_WdhAsicWdErrorCntStuck "DPB ECU: a263 wdh asic wd error cnt stuck";
CM_ SG_ 999 DPB_a264_WdhSwBistConCnt "DPB ECU: a264 wdh sw bist con cnt";
CM_ SG_ 999 DPB_a265_WdhTaskMonConCnt "DPB ECU: a265 wdh task mon con cnt";
CM_ SG_ 999 DPB_a266_RPSNvMReadFault "DPB ECU: a266 RPS nv m read fault";
CM_ SG_ 999 DPB_a267_RpsAngleImplausible "DPB ECU: a267 rps angle implausible";
CM_ SG_ 999 DPB_a268_RPSVectorOscillating "DPB ECU: a268 RPS vector oscillating";
CM_ SG_ 999 DPB_a269_RPSVectorRangeHigh "DPB ECU: a269 RPS vector range high";
CM_ SG_ 999 DPB_a270_RPSVectorRangeLow "DPB ECU: a270 RPS vector range low";
CM_ SG_ 999 DPB_a271_RPSWrongCalibData "DPB ECU: a271 RPS wrong calib data";
CM_ SG_ 999 DPB_a272_runtimeAssertionFault "DPB ECU: a272 runtime assertion fault";
CM_ SG_ 999 DPB_a273_SMMOneRequestsInit "DPB ECU: a273 SMM one requests init";
CM_ SG_ 999 DPB_a274_AswSystemTimeOut "DPB ECU: a274 asw system time out";
CM_ SG_ 999 DPB_a275_Ps1Ps2PlausibilityFault "DPB ECU: a275 ps1 ps2 plausibility fault";
CM_ SG_ 999 DPB_a276_VCFRONTsensorsCounter "DPB ECU: a276 VCFRON tsensors counter";
CM_ SG_ 999 DPB_a277_VCFRONTsensorsChecksum "DPB ECU: a277 VCFRON tsensors checksum";
CM_ SG_ 999 DPB_a278_VCFRONTsensorsDLC "DPB ECU: a278 VCFRON tsensors DLC";
CM_ SG_ 999 DPB_a279_VCFRONTsensorsTimeout "DPB ECU: a279 VCFRON tsensors timeout";
CM_ SG_ 999 DPB_a280_LowBrakeFluid "DPB ECU: a280 low brake fluid";
CM_ SG_ 999 DPB_a281_brakeFluidOORHigh "DPB ECU: a281 brake fluid OOR high";
CM_ SG_ 999 DPB_a282_DIbrakeCommandCounter "DPB ECU: a282 d ibrake command counter";
CM_ SG_ 999 DPB_a283_DIbrakeCommandChecksum "DPB ECU: a283 d ibrake command checksum";
CM_ SG_ 999 DPB_a284_DIbrakeCommandDLC "DPB ECU: a284 d ibrake command DLC";
CM_ SG_ 999 DPB_a285_DIbrakeCommandTimeout "DPB ECU: a285 d ibrake command timeout";
CM_ SG_ 999 DPB_a286_ebrCmdStateInvalid "DPB ECU: a286 ebr cmd state invalid";
CM_ SG_ 999 DPB_a287_brakeCmdStateInvalid "DPB ECU: a287 brake cmd state invalid";
CM_ SG_ 999 DPB_a288_PlantDegradedSW "DPB ECU: a288 plant degraded SW";
CM_ SG_ 999 DPB_a289_evacFillNotComplete "DPB ECU: a289 evac fill not complete";
CM_ SG_ 999 DPB_a290_securityInfo "DPB ECU: a290 security info";
CM_ SG_ 999 DPB_a291_extDBRRequestTooLow "DPB ECU: a291 ext DBR request too low";
CM_ SG_ 999 DPB_a292_CBDS_fillBufferThreshol "DPB ECU: a292 CBDS fill buffer threshold";
CM_ SG_ 999 DPB_a293_CBDS_fmeInternalEvent "DPB ECU: a293 CBDS fme internal event";
CM_ SG_ 999 DPB_a294_hbaNormalModeActive "DPB ECU: a294 hba normal mode active";
CM_ SG_ 999 DPB_a295_hbaTrackModeActive "DPB ECU: a295 hba track mode active";
CM_ SG_ 999 DPB_a296_StatInvalid_DI_FullSNA "DPB ECU: a296 stat invalid DI full SNA";
CM_ SG_ 999 DPB_a297_undefinedAlertDetected "DPB ECU: a297 undefined alert detected";
CM_ SG_ 999 DPB_a298_runningPlungerCircuitTe "DPB ECU: a298 running plunger circuit test";
CM_ SG_ 999 DPB_a299_PM_locStateCounter "DPB ECU: a299 PM loc state counter";
CM_ SG_ 999 DPB_a300_PM_locStateChecksum "DPB ECU: a300 PM loc state checksum";
CM_ SG_ 999 DPB_a301_PM_locStateDLC "DPB ECU: a301 PM loc state DLC";
CM_ SG_ 999 DPB_a302_PM_locStateTimeout "DPB ECU: a302 PM loc state timeout";
CM_ SG_ 999 DPB_a303_actuatingDIFullTorqueCm "DPB ECU: a303 actuating DI full torque cmd";
CM_ SG_ 999 DPB_a304_actuatingDITorqueCmd "DPB ECU: a304 actuating DI torque cmd";
CM_ SG_ 999 DPB_a305_DIbrakeTorqueCommandAnd "DPB ECU: a305 d ibrake torque command and flag mismatch";
CM_ SG_ 999 DPB_a306_actuatorFallbackBasicMa "DPB ECU: a306 actuator fallback basic map";
CM_ SG_ 999 DPB_a307_actuatorDegradedMap "DPB ECU: a307 actuator degraded map";
CM_ SG_ 999 DPB_a308_backupMode "DPB ECU: a308 backup mode";
CM_ SG_ 999 DPB_a309_DIFAxleTorqueInvalid "DPB ECU: a309 DIF axle torque invalid";
CM_ SG_ 999 DPB_a310_DIRAxleTorqueInvalid "DPB ECU: a310 DIR axle torque invalid";
CM_ SG_ 999 DPB_a311_postrunDurationTooLong "DPB ECU: a311 postrun duration too long";
CM_ SG_ 999 DPB_a312_continuouslyActivatedVa "DPB ECU: a312 continuously activated valves off";
CM_ SG_ 999 DPB_a313_qualifiedBrakeEventDete "DPB ECU: a313 qualified brake event detected";
CM_ SG_ 999 DPB_a314_runningCyclicVolumeChec "DPB ECU: a314 running cyclic volume check";
CM_ SG_ 999 DPB_a315_runningLeakageAndAirMon "DPB ECU: a315 running leakage and air monitoring";
CM_ SG_ 999 DPB_a316_lowBrakeFluidDetectedOn "DPB ECU: a316 low brake fluid detected on hill slope";
CM_ SG_ 999 DPB_a317_DASredundantBrakingCont "DPB ECU: a317 DA sredundant braking control party checksum";
CM_ SG_ 999 DPB_a318_DASredundantBrakingCont "DPB ECU: a318 DA sredundant braking control party counter";
CM_ SG_ 999 DPB_a319_DASredundantBrakingCont "DPB ECU: a319 DA sredundant braking control party DLC";
CM_ SG_ 999 DPB_a320_DASredundantBrakingCont "DPB ECU: a320 DA sredundant braking control party timeout";
CM_ SG_ 999 DPB_a321_DASredundantBrakingCont "DPB ECU: a321 DA sredundant braking control chassis checksum";
CM_ SG_ 999 DPB_a322_DASredundantBrakingCont "DPB ECU: a322 DA sredundant braking control chassis counter";
CM_ SG_ 999 DPB_a323_DASredundantBrakingCont "DPB ECU: a323 DA sredundant braking control chassis DLC";
CM_ SG_ 999 DPB_a324_DASredundantBrakingCont "DPB ECU: a324 DA sredundant braking control chassis timeout";
CM_ SG_ 999 DPB_a325_DIlocStatus2Checksum "DPB ECU: a325 d iloc status2 checksum";
CM_ SG_ 999 DPB_a326_DIlocStatus2Counter "DPB ECU: a326 d iloc status2 counter";
CM_ SG_ 999 DPB_a327_DIlocStatus2DLC "DPB ECU: a327 d iloc status2 DLC";
CM_ SG_ 999 DPB_a328_DIlocStatus2Timeout "DPB ECU: a328 d iloc status2 timeout";
CM_ SG_ 999 DPB_a329_standaloneEBRActive "DPB ECU: a329 standalone EBR active";
CM_ SG_ 999 DPB_a330_EMCMain11Checksum "DPB ECU: a330 EMC main11 checksum";
CM_ SG_ 999 DPB_a331_EMCMain11Counter "DPB ECU: a331 EMC main11 counter";
CM_ SG_ 999 DPB_a332_EMCMain11DLC "DPB ECU: a332 EMC main11 DLC";
CM_ SG_ 999 DPB_a333_EMCMain11Timeout "DPB ECU: a333 EMC main11 timeout";
CM_ SG_ 999 DPB_a334_EMCMain21Checksum "DPB ECU: a334 EMC main21 checksum";
CM_ SG_ 999 DPB_a335_EMCMain21Counter "DPB ECU: a335 EMC main21 counter";
CM_ SG_ 999 DPB_a336_EMCMain21DLC "DPB ECU: a336 EMC main21 DLC";
CM_ SG_ 999 DPB_a337_EMCMain21Timeout "DPB ECU: a337 EMC main21 timeout";
CM_ BO_ 1592 "Electric power steering (primary) message: uds response CH";
CM_ SG_ 1592 EPAS3P_udsResponseDataCH "Electric power steering (primary): uds response data CH";
CM_ BO_ 1427 "EPASTP ECU message: alert log";
CM_ SG_ 1427 EPASTP_alertID "EPASTP ECU: alert ID";
CM_ SG_ 1427 EPASTP_alertState "EPASTP ECU: alert state";
CM_ SG_ 1427 EPASTP_a001_debugInfo "EPASTP ECU: a001 debug info";
CM_ SG_ 1427 EPASTP_a002_debugInfo "EPASTP ECU: a002 debug info";
CM_ SG_ 1427 EPASTP_a003_debugInfo "EPASTP ECU: a003 debug info";
CM_ SG_ 1427 EPASTP_a004_debugInfo "EPASTP ECU: a004 debug info";
CM_ SG_ 1427 EPASTP_a005_debugInfo "EPASTP ECU: a005 debug info";
CM_ SG_ 1427 EPASTP_a006_debugInfo "EPASTP ECU: a006 debug info";
CM_ SG_ 1427 EPASTP_a007_debugInfo "EPASTP ECU: a007 debug info";
CM_ SG_ 1427 EPASTP_a009_debugInfo "EPASTP ECU: a009 debug info";
CM_ SG_ 1427 EPASTP_a010_debugInfo "EPASTP ECU: a010 debug info";
CM_ SG_ 1427 EPASTP_a011_debugInfo "EPASTP ECU: a011 debug info";
CM_ SG_ 1427 EPASTP_a012_debugInfo "EPASTP ECU: a012 debug info";
CM_ SG_ 1427 EPASTP_a013_debugInfo "EPASTP ECU: a013 debug info";
CM_ SG_ 1427 EPASTP_a014_debugInfo "EPASTP ECU: a014 debug info";
CM_ SG_ 1427 EPASTP_a015_debugInfo "EPASTP ECU: a015 debug info";
CM_ SG_ 1427 EPASTP_a016_debugInfo "EPASTP ECU: a016 debug info";
CM_ SG_ 1427 EPASTP_a017_debugInfo "EPASTP ECU: a017 debug info";
CM_ SG_ 1427 EPASTP_a018_debugInfo "EPASTP ECU: a018 debug info";
CM_ SG_ 1427 EPASTP_a019_debugInfo "EPASTP ECU: a019 debug info";
CM_ SG_ 1427 EPASTP_a020_debugInfo "EPASTP ECU: a020 debug info";
CM_ SG_ 1427 EPASTP_a021_debugInfo "EPASTP ECU: a021 debug info";
CM_ SG_ 1427 EPASTP_a022_debugInfo "EPASTP ECU: a022 debug info";
CM_ SG_ 1427 EPASTP_a023_debugInfo "EPASTP ECU: a023 debug info";
CM_ SG_ 1427 EPASTP_a024_debugInfo "EPASTP ECU: a024 debug info";
CM_ SG_ 1427 EPASTP_a025_debugInfo "EPASTP ECU: a025 debug info";
CM_ SG_ 1427 EPASTP_a026_debugInfo "EPASTP ECU: a026 debug info";
CM_ SG_ 1427 EPASTP_a027_debugInfo "EPASTP ECU: a027 debug info";
CM_ SG_ 1427 EPASTP_a028_debugInfo "EPASTP ECU: a028 debug info";
CM_ SG_ 1427 EPASTP_a029_debugInfo "EPASTP ECU: a029 debug info";
CM_ SG_ 1427 EPASTP_a030_debugInfo "EPASTP ECU: a030 debug info";
CM_ SG_ 1427 EPASTP_a031_debugInfo "EPASTP ECU: a031 debug info";
CM_ SG_ 1427 EPASTP_a032_debugInfo "EPASTP ECU: a032 debug info";
CM_ SG_ 1427 EPASTP_a033_debugInfo "EPASTP ECU: a033 debug info";
CM_ SG_ 1427 EPASTP_a034_debugInfo "EPASTP ECU: a034 debug info";
CM_ SG_ 1427 EPASTP_a035_debugInfo "EPASTP ECU: a035 debug info";
CM_ SG_ 1427 EPASTP_a036_debugInfo "EPASTP ECU: a036 debug info";
CM_ SG_ 1427 EPASTP_a037_debugInfo "EPASTP ECU: a037 debug info";
CM_ SG_ 1427 EPASTP_a038_debugInfo "EPASTP ECU: a038 debug info";
CM_ SG_ 1427 EPASTP_a039_debugInfo "EPASTP ECU: a039 debug info";
CM_ SG_ 1427 EPASTP_a040_debugInfo "EPASTP ECU: a040 debug info";
CM_ SG_ 1427 EPASTP_a041_debugInfo "EPASTP ECU: a041 debug info";
CM_ SG_ 1427 EPASTP_a042_debugInfo "EPASTP ECU: a042 debug info";
CM_ SG_ 1427 EPASTP_a043_debugInfo "EPASTP ECU: a043 debug info";
CM_ SG_ 1427 EPASTP_a044_debugInfo "EPASTP ECU: a044 debug info";
CM_ SG_ 1427 EPASTP_a045_debugInfo "EPASTP ECU: a045 debug info";
CM_ SG_ 1427 EPASTP_a046_debugInfo "EPASTP ECU: a046 debug info";
CM_ SG_ 1427 EPASTP_a047_debugInfo "EPASTP ECU: a047 debug info";
CM_ SG_ 1427 EPASTP_a048_debugInfo "EPASTP ECU: a048 debug info";
CM_ SG_ 1427 EPASTP_a049_debugInfo "EPASTP ECU: a049 debug info";
CM_ SG_ 1427 EPASTP_a050_debugInfo "EPASTP ECU: a050 debug info";
CM_ SG_ 1427 EPASTP_a051_debugInfo "EPASTP ECU: a051 debug info";
CM_ SG_ 1427 EPASTP_a052_debugInfo "EPASTP ECU: a052 debug info";
CM_ SG_ 1427 EPASTP_a053_debugInfo "EPASTP ECU: a053 debug info";
CM_ SG_ 1427 EPASTP_a054_debugInfo "EPASTP ECU: a054 debug info";
CM_ SG_ 1427 EPASTP_a055_debugInfo "EPASTP ECU: a055 debug info";
CM_ SG_ 1427 EPASTP_a056_debugInfo "EPASTP ECU: a056 debug info";
CM_ SG_ 1427 EPASTP_a057_debugInfo "EPASTP ECU: a057 debug info";
CM_ SG_ 1427 EPASTP_a058_debugInfo "EPASTP ECU: a058 debug info";
CM_ SG_ 1427 EPASTP_a059_debugInfo "EPASTP ECU: a059 debug info";
CM_ SG_ 1427 EPASTP_a060_debugInfo "EPASTP ECU: a060 debug info";
CM_ SG_ 1427 EPASTP_a061_debugInfo "EPASTP ECU: a061 debug info";
CM_ SG_ 1427 EPASTP_a062_debugInfo "EPASTP ECU: a062 debug info";
CM_ SG_ 1427 EPASTP_a063_debugInfo "EPASTP ECU: a063 debug info";
CM_ SG_ 1427 EPASTP_a064_debugInfo "EPASTP ECU: a064 debug info";
CM_ SG_ 1427 EPASTP_a065_debugInfo "EPASTP ECU: a065 debug info";
CM_ SG_ 1427 EPASTP_a066_debugInfo "EPASTP ECU: a066 debug info";
CM_ SG_ 1427 EPASTP_a067_debugInfo "EPASTP ECU: a067 debug info";
CM_ SG_ 1427 EPASTP_a068_debugInfo "EPASTP ECU: a068 debug info";
CM_ SG_ 1427 EPASTP_a069_debugInfo "EPASTP ECU: a069 debug info";
CM_ SG_ 1427 EPASTP_a070_debugInfo "EPASTP ECU: a070 debug info";
CM_ SG_ 1427 EPASTP_a071_debugInfo "EPASTP ECU: a071 debug info";
CM_ SG_ 1427 EPASTP_a072_debugInfo "EPASTP ECU: a072 debug info";
CM_ SG_ 1427 EPASTP_a073_debugInfo "EPASTP ECU: a073 debug info";
CM_ SG_ 1427 EPASTP_a074_debugInfo "EPASTP ECU: a074 debug info";
CM_ SG_ 1427 EPASTP_a075_debugInfo "EPASTP ECU: a075 debug info";
CM_ SG_ 1427 EPASTP_a076_debugInfo "EPASTP ECU: a076 debug info";
CM_ SG_ 1427 EPASTP_a077_debugInfo "EPASTP ECU: a077 debug info";
CM_ SG_ 1427 EPASTP_a078_debugInfo "EPASTP ECU: a078 debug info";
CM_ SG_ 1427 EPASTP_a079_debugInfo "EPASTP ECU: a079 debug info";
CM_ SG_ 1427 EPASTP_a080_debugInfo "EPASTP ECU: a080 debug info";
CM_ SG_ 1427 EPASTP_a081_debugInfo "EPASTP ECU: a081 debug info";
CM_ SG_ 1427 EPASTP_a082_debugInfo "EPASTP ECU: a082 debug info";
CM_ SG_ 1427 EPASTP_a083_debugInfo "EPASTP ECU: a083 debug info";
CM_ SG_ 1427 EPASTP_a084_debugInfo "EPASTP ECU: a084 debug info";
CM_ SG_ 1427 EPASTP_a085_debugInfo "EPASTP ECU: a085 debug info";
CM_ SG_ 1427 EPASTP_a086_debugInfo "EPASTP ECU: a086 debug info";
CM_ SG_ 1427 EPASTP_a087_debugInfo "EPASTP ECU: a087 debug info";
CM_ SG_ 1427 EPASTP_a088_debugInfo "EPASTP ECU: a088 debug info";
CM_ SG_ 1427 EPASTP_a089_debugInfo "EPASTP ECU: a089 debug info";
CM_ SG_ 1427 EPASTP_a090_debugInfo "EPASTP ECU: a090 debug info";
CM_ SG_ 1427 EPASTP_a091_debugInfo "EPASTP ECU: a091 debug info";
CM_ SG_ 1427 EPASTP_a092_debugInfo "EPASTP ECU: a092 debug info";
CM_ SG_ 1427 EPASTP_a093_debugInfo "EPASTP ECU: a093 debug info";
CM_ SG_ 1427 EPASTP_a094_debugInfo "EPASTP ECU: a094 debug info";
CM_ SG_ 1427 EPASTP_a095_debugInfo "EPASTP ECU: a095 debug info";
CM_ SG_ 1427 EPASTP_a096_debugInfo "EPASTP ECU: a096 debug info";
CM_ SG_ 1427 EPASTP_a097_debugInfo "EPASTP ECU: a097 debug info";
CM_ SG_ 1427 EPASTP_a098_debugInfo "EPASTP ECU: a098 debug info";
CM_ SG_ 1427 EPASTP_a099_debugInfo "EPASTP ECU: a099 debug info";
CM_ SG_ 1427 EPASTP_a100_debugInfo "EPASTP ECU: a100 debug info";
CM_ SG_ 1427 EPASTP_a101_debugInfo "EPASTP ECU: a101 debug info";
CM_ SG_ 1427 EPASTP_a102_debugInfo "EPASTP ECU: a102 debug info";
CM_ SG_ 1427 EPASTP_a103_debugInfo "EPASTP ECU: a103 debug info";
CM_ SG_ 1427 EPASTP_a104_debugInfo "EPASTP ECU: a104 debug info";
CM_ SG_ 1427 EPASTP_a105_debugInfo "EPASTP ECU: a105 debug info";
CM_ SG_ 1427 EPASTP_a106_debugInfo "EPASTP ECU: a106 debug info";
CM_ SG_ 1427 EPASTP_a107_debugInfo "EPASTP ECU: a107 debug info";
CM_ SG_ 1427 EPASTP_a108_debugInfo "EPASTP ECU: a108 debug info";
CM_ SG_ 1427 EPASTP_a109_debugInfo "EPASTP ECU: a109 debug info";
CM_ SG_ 1427 EPASTP_a110_debugInfo "EPASTP ECU: a110 debug info";
CM_ SG_ 1427 EPASTP_a111_debugInfo "EPASTP ECU: a111 debug info";
CM_ SG_ 1427 EPASTP_a112_debugInfo "EPASTP ECU: a112 debug info";
CM_ SG_ 1427 EPASTP_a113_debugInfo "EPASTP ECU: a113 debug info";
CM_ SG_ 1427 EPASTP_a114_debugInfo "EPASTP ECU: a114 debug info";
CM_ SG_ 1427 EPASTP_a115_debugInfo "EPASTP ECU: a115 debug info";
CM_ SG_ 1427 EPASTP_a116_debugInfo "EPASTP ECU: a116 debug info";
CM_ SG_ 1427 EPASTP_a117_debugInfo "EPASTP ECU: a117 debug info";
CM_ SG_ 1427 EPASTP_a118_debugInfo "EPASTP ECU: a118 debug info";
CM_ SG_ 1427 EPASTP_a119_debugInfo "EPASTP ECU: a119 debug info";
CM_ SG_ 1427 EPASTP_a120_debugInfo "EPASTP ECU: a120 debug info";
CM_ SG_ 1427 EPASTP_a121_debugInfo "EPASTP ECU: a121 debug info";
CM_ SG_ 1427 EPASTP_a122_debugInfo "EPASTP ECU: a122 debug info";
CM_ SG_ 1427 EPASTP_a123_debugInfo "EPASTP ECU: a123 debug info";
CM_ SG_ 1427 EPASTP_a124_debugInfo "EPASTP ECU: a124 debug info";
CM_ SG_ 1427 EPASTP_a125_debugInfo "EPASTP ECU: a125 debug info";
CM_ SG_ 1427 EPASTP_a126_debugInfo "EPASTP ECU: a126 debug info";
CM_ SG_ 1427 EPASTP_a127_debugInfo "EPASTP ECU: a127 debug info";
CM_ SG_ 1427 EPASTP_a128_debugInfo "EPASTP ECU: a128 debug info";
CM_ SG_ 1427 EPASTP_a129_debugInfo "EPASTP ECU: a129 debug info";
CM_ SG_ 1427 EPASTP_a130_debugInfo "EPASTP ECU: a130 debug info";
CM_ SG_ 1427 EPASTP_a131_debugInfo "EPASTP ECU: a131 debug info";
CM_ SG_ 1427 EPASTP_a132_debugInfo "EPASTP ECU: a132 debug info";
CM_ SG_ 1427 EPASTP_a133_debugInfo "EPASTP ECU: a133 debug info";
CM_ SG_ 1427 EPASTP_a134_debugInfo "EPASTP ECU: a134 debug info";
CM_ SG_ 1427 EPASTP_a135_debugInfo "EPASTP ECU: a135 debug info";
CM_ SG_ 1427 EPASTP_a136_debugInfo "EPASTP ECU: a136 debug info";
CM_ SG_ 1427 EPASTP_a137_debugInfo "EPASTP ECU: a137 debug info";
CM_ SG_ 1427 EPASTP_a138_debugInfo "EPASTP ECU: a138 debug info";
CM_ SG_ 1427 EPASTP_a139_debugInfo "EPASTP ECU: a139 debug info";
CM_ SG_ 1427 EPASTP_a140_debugInfo "EPASTP ECU: a140 debug info";
CM_ SG_ 1427 EPASTP_a141_debugInfo "EPASTP ECU: a141 debug info";
CM_ SG_ 1427 EPASTP_a142_debugInfo "EPASTP ECU: a142 debug info";
CM_ SG_ 1427 EPASTP_a143_debugInfo "EPASTP ECU: a143 debug info";
CM_ SG_ 1427 EPASTP_a144_debugInfo "EPASTP ECU: a144 debug info";
CM_ SG_ 1427 EPASTP_a145_debugInfo "EPASTP ECU: a145 debug info";
CM_ SG_ 1427 EPASTP_a146_debugInfo "EPASTP ECU: a146 debug info";
CM_ SG_ 1427 EPASTP_a147_debugInfo "EPASTP ECU: a147 debug info";
CM_ SG_ 1427 EPASTP_a148_debugInfo "EPASTP ECU: a148 debug info";
CM_ SG_ 1427 EPASTP_a149_debugInfo "EPASTP ECU: a149 debug info";
CM_ SG_ 1427 EPASTP_a150_debugInfo "EPASTP ECU: a150 debug info";
CM_ SG_ 1427 EPASTP_a152_debugInfo "EPASTP ECU: a152 debug info";
CM_ SG_ 1427 EPASTP_a153_debugInfo "EPASTP ECU: a153 debug info";
CM_ SG_ 1427 EPASTP_a154_debugInfo "EPASTP ECU: a154 debug info";
CM_ SG_ 1427 EPASTP_a155_debugInfo "EPASTP ECU: a155 debug info";
CM_ SG_ 1427 EPASTP_a156_debugInfo "EPASTP ECU: a156 debug info";
CM_ SG_ 1427 EPASTP_a157_debugInfo "EPASTP ECU: a157 debug info";
CM_ SG_ 1427 EPASTP_a158_debugInfo "EPASTP ECU: a158 debug info";
CM_ SG_ 1427 EPASTP_a159_debugInfo "EPASTP ECU: a159 debug info";
CM_ SG_ 1427 EPASTP_a160_debugInfo "EPASTP ECU: a160 debug info";
CM_ SG_ 1427 EPASTP_a161_debugInfo "EPASTP ECU: a161 debug info";
CM_ SG_ 1427 EPASTP_a162_debugInfo "EPASTP ECU: a162 debug info";
CM_ SG_ 1427 EPASTP_a163_debugInfo "EPASTP ECU: a163 debug info";
CM_ SG_ 1427 EPASTP_a164_debugInfo "EPASTP ECU: a164 debug info";
CM_ SG_ 1427 EPASTP_a165_debugInfo "EPASTP ECU: a165 debug info";
CM_ SG_ 1427 EPASTP_a166_debugInfo "EPASTP ECU: a166 debug info";
CM_ SG_ 1427 EPASTP_a167_debugInfo "EPASTP ECU: a167 debug info";
CM_ SG_ 1427 EPASTP_a168_debugInfo "EPASTP ECU: a168 debug info";
CM_ SG_ 1427 EPASTP_a169_debugInfo "EPASTP ECU: a169 debug info";
CM_ SG_ 1427 EPASTP_a170_debugInfo "EPASTP ECU: a170 debug info";
CM_ SG_ 1427 EPASTP_a171_debugInfo "EPASTP ECU: a171 debug info";
CM_ SG_ 1427 EPASTP_a172_debugInfo "EPASTP ECU: a172 debug info";
CM_ SG_ 1427 EPASTP_a173_debugInfo "EPASTP ECU: a173 debug info";
CM_ SG_ 1427 EPASTP_a174_debugInfo "EPASTP ECU: a174 debug info";
CM_ SG_ 1427 EPASTP_a175_debugInfo "EPASTP ECU: a175 debug info";
CM_ SG_ 1427 EPASTP_a176_debugInfo "EPASTP ECU: a176 debug info";
CM_ SG_ 1427 EPASTP_a177_debugInfo "EPASTP ECU: a177 debug info";
CM_ SG_ 1427 EPASTP_a178_debugInfo "EPASTP ECU: a178 debug info";
CM_ SG_ 1427 EPASTP_a179_debugInfo "EPASTP ECU: a179 debug info";
CM_ SG_ 1427 EPASTP_a180_debugInfo "EPASTP ECU: a180 debug info";
CM_ SG_ 1427 EPASTP_a181_debugInfo "EPASTP ECU: a181 debug info";
CM_ SG_ 1427 EPASTP_a182_debugInfo "EPASTP ECU: a182 debug info";
CM_ SG_ 1427 EPASTP_a183_debugInfo "EPASTP ECU: a183 debug info";
CM_ SG_ 1427 EPASTP_a184_debugInfo "EPASTP ECU: a184 debug info";
CM_ SG_ 1427 EPASTP_a185_debugInfo "EPASTP ECU: a185 debug info";
CM_ SG_ 1427 EPASTP_a186_debugInfo "EPASTP ECU: a186 debug info";
CM_ SG_ 1427 EPASTP_a188_debugInfo "EPASTP ECU: a188 debug info";
CM_ SG_ 1427 EPASTP_a189_debugInfo "EPASTP ECU: a189 debug info";
CM_ SG_ 1427 EPASTP_a190_debugInfo "EPASTP ECU: a190 debug info";
CM_ SG_ 1427 EPASTP_a191_debugInfo "EPASTP ECU: a191 debug info";
CM_ SG_ 1427 EPASTP_a192_debugInfo "EPASTP ECU: a192 debug info";
CM_ SG_ 1427 EPASTP_a193_debugInfo "EPASTP ECU: a193 debug info";
CM_ SG_ 1427 EPASTP_a194_debugInfo "EPASTP ECU: a194 debug info";
CM_ SG_ 1427 EPASTP_a195_debugInfo "EPASTP ECU: a195 debug info";
CM_ SG_ 1427 EPASTP_a196_debugInfo "EPASTP ECU: a196 debug info";
CM_ SG_ 1427 EPASTP_a197_debugInfo "EPASTP ECU: a197 debug info";
CM_ SG_ 1427 EPASTP_a198_debugInfo "EPASTP ECU: a198 debug info";
CM_ SG_ 1427 EPASTP_a199_debugInfo "EPASTP ECU: a199 debug info";
CM_ SG_ 1427 EPASTP_a200_debugInfo "EPASTP ECU: a200 debug info";
CM_ SG_ 1427 EPASTP_a201_debugInfo "EPASTP ECU: a201 debug info";
CM_ SG_ 1427 EPASTP_a202_debugInfo "EPASTP ECU: a202 debug info";
CM_ SG_ 1427 EPASTP_a203_debugInfo "EPASTP ECU: a203 debug info";
CM_ SG_ 1427 EPASTP_a204_debugInfo "EPASTP ECU: a204 debug info";
CM_ SG_ 1427 EPASTP_a205_debugInfo "EPASTP ECU: a205 debug info";
CM_ SG_ 1427 EPASTP_a206_debugInfo "EPASTP ECU: a206 debug info";
CM_ SG_ 1427 EPASTP_a207_debugInfo "EPASTP ECU: a207 debug info";
CM_ SG_ 1427 EPASTP_a208_debugInfo "EPASTP ECU: a208 debug info";
CM_ SG_ 1427 EPASTP_a209_debugInfo "EPASTP ECU: a209 debug info";
CM_ SG_ 1427 EPASTP_a210_debugInfo "EPASTP ECU: a210 debug info";
CM_ SG_ 1427 EPASTP_a211_debugInfo "EPASTP ECU: a211 debug info";
CM_ SG_ 1427 EPASTP_a212_debugInfo "EPASTP ECU: a212 debug info";
CM_ SG_ 1427 EPASTP_a213_debugInfo "EPASTP ECU: a213 debug info";
CM_ SG_ 1427 EPASTP_a214_debugInfo "EPASTP ECU: a214 debug info";
CM_ SG_ 1427 EPASTP_a215_debugInfo "EPASTP ECU: a215 debug info";
CM_ SG_ 1427 EPASTP_a216_debugInfo "EPASTP ECU: a216 debug info";
CM_ SG_ 1427 EPASTP_a217_debugInfo "EPASTP ECU: a217 debug info";
CM_ SG_ 1427 EPASTP_a218_debugInfo "EPASTP ECU: a218 debug info";
CM_ SG_ 1427 EPASTP_a219_debugInfo "EPASTP ECU: a219 debug info";
CM_ SG_ 1427 EPASTP_a221_debugInfo "EPASTP ECU: a221 debug info";
CM_ SG_ 1427 EPASTP_a222_debugInfo "EPASTP ECU: a222 debug info";
CM_ SG_ 1427 EPASTP_a223_debugInfo "EPASTP ECU: a223 debug info";
CM_ SG_ 1427 EPASTP_a224_debugInfo "EPASTP ECU: a224 debug info";
CM_ SG_ 1427 EPASTP_a225_debugInfo "EPASTP ECU: a225 debug info";
CM_ SG_ 1427 EPASTP_a226_debugInfo "EPASTP ECU: a226 debug info";
CM_ SG_ 1427 EPASTP_a227_debugInfo "EPASTP ECU: a227 debug info";
CM_ SG_ 1427 EPASTP_a228_debugInfo "EPASTP ECU: a228 debug info";
CM_ SG_ 1427 EPASTP_a229_debugInfo "EPASTP ECU: a229 debug info";
CM_ SG_ 1427 EPASTP_a230_debugInfo "EPASTP ECU: a230 debug info";
CM_ SG_ 1427 EPASTP_a231_debugInfo "EPASTP ECU: a231 debug info";
CM_ SG_ 1427 EPASTP_a232_debugInfo "EPASTP ECU: a232 debug info";
CM_ SG_ 1427 EPASTP_a233_debugInfo "EPASTP ECU: a233 debug info";
CM_ SG_ 1427 EPASTP_a234_debugInfo "EPASTP ECU: a234 debug info";
CM_ SG_ 1427 EPASTP_a235_debugInfo "EPASTP ECU: a235 debug info";
CM_ SG_ 1427 EPASTP_a236_debugInfo "EPASTP ECU: a236 debug info";
CM_ SG_ 1427 EPASTP_a237_debugInfo "EPASTP ECU: a237 debug info";
CM_ SG_ 1427 EPASTP_a238_debugInfo "EPASTP ECU: a238 debug info";
CM_ SG_ 1427 EPASTP_a239_debugInfo "EPASTP ECU: a239 debug info";
CM_ SG_ 1427 EPASTP_a240_debugInfo "EPASTP ECU: a240 debug info";
CM_ SG_ 1427 EPASTP_a241_debugInfo "EPASTP ECU: a241 debug info";
CM_ SG_ 1427 EPASTP_a242_debugInfo "EPASTP ECU: a242 debug info";
CM_ SG_ 1427 EPASTP_a243_debugInfo "EPASTP ECU: a243 debug info";
CM_ SG_ 1427 EPASTP_a244_debugInfo "EPASTP ECU: a244 debug info";
CM_ SG_ 1427 EPASTP_a245_debugInfo "EPASTP ECU: a245 debug info";
CM_ SG_ 1427 EPASTP_a246_debugInfo "EPASTP ECU: a246 debug info";
CM_ SG_ 1427 EPASTP_a247_debugInfo "EPASTP ECU: a247 debug info";
CM_ SG_ 1427 EPASTP_a248_debugInfo "EPASTP ECU: a248 debug info";
CM_ SG_ 1427 EPASTP_a249_debugInfo "EPASTP ECU: a249 debug info";
CM_ SG_ 1427 EPASTP_a250_debugInfo "EPASTP ECU: a250 debug info";
CM_ SG_ 1427 EPASTP_a252_debugInfo "EPASTP ECU: a252 debug info";
CM_ SG_ 1427 EPASTP_a253_debugInfo "EPASTP ECU: a253 debug info";
CM_ SG_ 1427 EPASTP_a254_debugInfo "EPASTP ECU: a254 debug info";
CM_ SG_ 1427 EPASTP_a255_debugInfo "EPASTP ECU: a255 debug info";
CM_ SG_ 1427 EPASTP_a256_debugInfo "EPASTP ECU: a256 debug info";
CM_ SG_ 1427 EPASTP_a257_debugInfo "EPASTP ECU: a257 debug info";
CM_ SG_ 1427 EPASTP_a258_debugInfo "EPASTP ECU: a258 debug info";
CM_ SG_ 1427 EPASTP_a259_debugInfo "EPASTP ECU: a259 debug info";
CM_ SG_ 1427 EPASTP_a260_debugInfo "EPASTP ECU: a260 debug info";
CM_ SG_ 1427 EPASTP_a261_debugInfo "EPASTP ECU: a261 debug info";
CM_ SG_ 1427 EPASTP_a262_debugInfo "EPASTP ECU: a262 debug info";
CM_ SG_ 1427 EPASTP_a263_debugInfo "EPASTP ECU: a263 debug info";
CM_ SG_ 1427 EPASTP_a264_degradedECU "EPASTP ECU: a264 degraded ECU";
CM_ SG_ 1427 EPASTP_a264_vehicleSpeed "EPASTP ECU: a264 vehicle speed";
CM_ SG_ 1427 EPASTP_a264_powerRatio "EPASTP ECU: a264 power ratio";
CM_ SG_ 1427 EPASTP_a264_ownSideDegradationRe "EPASTP ECU: a264 own side degradation reason";
CM_ SG_ 1427 EPASTP_a264_otherSideDegradation "EPASTP ECU: a264 other side degradation reason";
CM_ SG_ 1427 EPASTP_a265_degradedECU "EPASTP ECU: a265 degraded ECU";
CM_ SG_ 1427 EPASTP_a265_vehicleSpeed "EPASTP ECU: a265 vehicle speed";
CM_ SG_ 1427 EPASTP_a265_rawMcuTemperature "EPASTP ECU: a265 raw mcu temperature";
CM_ SG_ 1427 EPASTP_a265_degradedCurrentLimit "EPASTP ECU: a265 degraded current limit";
CM_ SG_ 1427 EPASTP_a266_cdpAssistFactor "EPASTP ECU: a266 cdp assist factor";
CM_ SG_ 1427 EPASTP_a266_vehicleSpeed "EPASTP ECU: a266 vehicle speed";
CM_ SG_ 1427 EPASTP_a267_vehicleSpeed "EPASTP ECU: a267 vehicle speed";
CM_ SG_ 1427 EPASTP_a267_velocityEstimatorSta "EPASTP ECU: a267 velocity estimator state";
CM_ SG_ 1427 EPASTP_a269_vehicleSpeed "EPASTP ECU: a269 vehicle speed";
CM_ SG_ 1427 EPASTP_a270_debugInfo "EPASTP ECU: a270 debug info";
BA_DEF_ BO_ "GenMsgCycleTime" INT 0 3600000;
BA_DEF_ BO_ "GenMsgSendType" ENUM "Cyclic","NotUsed","NotUsed","NotUsed","NotUsed","NotUsed","NotUsed","IfActive","NoMsgSendType","NotUsed";
BA_DEF_ BO_ "VFrameFormat" ENUM "StandardCAN","ExtendedCAN","reserved","J1939PG","reserved","reserved","reserved","reserved","reserved","reserved","reserved","reserved","reserved","reserved","StandardCAN_FD","ExtendedCAN_FD";
BA_DEF_ BO_ "CANFD_BRS" ENUM "0","1";
BA_DEF_ SG_ "GenSigSNA" STRING;
BA_DEF_ SG_ "SystemSignalLongSymbol" STRING;
BA_DEF_ SG_ "Confidence" ENUM "validated","plausible","layout-only","contradicted";
BA_DEF_DEF_ "GenMsgCycleTime" 0;
BA_DEF_DEF_ "GenMsgSendType" "NoMsgSendType";
BA_DEF_DEF_ "VFrameFormat" "StandardCAN";
BA_DEF_DEF_ "CANFD_BRS" "1";
BA_DEF_DEF_ "GenSigSNA" "";
BA_DEF_DEF_ "SystemSignalLongSymbol" "";
BA_DEF_DEF_ "Confidence" "layout-only";
BA_ "GenMsgCycleTime" BO_ 942 1000;
BA_ "GenMsgSendType" BO_ 942 0;
BA_ "GenMsgCycleTime" BO_ 976 1000;
BA_ "GenMsgSendType" BO_ 976 0;
BA_ "GenMsgCycleTime" BO_ 1003 1000;
BA_ "GenMsgSendType" BO_ 1003 0;
BA_ "GenMsgCycleTime" BO_ 943 10;
BA_ "GenMsgSendType" BO_ 943 0;
BA_ "GenMsgCycleTime" BO_ 551 100;
BA_ "GenMsgSendType" BO_ 551 0;
BA_ "GenMsgCycleTime" BO_ 778 30;
BA_ "GenMsgSendType" BO_ 778 0;
BA_ "GenMsgCycleTime" BO_ 781 250;
BA_ "GenMsgSendType" BO_ 781 0;
BA_ "GenMsgCycleTime" BO_ 1548 5;
BA_ "GenMsgSendType" BO_ 1548 0;
BA_ "GenMsgCycleTime" BO_ 999 1000;
BA_ "GenMsgSendType" BO_ 999 0;
BA_ "SystemSignalLongSymbol" SG_ 976 APSB_w215_contDriverNotIntractin "APSB_w215_contDriverNotIntracting";
BA_ "SystemSignalLongSymbol" SG_ 976 APSB_w245_eloopRxFromUnexpectedS "APSB_w245_eloopRxFromUnexpectedSourceMAC";
BA_ "SystemSignalLongSymbol" SG_ 976 APSB_w246_ethloopSwitchPortLinkD "APSB_w246_ethloopSwitchPortLinkDown";
BA_ "SystemSignalLongSymbol" SG_ 976 APSB_w250_ethloopSwitchMemUsageT "APSB_w250_ethloopSwitchMemUsageTooHighPort2";
BA_ "SystemSignalLongSymbol" SG_ 976 APSB_w251_ethloopSwitchMemUsageT "APSB_w251_ethloopSwitchMemUsageTooHighPort3";
BA_ "SystemSignalLongSymbol" SG_ 1003 APSB_w258_qspiFlashSectorChecksu "APSB_w258_qspiFlashSectorChecksumMismatch";
BA_ "SystemSignalLongSymbol" SG_ 1003 APSB_w269_ethSwitchRxPageCountTo "APSB_w269_ethSwitchRxPageCountTooHighPort0_3";
BA_ "SystemSignalLongSymbol" SG_ 1003 APSB_w270_ethSwitchRxPageCountTo "APSB_w270_ethSwitchRxPageCountTooHighPort4_7";
BA_ "SystemSignalLongSymbol" SG_ 1003 APSB_w284_cam12VBuckBoostAPwrIss "APSB_w284_cam12VBuckBoostAPwrIssue";
BA_ "SystemSignalLongSymbol" SG_ 1003 APSB_w285_cam12VBuckBoostBPwrIss "APSB_w285_cam12VBuckBoostBPwrIssue";
BA_ "SystemSignalLongSymbol" SG_ 1003 APSB_w286_cam12VEFuseAPrimaryIss "APSB_w286_cam12VEFuseAPrimaryIssue";
BA_ "SystemSignalLongSymbol" SG_ 1003 APSB_w287_cam12VEFuseASecondaryI "APSB_w287_cam12VEFuseASecondaryIssue";
BA_ "SystemSignalLongSymbol" SG_ 1003 APSB_w289_turboTemperatureWarnin "APSB_w289_turboTemperatureWarning";
BA_ "SystemSignalLongSymbol" SG_ 1003 APSB_w290_cam12VBuckBoostBPwrRin "APSB_w290_cam12VBuckBoostBPwrRinging";
BA_ "SystemSignalLongSymbol" SG_ 1003 APSB_w296_wdogMonTaskDeadlineMis "APSB_w296_wdogMonTaskDeadlineMiss";
BA_ "SystemSignalLongSymbol" SG_ 1003 APSB_w298_cpuToApCanSharedMemErr "APSB_w298_cpuToApCanSharedMemError";
BA_ "SystemSignalLongSymbol" SG_ 1003 APSB_w299_apToCpuCanSharedMemErr "APSB_w299_apToCpuCanSharedMemError";
BA_ "SystemSignalLongSymbol" SG_ 1003 APSB_w300_sharedMemoryAccessErro "APSB_w300_sharedMemoryAccessError";
BA_ "SystemSignalLongSymbol" SG_ 1003 APSB_w318_ethernetNetworkBufferH "APSB_w318_ethernetNetworkBufferHighWatermark";
BA_ "SystemSignalLongSymbol" SG_ 1003 APSB_w320_eplannerPreconditionsM "APSB_w320_eplannerPreconditionsMet";
BA_ "Confidence" SG_ 943 BB_statusChecksum 0;
BA_ "Confidence" SG_ 943 BB_statusCounter 0;
BA_ "Confidence" SG_ 943 BB_sOutputRod 0;
BA_ "Confidence" SG_ 943 BB_sOutputRodQF 0;
BA_ "Confidence" SG_ 943 BB_sInputRod 0;
BA_ "Confidence" SG_ 943 BB_sInputRodQF 0;
BA_ "Confidence" SG_ 943 BB_driverBrakeApply 0;
BA_ "Confidence" SG_ 943 BB_driverBrakeApplyQF 0;
BA_ "Confidence" SG_ 943 BB_boosterStatus 0;
BA_ "Confidence" SG_ 943 BB_warningLampRequest 0;
BA_ "Confidence" SG_ 943 BB_brakeFluidLevel 0;
BA_ "Confidence" SG_ 943 BB_internalState 0;
BA_ "Confidence" SG_ 943 BB_unfilteredFluidLevelLow 0;
BA_ "Confidence" SG_ 551 CMP_inputHVVoltage 0;
BA_ "Confidence" SG_ 551 CMP_inputLVVoltage 0;
BA_ "Confidence" SG_ 551 CMP_inputHVCurrent 0;
BA_ "Confidence" SG_ 551 CMP_inputHVPower 0;
BA_ "Confidence" SG_ 778 DAS_objectId 1;
BA_ "Confidence" SG_ 778 DAS_leadVehType 0;
BA_ "Confidence" SG_ 778 DAS_leadVehRelevantForControl 0;
BA_ "Confidence" SG_ 778 DAS_leadVehDx 0;
BA_ "GenSigSNA" SG_ 778 DAS_leadVehDx "255";
BA_ "Confidence" SG_ 778 DAS_leadVehVxRel 0;
BA_ "GenSigSNA" SG_ 778 DAS_leadVehVxRel "15";
BA_ "Confidence" SG_ 778 DAS_leadVehDy 0;
BA_ "Confidence" SG_ 778 DAS_leadVehId 0;
BA_ "GenSigSNA" SG_ 778 DAS_leadVehId "127";
BA_ "Confidence" SG_ 778 DAS_leadVeh2Type 0;
BA_ "Confidence" SG_ 778 DAS_leadVeh2RelevantForControl 0;
BA_ "Confidence" SG_ 778 DAS_leadVeh2Dx 0;
BA_ "GenSigSNA" SG_ 778 DAS_leadVeh2Dx "255";
BA_ "Confidence" SG_ 778 DAS_leadVeh2VxRel 0;
BA_ "GenSigSNA" SG_ 778 DAS_leadVeh2VxRel "15";
BA_ "Confidence" SG_ 778 DAS_leadVeh2Dy 0;
BA_ "Confidence" SG_ 778 DAS_leadVeh2Id 0;
BA_ "GenSigSNA" SG_ 778 DAS_leadVeh2Id "0";
BA_ "Confidence" SG_ 778 DAS_leftVehType 0;
BA_ "Confidence" SG_ 778 DAS_leftVehRelevantForControl 0;
BA_ "Confidence" SG_ 778 DAS_leftVehDx 0;
BA_ "GenSigSNA" SG_ 778 DAS_leftVehDx "255";
BA_ "Confidence" SG_ 778 DAS_leftVehVxRel 0;
BA_ "GenSigSNA" SG_ 778 DAS_leftVehVxRel "15";
BA_ "Confidence" SG_ 778 DAS_leftVehDy 0;
BA_ "Confidence" SG_ 778 DAS_leftVehId 0;
BA_ "GenSigSNA" SG_ 778 DAS_leftVehId "127";
BA_ "Confidence" SG_ 778 DAS_leftVeh2Type 0;
BA_ "Confidence" SG_ 778 DAS_leftVeh2RelevantForControl 0;
BA_ "Confidence" SG_ 778 DAS_leftVeh2Dx 0;
BA_ "GenSigSNA" SG_ 778 DAS_leftVeh2Dx "255";
BA_ "Confidence" SG_ 778 DAS_leftVeh2VxRel 0;
BA_ "GenSigSNA" SG_ 778 DAS_leftVeh2VxRel "15";
BA_ "Confidence" SG_ 778 DAS_leftVeh2Dy 0;
BA_ "Confidence" SG_ 778 DAS_leftVeh2Id 0;
BA_ "GenSigSNA" SG_ 778 DAS_leftVeh2Id "0";
BA_ "Confidence" SG_ 778 DAS_rightVehType 0;
BA_ "Confidence" SG_ 778 DAS_rightVehRelevantForControl 0;
BA_ "Confidence" SG_ 778 DAS_rightVehDx 0;
BA_ "GenSigSNA" SG_ 778 DAS_rightVehDx "255";
BA_ "Confidence" SG_ 778 DAS_rightVehVxRel 0;
BA_ "GenSigSNA" SG_ 778 DAS_rightVehVxRel "15";
BA_ "Confidence" SG_ 778 DAS_rightVehDy 0;
BA_ "Confidence" SG_ 778 DAS_rightVehId 0;
BA_ "GenSigSNA" SG_ 778 DAS_rightVehId "127";
BA_ "Confidence" SG_ 778 DAS_rightVeh2Type 0;
BA_ "Confidence" SG_ 778 DAS_rightVeh2RelevantForControl 0;
BA_ "Confidence" SG_ 778 DAS_rightVeh2Dx 0;
BA_ "GenSigSNA" SG_ 778 DAS_rightVeh2Dx "255";
BA_ "Confidence" SG_ 778 DAS_rightVeh2VxRel 0;
BA_ "GenSigSNA" SG_ 778 DAS_rightVeh2VxRel "15";
BA_ "Confidence" SG_ 778 DAS_rightVeh2Dy 0;
BA_ "Confidence" SG_ 778 DAS_rightVeh2Id 0;
BA_ "GenSigSNA" SG_ 778 DAS_rightVeh2Id "0";
BA_ "Confidence" SG_ 778 DAS_cutinVehType 0;
BA_ "Confidence" SG_ 778 DAS_cutinVehRelevantForControl 0;
BA_ "Confidence" SG_ 778 DAS_cutinVehDx 0;
BA_ "GenSigSNA" SG_ 778 DAS_cutinVehDx "255";
BA_ "Confidence" SG_ 778 DAS_cutinVehVxRel 0;
BA_ "GenSigSNA" SG_ 778 DAS_cutinVehVxRel "15";
BA_ "Confidence" SG_ 778 DAS_cutinVehDy 0;
BA_ "Confidence" SG_ 778 DAS_cutinVehId 0;
BA_ "GenSigSNA" SG_ 778 DAS_cutinVehId "127";
BA_ "Confidence" SG_ 778 DAS_roadSignColor 0;
BA_ "Confidence" SG_ 778 DAS_roadSignId 0;
BA_ "GenSigSNA" SG_ 778 DAS_roadSignId "255";
BA_ "Confidence" SG_ 778 DAS_roadSignStopLineDist 0;
BA_ "GenSigSNA" SG_ 778 DAS_roadSignStopLineDist "1023";
BA_ "Confidence" SG_ 778 DAS_roadSignControlActive 0;
BA_ "Confidence" SG_ 778 DAS_roadSignSource 0;
BA_ "Confidence" SG_ 778 DAS_roadSignArrow 0;
BA_ "Confidence" SG_ 778 DAS_roadSignOrientation 0;
BA_ "Confidence" SG_ 781 DAS_positioningEngineStatusMulti 1;
BA_ "SystemSignalLongSymbol" SG_ 781 DAS_positioningEngineStatusMulti "DAS_positioningEngineStatusMultiplexer";
BA_ "Confidence" SG_ 781 DAS_meoSolverNumRuns 0;
BA_ "Confidence" SG_ 781 DAS_meoSolverReportTerminationTy 0;
BA_ "SystemSignalLongSymbol" SG_ 781 DAS_meoSolverReportTerminationTy "DAS_meoSolverReportTerminationType";
BA_ "Confidence" SG_ 781 DAS_meoSolverReportTotalTimeS 0;
BA_ "Confidence" SG_ 781 DAS_meoHorizontalAccuracyM 0;
BA_ "Confidence" SG_ 781 DAS_meoVerticalAccuracyM 0;
BA_ "Confidence" SG_ 781 DAS_meoHeadingAccuracyDeg 0;
BA_ "Confidence" SG_ 781 DAS_meoHeadingValid 0;
BA_ "Confidence" SG_ 781 DAS_meoNumSatellitesUsed 0;
BA_ "Confidence" SG_ 781 DAS_meoGpsQualityLevel 0;
BA_ "Confidence" SG_ 781 DAS_meoFixType 0;
BA_ "Confidence" SG_ 781 DAS_meoResetCount 0;
BA_ "Confidence" SG_ 781 DAS_lastMeoResetReason 0;
BA_ "Confidence" SG_ 781 DAS_vioMultiGpsSelectedSource 0;
BA_ "Confidence" SG_ 781 DAS_vioMultiGpsPeCooldownActive 0;
BA_ "Confidence" SG_ 781 DAS_vioMultiGpsPeSppTdcpConsiste 0;
BA_ "SystemSignalLongSymbol" SG_ 781 DAS_vioMultiGpsPeSppTdcpConsiste "DAS_vioMultiGpsPeSppTdcpConsistentWithRawGps";
BA_ "Confidence" SG_ 781 DAS_vioMultiGpsPeMeoConsistentWi 0;
BA_ "SystemSignalLongSymbol" SG_ 781 DAS_vioMultiGpsPeMeoConsistentWi "DAS_vioMultiGpsPeMeoConsistentWithRawGps";
BA_ "Confidence" SG_ 781 DAS_vioMultiGpsPeSppTdcpVsR_0001 0;
BA_ "SystemSignalLongSymbol" SG_ 781 DAS_vioMultiGpsPeSppTdcpVsR_0001 "DAS_vioMultiGpsPeSppTdcpVsRawGpsTransDiscrepM";
BA_ "Confidence" SG_ 781 DAS_vioMultiGpsPeMeoVsRawGpsTran 0;
BA_ "SystemSignalLongSymbol" SG_ 781 DAS_vioMultiGpsPeMeoVsRawGpsTran "DAS_vioMultiGpsPeMeoVsRawGpsTransDiscrepM";
BA_ "Confidence" SG_ 781 DAS_vioMultiGpsPeSppTdcpVsRawGps 0;
BA_ "SystemSignalLongSymbol" SG_ 781 DAS_vioMultiGpsPeSppTdcpVsRawGps "DAS_vioMultiGpsPeSppTdcpVsRawGpsRotDiscrepDeg";
BA_ "Confidence" SG_ 781 DAS_vioMultiGpsPeMeoVsRawGpsRotD 0;
BA_ "SystemSignalLongSymbol" SG_ 781 DAS_vioMultiGpsPeMeoVsRawGpsRotD "DAS_vioMultiGpsPeMeoVsRawGpsRotDiscrepDeg";
BA_ "Confidence" SG_ 781 DAS_publishedGpsSource 0;
BA_ "Confidence" SG_ 781 DAS_bluefinEnabled 0;
BA_ "Confidence" SG_ 781 DAS_orioleDisabled 0;
BA_ "Confidence" SG_ 781 DAS_disableMonarch 0;
BA_ "Confidence" SG_ 1548 DAS_TR_ObjIndex 1;
BA_ "Confidence" SG_ 1548 DAS_TR_Counter 0;
BA_ "Confidence" SG_ 1548 DAS_TR_Obj00_Class 0;
BA_ "Confidence" SG_ 1548 DAS_TR_Obj00_Dx 0;
BA_ "Confidence" SG_ 1548 DAS_TR_Obj00_Dy 0;
BA_ "Confidence" SG_ 1548 DAS_TR_Obj00_Vx 0;
BA_ "Confidence" SG_ 1548 DAS_TR_Obj00_RCS 0;
BA_ "Confidence" SG_ 1548 DAS_TR_Obj00_Length 0;
BA_ "Confidence" SG_ 1548 DAS_TR_Obj00_MovingState 0;
BA_ "Confidence" SG_ 1548 DAS_TR_Obj00_Dz 0;
BA_ "Confidence" SG_ 1548 DAS_TR_Obj00_Exist 0;
BA_ "Confidence" SG_ 1237 DPB_alertID 1;
BA_ "Confidence" SG_ 1237 DPB_alertState 1;
BA_ "Confidence" SG_ 999 DPB_matrixIndex 1;
BA_ "SystemSignalLongSymbol" SG_ 999 DPB_a001_pPlungerSensorOffsetHig "DPB_a001_pPlungerSensorOffsetHigh";
BA_ "SystemSignalLongSymbol" SG_ 999 DPB_a018_largeLeakageDetectedGoo "DPB_a018_largeLeakageDetectedGoodCheck";
BA_ "SystemSignalLongSymbol" SG_ 999 DPB_a023_initialPlungerCheckFail "DPB_a023_initialPlungerCheckFailed";
BA_ "SystemSignalLongSymbol" SG_ 999 DPB_a035_PDURouterinitialization "DPB_a035_PDURouterinitializationFailed";
BA_ "SystemSignalLongSymbol" SG_ 999 DPB_a036_lossOfPDUInstanceDetect "DPB_a036_lossOfPDUInstanceDetected";
BA_ "SystemSignalLongSymbol" SG_ 999 DPB_a038_plungerCircuitPressHigh "DPB_a038_plungerCircuitPressHighGoodCheck";
BA_ "SystemSignalLongSymbol" SG_ 999 DPB_a040_plungerCircuitPressLowG "DPB_a040_plungerCircuitPressLowGoodCheck";
BA_ "SystemSignalLongSymbol" SG_ 999 DPB_a042_motorLoadPressImplausib "DPB_a042_motorLoadPressImplausible";
BA_ "SystemSignalLongSymbol" SG_ 999 DPB_a047_pPlungerPlausCheckFailu "DPB_a047_pPlungerPlausCheckFailure";
BA_ "SystemSignalLongSymbol" SG_ 999 DPB_a053_hydraulicAssemblyModeAc "DPB_a053_hydraulicAssemblyModeActive";
BA_ "SystemSignalLongSymbol" SG_ 999 DPB_a055_unsupportedSeriesHWDete "DPB_a055_unsupportedSeriesHWDetected";
BA_ "SystemSignalLongSymbol" SG_ 999 DPB_a085_infoFailureWrongCUBASHa "DPB_a085_infoFailureWrongCUBASHandlingDetected";
BA_ "SystemSignalLongSymbol" SG_ 999 DPB_a086_diagHydProtectionPressF "DPB_a086_diagHydProtectionPressFault";
BA_ "SystemSignalLongSymbol" SG_ 999 DPB_a087_diagHydProtectionVlvFau "DPB_a087_diagHydProtectionVlvFault";
BA_ "SystemSignalLongSymbol" SG_ 999 DPB_a111_hydraulicHardUndervolta "DPB_a111_hydraulicHardUndervoltage";
BA_ "SystemSignalLongSymbol" SG_ 999 DPB_a127_hydraulicAsicShortCircu "DPB_a127_hydraulicAsicShortCircuit";
BA_ "SystemSignalLongSymbol" SG_ 999 DPB_a129_AsicTrimmingNotComplete "DPB_a129_AsicTrimmingNotCompleted";
BA_ "SystemSignalLongSymbol" SG_ 999 DPB_a131_ASICOvercurrentOnGPIO25 "DPB_a131_ASICOvercurrentOnGPIO250_1";
BA_ "SystemSignalLongSymbol" SG_ 999 DPB_a132_ASICOvercurrentOnGPIO25 "DPB_a132_ASICOvercurrentOnGPIO250_2";
BA_ "SystemSignalLongSymbol" SG_ 999 DPB_a133_ASICOvercurrentOnGPIO50 "DPB_a133_ASICOvercurrentOnGPIO50_1";
BA_ "SystemSignalLongSymbol" SG_ 999 DPB_a134_ASICOvercurrentOnGPIO50 "DPB_a134_ASICOvercurrentOnGPIO50_2";
BA_ "SystemSignalLongSymbol" SG_ 999 DPB_a135_ASICOvercurrentOnGPIO50 "DPB_a135_ASICOvercurrentOnGPIO50_3";
BA_ "SystemSignalLongSymbol" SG_ 999 DPB_a136_ASICOvercurrentOnGPIO50 "DPB_a136_ASICOvercurrentOnGPIO50_4";
BA_ "SystemSignalLongSymbol" SG_ 999 DPB_a139_DIchassisControlChecksu "DPB_a139_DIchassisControlChecksum";
BA_ "SystemSignalLongSymbol" SG_ 999 DPB_a191_VCLEFTepbmStatusChecksu "DPB_a191_VCLEFTepbmStatusChecksum";
BA_ "SystemSignalLongSymbol" SG_ 999 DPB_a194_VCRIGHTepbmStatusCounte "DPB_a194_VCRIGHTepbmStatusCounter";
BA_ "SystemSignalLongSymbol" SG_ 999 DPB_a195_VCRIGHTepbmStatusChecks "DPB_a195_VCRIGHTepbmStatusChecksum";
BA_ "SystemSignalLongSymbol" SG_ 999 DPB_a197_VCRIGHTepbmStatusTimeou "DPB_a197_VCRIGHTepbmStatusTimeout";
BA_ "SystemSignalLongSymbol" SG_ 999 DPB_a200_ESPRunoutSupportNotAvai "DPB_a200_ESPRunoutSupportNotAvailable";
BA_ "SystemSignalLongSymbol" SG_ 999 DPB_a202_vehicleStandstillQFault "DPB_a202_vehicleStandstillQFaulty";
BA_ "SystemSignalLongSymbol" SG_ 999 DPB_a220_excessiveBoostWakeupsDe "DPB_a220_excessiveBoostWakeupsDetected";
BA_ "SystemSignalLongSymbol" SG_ 999 DPB_a222_excessiveEcuResetsDetec "DPB_a222_excessiveEcuResetsDetected";
BA_ "SystemSignalLongSymbol" SG_ 999 DPB_a242_uCSafetyNotificationGRA "DPB_a242_uCSafetyNotificationGRAM";
BA_ "SystemSignalLongSymbol" SG_ 999 DPB_a256_valveRelayActuationFaul "DPB_a256_valveRelayActuationFault";
BA_ "SystemSignalLongSymbol" SG_ 999 DPB_a259_valveRelayTestUndervolt "DPB_a259_valveRelayTestUndervoltage";
BA_ "SystemSignalLongSymbol" SG_ 999 DPB_a260_valveRelaySafetySwitchF "DPB_a260_valveRelaySafetySwitchFault";
BA_ "SystemSignalLongSymbol" SG_ 999 DPB_a292_CBDS_fillBufferThreshol "DPB_a292_CBDS_fillBufferThreshold";
BA_ "SystemSignalLongSymbol" SG_ 999 DPB_a298_runningPlungerCircuitTe "DPB_a298_runningPlungerCircuitTest";
BA_ "SystemSignalLongSymbol" SG_ 999 DPB_a303_actuatingDIFullTorqueCm "DPB_a303_actuatingDIFullTorqueCmd";
BA_ "SystemSignalLongSymbol" SG_ 999 DPB_a305_DIbrakeTorqueCommandAnd "DPB_a305_DIbrakeTorqueCommandAndFlagMismatch";
BA_ "SystemSignalLongSymbol" SG_ 999 DPB_a306_actuatorFallbackBasicMa "DPB_a306_actuatorFallbackBasicMap";
BA_ "SystemSignalLongSymbol" SG_ 999 DPB_a312_continuouslyActivatedVa "DPB_a312_continuouslyActivatedValvesOff";
BA_ "SystemSignalLongSymbol" SG_ 999 DPB_a313_qualifiedBrakeEventDete "DPB_a313_qualifiedBrakeEventDetected";
BA_ "SystemSignalLongSymbol" SG_ 999 DPB_a314_runningCyclicVolumeChec "DPB_a314_runningCyclicVolumeCheck";
BA_ "SystemSignalLongSymbol" SG_ 999 DPB_a315_runningLeakageAndAirMon "DPB_a315_runningLeakageAndAirMonitoring";
BA_ "SystemSignalLongSymbol" SG_ 999 DPB_a316_lowBrakeFluidDetectedOn "DPB_a316_lowBrakeFluidDetectedOnHillSlope";
BA_ "SystemSignalLongSymbol" SG_ 999 DPB_a317_DASredundantBrakingCont "DPB_a317_DASredundantBrakingControlPartyChecksum";
BA_ "SystemSignalLongSymbol" SG_ 999 DPB_a318_DASredundantBrakingCont "DPB_a318_DASredundantBrakingControlPartyCounter";
BA_ "SystemSignalLongSymbol" SG_ 999 DPB_a319_DASredundantBrakingCont "DPB_a319_DASredundantBrakingControlPartyDLC";
BA_ "SystemSignalLongSymbol" SG_ 999 DPB_a320_DASredundantBrakingCont "DPB_a320_DASredundantBrakingControlPartyTimeout";
BA_ "SystemSignalLongSymbol" SG_ 999 DPB_a321_DASredundantBrakingCont "DPB_a321_DASredundantBrakingControlChassisChecksum";
BA_ "SystemSignalLongSymbol" SG_ 999 DPB_a322_DASredundantBrakingCont "DPB_a322_DASredundantBrakingControlChassisCounter";
BA_ "SystemSignalLongSymbol" SG_ 999 DPB_a323_DASredundantBrakingCont "DPB_a323_DASredundantBrakingControlChassisDLC";
BA_ "SystemSignalLongSymbol" SG_ 999 DPB_a324_DASredundantBrakingCont "DPB_a324_DASredundantBrakingControlChassisTimeout";
BA_ "Confidence" SG_ 1592 EPAS3P_udsResponseDataCH 1;
BA_ "Confidence" SG_ 1427 EPASTP_alertID 1;
BA_ "Confidence" SG_ 1427 EPASTP_alertState 1;
BA_ "Confidence" SG_ 1427 EPASTP_a264_degradedECU 1;
BA_ "Confidence" SG_ 1427 EPASTP_a264_vehicleSpeed 1;
BA_ "Confidence" SG_ 1427 EPASTP_a264_powerRatio 1;
BA_ "Confidence" SG_ 1427 EPASTP_a264_ownSideDegradationRe 1;
BA_ "SystemSignalLongSymbol" SG_ 1427 EPASTP_a264_ownSideDegradationRe "EPASTP_a264_ownSideDegradationReason";
BA_ "Confidence" SG_ 1427 EPASTP_a264_otherSideDegradation 1;
BA_ "SystemSignalLongSymbol" SG_ 1427 EPASTP_a264_otherSideDegradation "EPASTP_a264_otherSideDegradationReason";
BA_ "Confidence" SG_ 1427 EPASTP_a265_degradedECU 1;
BA_ "Confidence" SG_ 1427 EPASTP_a265_vehicleSpeed 1;
BA_ "Confidence" SG_ 1427 EPASTP_a265_rawMcuTemperature 1;
BA_ "Confidence" SG_ 1427 EPASTP_a265_degradedCurrentLimit 1;
BA_ "Confidence" SG_ 1427 EPASTP_a266_cdpAssistFactor 1;
BA_ "Confidence" SG_ 1427 EPASTP_a266_vehicleSpeed 1;
BA_ "Confidence" SG_ 1427 EPASTP_a267_vehicleSpeed 1;
BA_ "Confidence" SG_ 1427 EPASTP_a267_velocityEstimatorSta 1;
BA_ "SystemSignalLongSymbol" SG_ 1427 EPASTP_a267_velocityEstimatorSta "EPASTP_a267_velocityEstimatorState";
BA_ "Confidence" SG_ 1427 EPASTP_a269_vehicleSpeed 1;
VAL_ 943 BB_sOutputRodQF 2 "Faulty" 1 "Normal" 0 "NotInit_orOff" ;
VAL_ 943 BB_sInputRodQF 2 "Faulty" 1 "Normal" 0 "NotInit_orOff" ;
VAL_ 943 BB_driverBrakeApply 1 "DRIVER_APPLYING_BRAKES" 0 "BRAKES_NOT_APPLIED" ;
VAL_ 943 BB_driverBrakeApplyQF 2 "Faulty" 1 "Normal" 0 "NotInit_orOff" ;
VAL_ 943 BB_boosterStatus 6 "ACTUATION" 5 "READY" 4 "ACTIVE_GOOD_CHECK" 3 "DIAGNOSTIC" 2 "FAILURE" 1 "INIT" 0 "OFF" ;
VAL_ 943 BB_warningLampRequest 2 "RED_BRAKE_LAMP_REQUEST" 1 "YELLOW_BRAKE_LAMP_REQUEST" 0 "NO_LAMP_REQUEST" ;
VAL_ 943 BB_brakeFluidLevel 3 "BRAKE_FLUID_LEVEL_INVALID" 2 "BRAKE_FLUID_LEVEL_NORMAL" 1 "BRAKE_FLUID_LEVEL_LOW" 0 "BRAKE_FLUID_LEVEL_UNKNOWN" ;
VAL_ 943 BB_internalState 7 "READY_TO_SHUTDOWN" 6 "POST_DRIVE_CHECK" 5 "TRANSITION_TO_IDLE" 4 "DIAGNOSTIC" 3 "EXTERNAL_BRAKE_REQUEST" 2 "LOCAL_BRAKE_REQUEST" 1 "PRE_DRIVE_CHECK" 0 "NO_MODE_ACTIVE" ;
VAL_ 943 BB_unfilteredFluidLevelLow 1 "LEVEL_LOW" 0 "LEVEL_NORMAL_OR_UNKNOWN_OR_INVALID" ;
VAL_ 778 DAS_objectId 5 "VEHICLE_HEADINGS" 4 "ROAD_SIGN" 3 "CUTIN_VEHICLE" 2 "RIGHT_VEHICLES" 1 "LEFT_VEHICLES" 0 "LEAD_VEHICLES" ;
VAL_ 778 DAS_leadVehType 6 "IPSO" 5 "PEDESTRIAN" 4 "BICYCLE" 3 "MOTORCYCLE" 2 "CAR" 1 "TRUCK" 0 "UNKNOWN" ;
VAL_ 778 DAS_leadVehDx 255 "SNA" ;
VAL_ 778 DAS_leadVehVxRel 15 "SNA" ;
VAL_ 778 DAS_leadVehId 127 "SNA" ;
VAL_ 778 DAS_leadVeh2Type 5 "PEDESTRIAN" 4 "BICYCLE" 3 "MOTORCYCLE" 2 "CAR" 1 "TRUCK" 0 "UNKNOWN" ;
VAL_ 778 DAS_leadVeh2Dx 255 "SNA" ;
VAL_ 778 DAS_leadVeh2VxRel 15 "SNA" ;
VAL_ 778 DAS_leadVeh2Id 0 "SNA" ;
VAL_ 778 DAS_leftVehType 5 "PEDESTRIAN" 4 "BICYCLE" 3 "MOTORCYCLE" 2 "CAR" 1 "TRUCK" 0 "UNKNOWN" ;
VAL_ 778 DAS_leftVehDx 255 "SNA" ;
VAL_ 778 DAS_leftVehVxRel 15 "SNA" ;
VAL_ 778 DAS_leftVehId 127 "SNA" ;
VAL_ 778 DAS_leftVeh2Type 5 "PEDESTRIAN" 4 "BICYCLE" 3 "MOTORCYCLE" 2 "CAR" 1 "TRUCK" 0 "UNKNOWN" ;
VAL_ 778 DAS_leftVeh2Dx 255 "SNA" ;
VAL_ 778 DAS_leftVeh2VxRel 15 "SNA" ;
VAL_ 778 DAS_leftVeh2Id 0 "SNA" ;
VAL_ 778 DAS_rightVehType 5 "PEDESTRIAN" 4 "BICYCLE" 3 "MOTORCYCLE" 2 "CAR" 1 "TRUCK" 0 "UNKNOWN" ;
VAL_ 778 DAS_rightVehDx 255 "SNA" ;
VAL_ 778 DAS_rightVehVxRel 15 "SNA" ;
VAL_ 778 DAS_rightVehId 127 "SNA" ;
VAL_ 778 DAS_rightVeh2Type 5 "PEDESTRIAN" 4 "BICYCLE" 3 "MOTORCYCLE" 2 "CAR" 1 "TRUCK" 0 "UNKNOWN" ;
VAL_ 778 DAS_rightVeh2Dx 255 "SNA" ;
VAL_ 778 DAS_rightVeh2VxRel 15 "SNA" ;
VAL_ 778 DAS_rightVeh2Id 0 "SNA" ;
VAL_ 778 DAS_cutinVehType 5 "PEDESTRIAN" 4 "BICYCLE" 3 "MOTORCYCLE" 2 "CAR" 1 "TRUCK" 0 "UNKNOWN" ;
VAL_ 778 DAS_cutinVehDx 255 "SNA" ;
VAL_ 778 DAS_cutinVehVxRel 15 "SNA" ;
VAL_ 778 DAS_cutinVehId 127 "SNA" ;
VAL_ 778 DAS_roadSignColor 4 "RED_YELLOW" 3 "GREEN" 2 "YELLOW" 1 "RED" 0 "NONE" ;
VAL_ 778 DAS_roadSignId 255 "SNA" 1 "TRAFFIC_LIGHT" 0 "STOP_SIGN" ;
VAL_ 778 DAS_roadSignStopLineDist 1023 "SNA" ;
VAL_ 778 DAS_roadSignSource 2 "VISION" 1 "NAV" 0 "NONE" ;
VAL_ 778 DAS_roadSignArrow 4 "UNKNOWN" 3 "STRAIGHT" 2 "RIGHT" 1 "LEFT" 0 "CIRCLE" ;
VAL_ 778 DAS_roadSignOrientation 2 "HORIZONTAL_3_LIGHT" 1 "VERTICAL_3_LIGHT" 0 "UNKNOWN" ;
VAL_ 781 DAS_positioningEngineStatusMulti 3 "Mux3" 2 "Mux2" 1 "Mux1" 0 "Mux0" ;
VAL_ 781 DAS_meoSolverNumRuns 3 "101_AND_ABOVE" 2 "11_TO_100" 1 "1_TO_10" 0 "0" ;
VAL_ 781 DAS_meoSolverReportTerminationTy 4 "USER_SUCCESS" 3 "USER_FAILURE" 2 "NO_CONVERGENCE" 1 "FAILURE" 0 "CONVERGENCE" ;
VAL_ 781 DAS_meoSolverReportTotalTimeS 6 "0_5_AND_ABOVE" 5 "0_4_TO_0_5" 4 "0_3_TO_0_4" 3 "0_2_TO_0_3" 2 "0_1_TO_0_2" 1 "0_TO_0_1" 0 "0" ;
VAL_ 781 DAS_meoHeadingValid 1 "TRUE" 0 "FALSE" ;
VAL_ 781 DAS_meoGpsQualityLevel 6 "GPS_QUALITY_SUB_LANE" 5 "GPS_QUALITY_LANE" 4 "GPS_QUALITY_ROAD" 3 "GPS_QUALITY_POOR" 2 "GPS_QUALITY_UNKNOWN" 1 "GPS_OUTPUT_UNAVAILABLE" 0 "GPS_NO_COMMUNICATION" ;
VAL_ 781 DAS_meoFixType 5 "TIME_ONLY_FIX" 4 "GNSS_DEAD_RECKONING_COMBINED" 3 "FIX_3D" 2 "FIX_2D" 1 "DEAD_RECKONING_ONLY" 0 "NO_FIX" ;
VAL_ 781 DAS_lastMeoResetReason 3 "EXTRAPOLATION_DEVIATES_FROM_SPP" 2 "SLAM_ANCHOR_NODE_OUT_OF_ORDER" 1 "INITIALIZE_STATE_FROM_CONTEXT_FAILED" 0 "UNKNOWN" ;
VAL_ 781 DAS_vioMultiGpsSelectedSource 5 "SEEDED_ORIGIN" 4 "RELOCALIZATION" 3 "BLUEFIN_SPP_TDCP" 2 "BLUEFIN_MEO" 1 "RAW_GPS" 0 "INVALID" ;
VAL_ 781 DAS_vioMultiGpsPeCooldownActive 1 "TRUE" 0 "FALSE" ;
VAL_ 781 DAS_vioMultiGpsPeSppTdcpConsiste 1 "TRUE" 0 "FALSE" ;
VAL_ 781 DAS_vioMultiGpsPeMeoConsistentWi 1 "TRUE" 0 "FALSE" ;
VAL_ 781 DAS_publishedGpsSource 3 "VIO_MULTI_GPS" 2 "VIO_GEODETIC_POSE" 1 "RAW_GPS_PASSTHROUGH" 0 "INVALID" ;
VAL_ 781 DAS_bluefinEnabled 1 "TRUE" 0 "FALSE" ;
VAL_ 781 DAS_orioleDisabled 1 "TRUE" 0 "FALSE" ;
VAL_ 781 DAS_disableMonarch 1 "TRUE" 0 "FALSE" ;
VAL_ 1548 DAS_TR_ObjIndex 31 "Mux31" 30 "Mux30" 29 "Mux29" 28 "Mux28" 27 "Mux27" 26 "Mux26" 25 "Mux25" 24 "Mux24" 23 "Mux23" 22 "Mux22" 21 "Mux21" 20 "Mux20" 19 "Mux19" 18 "Mux18" 17 "Mux17" 16 "Mux16" 15 "Mux15" 14 "Mux14" 13 "Mux13" 12 "Mux12" 11 "Mux11" 10 "Mux10" 9 "Mux9" 8 "Mux8" 7 "Mux7" 6 "Mux6" 5 "Mux5" 4 "Mux4" 3 "Mux3" 2 "Mux2" 1 "Mux1" 0 "Mux0" ;
VAL_ 1548 DAS_TR_Obj00_Class 4 "RADAR_CLASS_CONSTRUCTION_ELEMENT" 3 "RADAR_CLASS_MOVING_PEDESTRIAN" 2 "RADAR_CLASS_MOVING_TWO_WHEEL_VEHICLE" 1 "RADAR_CLASS_MOVING_FOUR_WHEEL_VEHICLE" 0 "RADAR_CLASS_UNKNOWN" ;
VAL_ 1548 DAS_TR_Obj00_MovingState 3 "RADAR_MOVESTATE_STANDING" 2 "RADAR_MOVESTATE_STOPPED" 1 "RADAR_MOVESTATE_MOVING" 0 "RADAR_MOVESTATE_INDETERMINATE" ;
VAL_ 1237 DPB_alertID 337 "a337_EMCMain21Timeout" 336 "a336_EMCMain21DLC" 335 "a335_EMCMain21Counter" 334 "a334_EMCMain21Checksum" 333 "a333_EMCMain11Timeout" 332 "a332_EMCMain11DLC" 331 "a331_EMCMain11Counter" 330 "a330_EMCMain11Checksum" 329 "a329_standaloneEBRActive" 328 "a328_DIlocStatus2Timeout" 327 "a327_DIlocStatus2DLC" 326 "a326_DIlocStatus2Counter" 325 "a325_DIlocStatus2Checksum" 324 "a324_DASredundantBrakingControlChassisTimeout" 323 "a323_DASredundantBrakingControlChassisDLC" 322 "a322_DASredundantBrakingControlChassisCounter" 321 "a321_DASredundantBrakingControlChassisChecksum" 320 "a320_DASredundantBrakingControlPartyTimeout" 319 "a319_DASredundantBrakingControlPartyDLC" 318 "a318_DASredundantBrakingControlPartyCounter" 317 "a317_DASredundantBrakingControlPartyChecksum" 316 "a316_lowBrakeFluidDetectedOnHillSlope" 315 "a315_runningLeakageAndAirMonitoring" 314 "a314_runningCyclicVolumeCheck" 313 "a313_qualifiedBrakeEventDetected" 312 "a312_continuouslyActivatedValvesOff" 311 "a311_postrunDurationTooLong" 310 "a310_DIRAxleTorqueInvalid" 309 "a309_DIFAxleTorqueInvalid" 308 "a308_backupMode" 307 "a307_actuatorDegradedMap" 306 "a306_actuatorFallbackBasicMap" 305 "a305_DIbrakeTorqueCommandAndFlagMismatch" 304 "a304_actuatingDITorqueCmd" 303 "a303_actuatingDIFullTorqueCmd" 302 "a302_PM_locStateTimeout" 301 "a301_PM_locStateDLC" 300 "a300_PM_locStateChecksum" 299 "a299_PM_locStateCounter" 298 "a298_runningPlungerCircuitTest" 297 "a297_undefinedAlertDetected" 296 "a296_StatInvalid_DI_FullSNA" 295 "a295_hbaTrackModeActive" 294 "a294_hbaNormalModeActive" 293 "a293_CBDS_fmeInternalEvent" 292 "a292_CBDS_fillBufferThreshold" 291 "a291_extDBRRequestTooLow" 290 "a290_securityInfo" 289 "a289_evacFillNotComplete" 288 "a288_PlantDegradedSW" 287 "a287_brakeCmdStateInvalid" 286 "a286_ebrCmdStateInvalid" 285 "a285_DIbrakeCommandTimeout" 284 "a284_DIbrakeCommandDLC" 283 "a283_DIbrakeCommandChecksum" 282 "a282_DIbrakeCommandCounter" 281 "a281_brakeFluidOORHigh" 280 "a280_LowBrakeFluid" 279 "a279_VCFRONTsensorsTimeout" 278 "a278_VCFRONTsensorsDLC" 277 "a277_VCFRONTsensorsChecksum" 276 "a276_VCFRONTsensorsCounter" 275 "a275_Ps1Ps2PlausibilityFault" 274 "a274_AswSystemTimeOut" 273 "a273_SMMOneRequestsInit" 272 "a272_runtimeAssertionFault" 271 "a271_RPSWrongCalibData" 270 "a270_RPSVectorRangeLow" 269 "a269_RPSVectorRangeHigh" 268 "a268_RPSVectorOscillating" 267 "a267_RpsAngleImplausible" 266 "a266_RPSNvMReadFault" 265 "a265_WdhTaskMonConCnt" 264 "a264_WdhSwBistConCnt" 263 "a263_WdhAsicWdErrorCntStuck" 262 "a262_WdhAsicWdErrorCntLimit" 261 "a261_WdhAsicWdCmdMissing" 260 "a260_valveRelaySafetySwitchFault" 259 "a259_valveRelayTestUndervoltage" 258 "a258_valveRelayOffContinuous" 257 "a257_valveRelayOnContinuous" 256 "a256_valveRelayActuationFault" 255 "a255_valveRelayShort" 254 "a254_valveMV9Fault" 253 "a253_valveMV82Fault" 252 "a252_valveMV81Fault" 251 "a251_valveMV8Fault" 250 "a250_valveMV7Fault" 249 "a249_valveMV62Fault" 248 "a248_valveMV61Fault" 247 "a247_valveMV6Fault" 246 "a246_valveMV5Fault" 245 "a245_valveMV0Fault" 244 "a244_valvesGenericFault" 243 "a243_microSupplyError" 242 "a242_uCSafetyNotificationGRAM" 241 "a241_uCSafetyNotification" 240 "a240_microSafetyLogicFault" 239 "a239_microSafetyFault" 238 "a238_microRegisterFault" 237 "a237_uCVoltageDividerDrift" 236 "a236_UB6SupplyPathFault" 235 "a235_UB6PlausiMonFault" 234 "a234_systemTaskOverRun" 233 "a233_systemTaskJitter" 232 "a232_systemErrorHook" 231 "a231_stackOverUnderFlow" 230 "a230_OSErrorHook" 229 "a229_IREFOutOfRange" 228 "a228_supplyASICInitFault" 227 "a227_brakeFluidLoss" 226 "a226_U5VTestFault" 225 "a225_U5VOutOfRange" 224 "a224_brakeBoostLost" 223 "a223_RAMFault" 222 "a222_excessiveEcuResetsDetected" 221 "a221_notShutdownRight" 220 "a220_excessiveBoostWakeupsDetected" 219 "a219_pressureSensor2Fault" 218 "a218_pressureSensor2Temp" 217 "a217_pressureSensor2Fault" 216 "a216_pressureSensor2Low" 215 "a215_pressureSensor2High" 214 "a214_pressureSensor2Short" 213 "a213_pressureSensor1Fault" 212 "a212_pressureSensor1Temp" 211 "a211_pressureSensor1Fault" 210 "a210_pressureSensor1Low" 209 "a209_pressureSensor1High" 208 "a208_pressureSensor1Short" 207 "a207_hydraulicOvervoltage" 206 "a206_OSTaskSchemeError" 205 "a205_NvMWriteCycleExceed" 204 "a204_CANUndervoltage" 203 "a203_ABSNotAvailable" 202 "a202_vehicleStandstillQFaulty" 201 "a201_vehicleSpeedQFaulty" 200 "a200_ESPRunoutSupportNotAvailable" 199 "a199_pMC1QFaulty" 198 "a198_CANOvervoltage" 197 "a197_VCRIGHTepbmStatusTimeout" 196 "a196_VCRIGHTepbmStatusDLC" 195 "a195_VCRIGHTepbmStatusChecksum" 194 "a194_VCRIGHTepbmStatusCounter" 193 "a193_VCLEFTepbmStatusTimeout" 192 "a192_VCLEFTepbmStatusDLC" 191 "a191_VCLEFTepbmStatusChecksum" 190 "a190_VCLEFTepbmStatusCounter" 189 "a189_LVPowerStateCounter" 188 "a188_LVPowerStateDLC" 187 "a187_LVPowerStateChecksum" 186 "a186_LVPowerStateTimeout" 185 "a185_RCMInertial2Timeout" 184 "a184_RCMInertial2DLC" 183 "a183_RCMInertial2Checksum" 182 "a182_RCMInertial2Counter" 181 "a181_PMstate2Timeout" 180 "a180_PMstate2DLC" 179 "a179_PMstate2Checksum" 178 "a178_PMstate2Counter" 177 "a177_ESP_modulator3Timeout" 176 "a176_ESP_modulator3DLC" 175 "a175_ESP_modulator3Checksum" 174 "a174_ESP_modulator3Counter" 173 "a173_ESP_modulator2Timeout" 172 "a172_ESP_modulator2DLC" 171 "a171_ESP_modulator2Checksum" 170 "a170_ESP_modulator2Counter" 169 "a169_ESP_chassis3Timeout" 168 "a168_ESP_chassis3DLC" 167 "a167_ESP_chassis3Checksum" 166 "a166_ESP_chassis3Counter" 165 "a165_ESP_modulator1Timeout" 164 "a164_ESP_modulator1DLC" 163 "a163_ESP_modulator1Checksum" 162 "a162_ESP_modulator1Counter" 161 "a161_EPBRstatusTimeout" 160 "a160_EPBRstatusDLC" 159 "a159_EPBRstatusChecksum" 158 "a158_EPBRstatusCounter" 157 "a157_EPBLstatusTimeout" 156 "a156_EPBLstatusDLC" 155 "a155_EPBLstatusChecksum" 154 "a154_EPBLstatusCounter" 153 "a153_DIRtorqueTimeout" 152 "a152_DIRtorqueDLC" 151 "a151_DIRtorqueChecksum" 150 "a150_DIRtorqueCounter" 149 "a149_DIFtorqueTimeout" 148 "a148_DIFtorqueDLC" 147 "a147_DIFtorqueChecksum" 146 "a146_DIFtorqueCounter" 145 "a145_DIsystemStatusTimeout" 144 "a144_DIsystemStatusDLC" 143 "a143_DIsystemStatusChecksum" 142 "a142_DIsystemStatusCounter" 141 "a141_DIchassisControlTimeout" 140 "a140_DIchassisControlDLC" 139 "a139_DIchassisControlChecksum" 138 "a138_DIchassisControlCounter" 137 "a137_ASICOvercurrentOnWRHS" 136 "a136_ASICOvercurrentOnGPIO50_4" 135 "a135_ASICOvercurrentOnGPIO50_3" 134 "a134_ASICOvercurrentOnGPIO50_2" 133 "a133_ASICOvercurrentOnGPIO50_1" 132 "a132_ASICOvercurrentOnGPIO250_2" 131 "a131_ASICOvercurrentOnGPIO250_1" 130 "a130_AsicMalfunctionDetected" 129 "a129_AsicTrimmingNotCompleted" 128 "a128_micSpiTransferError" 127 "a127_hydraulicAsicShortCircuit" 126 "a126_MICB6TransferError" 125 "a125_B6AsicFault" 124 "a124_asicOscillatorError" 123 "a123_micAsicInitTestError" 122 "a122_micAsicClkInError" 121 "a121_LiPSOutOfRangeLow" 120 "a120_LiPSOutOfRangeHigh" 119 "a119_LiPS2PwmTransmission" 118 "a118_LiPS2PwmLineLow" 117 "a117_LiPS2PwmLineHigh" 116 "a116_LiPS1SentTransmission" 115 "a115_LiPS1SentSensor" 114 "a114_LiPS1SentLineLow" 113 "a113_LiPS1SentLineHigh" 112 "a112_hydraulicUndervoltage" 111 "a111_hydraulicHardUndervoltage" 110 "a110_HWBISTError" 109 "a109_GTMTbuMonError" 108 "a108_GTMRefFrequencyError" 107 "a107_vrOnFails" 106 "a106_ecuBistCmdTestFault" 105 "a105_ecuWdSContinuousError" 104 "a104_ecuWdStartuptestFault" 103 "a103_ecuVrViaSpiFails" 102 "a102_ecuVrOnWhileWdTimeout" 101 "a101_ecuFastWdTestFault" 100 "a100_ecuErrpinCounterFault" 99 "a099_ecuEnContinuousError" 98 "a098_ecuEnableHyLowFault" 97 "a097_ecuEnableHyHighFault" 96 "a096_ecuEnableElLowFault" 95 "a095_ecuEnableElHighFault" 94 "a094_ecuClockTestFault" 93 "a093_ecuBistFaultCtrFault" 92 "a092_decoupleBitTestFault" 91 "a091_MRGPathTestFault" 90 "a090_flashFault" 89 "a089_ecuBandgap" 88 "a088_DMATransferError" 87 "a087_diagHydProtectionVlvFault" 86 "a086_diagHydProtectionPressFault" 85 "a085_infoFailureWrongCUBASHandlingDetected" 84 "a084_RBCPUException" 83 "a083_chargePumpUndervoltage" 82 "a082_chargePumpFault" 81 "a081_tempSensImplausVoltage" 80 "a080_tempSens2ShortToGround" 79 "a079_tempSens2ShortToSupply" 78 "a078_tempSens1ShortToGround" 77 "a077_tempSens1ShortToSupply" 76 "a076_rotorSinOutOfRangeLow" 75 "a075_rotorSinOutOfRangeHigh" 74 "a074_rotorCosOutOfRangeLow" 73 "a073_rotorCosOutOfRangeHigh" 72 "a072_OBDCurrent2OORLow" 71 "a071_OBDCurrent2OORHigh" 70 "a070_OBDCurrent1OORLow" 69 "a069_OBDCurrent1OORHigh" 68 "a068_BLMMuxerTimeoutError" 67 "a067_current2OffsetLow" 66 "a066_current2OffsetHigh" 65 "a065_current1OffsetLow" 64 "a064_current1OffsetHigh" 63 "a063_motorConfigMismatch" 62 "a062_loadDumpOnFSLTest" 61 "a061_bridgeSwitchInitError" 60 "a060_motorBridgeDriverFault" 59 "a059_factoryModeActive" 58 "a058_AdcSelftestC5P" 57 "a057_AdcPinTest" 56 "a056_AdcPeripheralFault" 55 "a055_unsupportedSeriesHWDetected" 54 "a054_unsupportedHW" 53 "a053_hydraulicAssemblyModeActive" 52 "a052_PSIDTimeOut" 51 "a051_PSCVoltageImplausible" 50 "a050_supplyUndervoltageLvl3" 49 "a049_supplyUndervoltageLvl2" 48 "a048_supplyUndervoltageLvl1" 47 "a047_pPlungerPlausCheckFailure" 46 "a046_supplyOvervoltageLvl3" 45 "a045_supplyOvervoltageLvl2" 44 "a044_supplyOvervoltageLvl1" 43 "a043_PSCMotorSizeReadFault" 42 "a042_motorLoadPressImplausible" 41 "a041_PSCGearRatioReadFault" 40 "a040_plungerCircuitPressLowGoodCheck" 39 "a039_plungerCircuitPressLow" 38 "a038_plungerCircuitPressHighGoodCheck" 37 "a037_plungerCircuitPressHigh" 36 "a036_lossOfPDUInstanceDetected" 35 "a035_PDURouterinitializationFailed" 34 "a034_lipsMemoryEmpty" 33 "a033_motorDynamicLimited" 32 "a032_HWParamWriteFailed" 31 "a031_HWParamReadFailed" 30 "a030_notShutDownRight" 29 "a029_motorTestFault" 28 "a028_motorTempHighLevel2" 27 "a027_motorTempHighLevel1" 26 "a026_LiPSIDTimeout" 25 "a025_backupCircuitLeakage" 24 "a024_ESPLDMFailure" 23 "a023_initialPlungerCheckFailed" 22 "a022_brakeSystemOverheatLvl2" 21 "a021_brakeSystemOverheatLvl1" 20 "a020_ecuHuMismatch" 19 "a019_DETReportError" 18 "a018_largeLeakageDetectedGoodCheck" 17 "a017_largeLeakageDetected" 16 "a016_CAN2BusOff" 15 "a015_CAN1BusOff" 14 "a014_CANControllerHWFault" 13 "a013_softPedalChar" 12 "a012_PtsNonZeroStage2" 11 "a011_PtsNonZeroStage1" 10 "a010_LiPSPtsConsistency" 9 "a009_LiPSPts2Offset" 8 "a008_LiPSPts1Offset" 7 "a007_PMCLeakageDetected" 6 "a006_hardPedalCharGoodCheck" 5 "a005_hardPedalChar" 4 "a004_assertionFault" 3 "a003_AswEEPROMReadFailure" 2 "a002_pMC2SensorOffsetHigh" 1 "a001_pPlungerSensorOffsetHigh" 0 "ALERT_DO_NOT_USE_ZERO" ;
VAL_ 1237 DPB_alertState 1 "SET" 0 "CLEARED" ;
VAL_ 999 DPB_matrixIndex 5 "AlertMatrix5" 4 "AlertMatrix4" 3 "AlertMatrix3" 2 "AlertMatrix2" 1 "AlertMatrix1" 0 "AlertMatrix0" ;
VAL_ 1427 EPASTP_alertID 270 "a270_oscillationCompTrqLimReached" 269 "a269_assistTorqueDisabled" 268 "a268_eacCancelled" 267 "a267_safeSpeedAssist" 266 "a266_overloadProtect" 265 "a265_overheatProtect" 264 "a264_assistTorqueLimited" 263 "a263_espWsStatus" 262 "a262_yawRateStatus" 261 "a261_sccmStatusError" 260 "a260_scoPrivateBusOff" 259 "a259_scoCanBusOff" 258 "a258_pspInvalidProjectParamset" 257 "a257_dcvmUnderVolt" 256 "a256_dcvmOverVolt" 255 "a255_pmState2Mia" 254 "a254_vcFrontMia" 253 "a253_vcFrontCsError" 252 "a252_vcFrontCntError" 251 "a251_uiTuneReqMia" 250 "a250_uiTuneReqCsError" 249 "a249_uiTuneReqCntError" 248 "a248_sccmMia" 247 "a247_sccmCsError" 246 "a246_sccmCntError" 245 "a245_rcmMia" 244 "a244_rcmCsError" 243 "a243_rcmCntError" 242 "a242_gtwConfigMia" 241 "a241_espWsMia" 240 "a240_espWsCsError" 239 "a239_espWsCntError" 238 "a238_espWrMia" 237 "a237_espWrCsError" 236 "a236_espWrCntError" 235 "a235_ecu2StatMia" 234 "a234_ecu2StatCsError" 233 "a233_ecu2StatCntError" 232 "a232_diSpdMia" 231 "a231_diSpdCsError" 230 "a230_diSpdCntError" 229 "a229_dirTorqueMia" 228 "a228_dirTorqueCsError" 227 "a227_dirTorqueCntError" 226 "a226_dasMia" 225 "a225_dasCsError" 224 "a224_dasCntError" 223 "a223_apsMia" 222 "a222_apsCsError" 221 "a221_apsCntError" 219 "a219_frhFastRestartFailed" 218 "a218_aadApplicationStateErr" 217 "a217_msdMasterSilentErr" 216 "a216_isdgImproperShutdown" 215 "a215_vsgSafeViolErr" 214 "a214_velInterfaceErr" 213 "a213_frmHighFrictionDetected" 212 "a212_frmDataLost" 211 "a211_frmInternalErr" 210 "a210_fdrTotalBlocking" 209 "a209_fdrLowSeverityFreezing" 208 "a208_fdrLowSeverityBlocking" 207 "a207_fdrOclFreezing" 206 "a206_fdrOclPartialBlocking" 205 "a205_fdrOclFail" 204 "a204_fdpPrevTrqErr" 203 "a203_ctcInterfaceErr" 202 "a202_ohnvmpStoredOffsetLost" 201 "a201_ammOutputBufferOverflow" 200 "a200_ammInputBufferOverflow" 199 "a199_osumC1StackNearFull" 198 "a198_osumC1CsaNearFull" 197 "a197_difpDifactorInvalid" 196 "a196_topEolTasOffsetInvalid" 195 "a195_imcmCommErrC1" 194 "a194_amNvdataLoss" 193 "a193_osumC0StackNearFull" 192 "a192_osumC0CsaNearFull" 191 "a191_sbcscpVcp2VucVoltFail" 190 "a190_sbchCommBufferOverflow" 189 "a189_sbchCommErrMcuToSbc" 188 "a188_epmCommBufferOverflow" 187 "a187_epmVoltFail" 186 "a186_wdhCommBufferOverflow" 185 "a185_sbcscpQAWatchdogReset" 184 "a184_sbcmCommBufferOverflow" 183 "a183_sbchCommErrSbcToMcu" 182 "a182_mcdInputMia" 181 "a181_dmDeadlineViolationC1" 180 "a180_dmDeadlineViolationC1" 179 "a179_tedMotorcoilTempChecker" 178 "a178_exchWdtException" 177 "a177_etsrInvalidated" 176 "a176_exchCpu1ExceptionReset" 175 "a175_exchFlashStoredConfigErr" 174 "a174_pmpPhasecurrentAge" 173 "a173_pmpRotorspeedAge" 172 "a172_pmpElangMotorcurrentAge" 171 "a171_pmpKgvalueAge" 170 "a170_pmpDcvoltAge" 169 "a169_scpSafetyReset" 168 "a168_c1csInvalidC1App" 167 "a167_iccd1ErrQueueOverflow" 166 "a166_tdaPhasecurrentshuntTempChecker" 165 "a165_tdaDcbusshuntTempChecker" 164 "a164_tdaBattfetjunctionTempChecker" 163 "a163_tdaPowermoduleTempChecker" 162 "a162_tdaBridgefetjunctionTempChecker" 161 "a161_tdaRelayfetjunctionTempChecker" 160 "a160_rsthCpu1UnexpectedAlarm" 159 "a159_exchFlashWordlineTransientErr" 158 "a158_amGduFailDuringRecovery" 157 "a157_mcudcpInvalidEcuId" 156 "a156_amIntSerialErrSafetyReset" 155 "a155_sdsmDataInvalidAll" 154 "a154_sdsmCsErrorInvalidPrimary" 153 "a153_sdsmBlockSelectorInvalid" 152 "a152_exchFlashEccException" 151 "a151_amPermanentEmergencyOffRequested" 150 "a150_amExternalEmergencyOffRequested" 149 "a149_amReversibleEmergencyOffRequested" 148 "a148_mrccExitFromStandbyDetected" 147 "a147_amDcLinkShortedFail" 146 "a146_btarcRcCircuitCheck" 145 "a145_mriPeripheralRaminitFailed" 144 "a144_mriCoreRaminitFailed" 143 "a143_tedEmifilterCmcTempChecker" 142 "a142_tedEmifilterDmcTempChecker" 141 "a141_amFetShortTest" 140 "a140_imcmConfigurationErr" 139 "a139_osehAdditionalOsErr" 138 "a138_osehAdditionalErrWithoutImmReset" 137 "a137_osehErrWithoutImmediateReset" 136 "a136_ftElectricalAngleQf" 135 "a135_tmpsfetjCalculationOverflowErr" 134 "a134_osehGuardedResetAfterErrWithoutReset" 133 "a133_mcusscLbistEcuIdIsNotSupported" 132 "a132_mcusscNotSupportedMcu" 131 "a131_exchGuardedResetAfterPartitionStop" 130 "a130_mrccConfigCsErrorErr" 129 "a129_exchAdditionalExceptionStopRestart" 128 "a128_exchExceptionStopRestart" 127 "a127_exchAdditionalExceptionAfterRst" 126 "a126_mcusscMonbistMiaErr" 125 "a125_mcusscMbistMiaErr" 124 "a124_mcusscMbistEccTransientErr" 123 "a123_imcmCommErr" 122 "a122_pcpBridgeFetShort" 121 "a121_mcusscMbistEccErr" 120 "a120_mcusscFlashEccLatentErr" 119 "a119_mcusscFlashEccCriticalErr" 118 "a118_mcusscFlashCsErrorErr" 117 "a117_mrccStartupRegCsErrorTransientErr" 116 "a116_mrccStartupRegCsErrorStaticErr" 115 "a115_mcusscLbistSingleFail" 114 "a114_osehOsErr" 113 "a113_rsthUncorrectableEndToEndBusErr" 112 "a112_rsthSafetyFlipflopErr" 111 "a111_amCurrentSensingDisconnection" 110 "a110_amPhaseRelaySwitchOffTest" 109 "a109_exhaSysBusOrPeriphErrException" 108 "a108_exhaInternalProtectionException" 107 "a107_exhaOtherNmiException" 106 "a106_exhaSpbBusErrException" 105 "a105_exhaSriBusErrException" 104 "a104_exhaBusMpuException" 103 "a103_exhaUnusedInterruptCallException" 102 "a102_amPhasecurrentQosErr" 101 "a101_sdrvSpcIdMismatch" 100 "a100_amVbrgLssFault" 99 "a099_mcdTorqueMismatchFault" 98 "a098_invErr" 97 "a097_rppRpsMultipleStaticFail" 96 "a096_rppRpsSingleStaticFail" 95 "a095_mdModelBasedMotorIntegrityCheck" 94 "a094_sctpTsuMultipleStaticFail" 93 "a093_sctpTsuSingleStaticFail" 92 "a092_amGduSwitchOffTestBySbc" 91 "a091_bvpBattVoltCrossChkFailed" 90 "a090_etsmWarning" 89 "a089_tedRevercebattfetjunctionTempChecker" 88 "a088_tedMainboardTempChecker" 87 "a087_rsthFlashConfigErr" 86 "a086_rsthRamUncorrEcc" 85 "a085_amGduSwitchOffTestByMcu" 84 "a084_adcTriggerCheck" 83 "a083_tdaDclinkcapacitorTempChecker" 82 "a082_adcTriggerTimeChk" 81 "a081_exchFloatingPointException" 80 "a080_pwmTimerSyncCheck" 79 "a079_gduhComErr" 78 "a078_dmDeadlineViolation" 77 "a077_dmDeadlineViolation" 76 "a076_exchGeneralException" 75 "a075_rsthUnusedOtherModuleAlarm" 74 "a074_rsthUnexpectedAlarm" 73 "a073_rsthOtherEdcEcc" 72 "a072_rsthFlashUncorrEccOrOvfl" 71 "a071_rsthInternalHighVolt" 70 "a070_rsthInternalLowVolt" 69 "a069_rsthCoreTempOutOfRangeHwCheck" 68 "a068_rsthCoreRedundancyErr" 67 "a067_tspmPowermoduleTempImplausible" 66 "a066_amVoltQfErr" 65 "a065_amGduJuncTemp" 64 "a064_amBridgeShort" 63 "a063_amIntRegulatorErr" 62 "a062_amPhaseBridgeCheck" 61 "a061_amIntSerialErr" 60 "a060_amGduFail" 59 "a059_amStartupTestFailed" 58 "a058_amIntVgsUndervtgErr" 57 "a057_amGduVds" 56 "a056_amGduConfigCsErrorCheck" 55 "a055_amExtendedGduTest" 54 "a054_adcUnexpectedData" 53 "a053_adcUnexpectedNumOfData" 52 "a052_ermSdcInputBufferOverflow" 51 "a051_ermMessageErr" 50 "a050_erlErr" 49 "a049_epmLgFail" 48 "a048_epmVcpVoltFail" 47 "a047_epmVregVoltFail" 46 "a046_mcusscOscillatorNotReliable" 45 "a045_psumSbcBandgapVoltErr" 44 "a044_sbcmSbcEepromFail" 43 "a043_sbcmWdStateDisabled" 42 "a042_wdhWdTestFail" 41 "a041_imcmCoreConfigurationMismatch" 40 "a040_swrhLimitedResetRetriesExpired" 39 "a039_csohCh2CsErrorErrAtReset" 38 "a038_csohCh1CsErrorErrAtReset" 37 "a037_epmV5P2Fail" 36 "a036_sbcmSbcBistFailed" 35 "a035_sbchChipIdFail" 34 "a034_sbchReadbackRegFail" 33 "a033_icsvcPswVersionMismatch" 32 "a032_eolpEolCheckFailed" 31 "a031_pmsProductionModeFailed" 30 "a030_rsthClockReset" 29 "a029_smuhSmuCoreCntErrorTestFail" 28 "a028_smuhNonInitDataCorruption" 27 "a027_mcusscDmuHfErr" 26 "a026_mrccCsErrorCheckFail" 25 "a025_btarcCorruptionCheck" 24 "a024_srhCsErrorCheckFail" 23 "a023_btarcCorruptionCheck" 22 "a022_swrhSwResetInfoCorruptionCheck" 21 "a021_osehCsErrorCheck" 20 "a020_mcusscEolEcuIdIntegritiyFail" 19 "a019_rsthHwResetInfoCorruptionCheck" 18 "a018_exchCsErrorCheck" 17 "a017_stmdStmPlausibilityCheckErr" 16 "a016_mcufcCsErrorCheckFail" 15 "a015_mcusscCsErrorCheckFail" 14 "a014_mcusscSffMonitoringMia" 13 "a013_mcusscSffMonitoringFailed" 12 "a012_mcusscMbistEccErr" 11 "a011_mcusscMonbistErr" 10 "a010_svcIncompatibleSwVersions" 9 "a009_mcusscLbistPermanentFail" 8 "a008_psdcPlatformShutdown" 7 "a007_tsmcCoreTempDiff" 6 "a006_swrhResetByInvalidErrid" 5 "a005_scpUnknownResetSource" 4 "a004_scpInputMia" 3 "a003_pspInvalidParamset" 2 "a002_adcMuxErr" 1 "a001_adcCalibrationOrInitFail" 0 "ALERT_DO_NOT_USE_ZERO" ;
VAL_ 1427 EPASTP_alertState 1 "SET" 0 "CLEARED" ;
VAL_ 1427 EPASTP_a264_degradedECU 3 "BOTH_ECU_SIDES" 2 "OTHER_ECU_SIDE" 1 "OWN_ECU_SIDE" 0 "NONE" ;
VAL_ 1427 EPASTP_a264_ownSideDegradationRe 92 "DC_LINK_CAPACITOR_HOTSPOTCASEDIFF_TEMPERATURE" 84 "PHASECURRENT_SHUNT_TEMPERATURE_MOMENTARY" 80 "DC_LINK_CAPACITOR_TEMPERATURE" 52 "EMIFILTER_DMC_TEMPERATURE" 48 "EMIFILTER_CMC_TEMPERATURE" 44 "DCLINK_SHUNT_TEMPERATURE" 40 "PHASECURRENT_SHUNT_TEMPERATURE" 36 "POWER_MODULE_TEMPERATURE" 32 "MOTOR_COIL_TEMPERATURE" 28 "BATTERY_FET_JUNCTION_TEMPERATURE" 24 "MAIN_BOARD_TEMPERATURE" 20 "REVERSE_BATTERY_FET_JUNCTION_TEMPERATURE" 12 "RELAY_FET_JUNCTION_TEMPERATURE" 8 "BRIDGE_FET_JUNCTION_TEMPERATURE" 4 "CORE1_DEGRADATION" 0 "NO_DEGRADATION_ON_THIS_ECU_SIDE" ;
VAL_ 1427 EPASTP_a264_otherSideDegradation 92 "DC_LINK_CAPACITOR_HOTSPOTCASEDIFF_TEMPERATURE" 84 "PHASECURRENT_SHUNT_TEMPERATURE_MOMENTARY" 80 "DC_LINK_CAPACITOR_TEMPERATURE" 52 "EMIFILTER_DMC_TEMPERATURE" 48 "EMIFILTER_CMC_TEMPERATURE" 44 "DCLINK_SHUNT_TEMPERATURE" 40 "PHASECURRENT_SHUNT_TEMPERATURE" 36 "POWER_MODULE_TEMPERATURE" 32 "MOTOR_COIL_TEMPERATURE" 28 "BATTERY_FET_JUNCTION_TEMPERATURE" 24 "MAIN_BOARD_TEMPERATURE" 20 "REVERSE_BATTERY_FET_JUNCTION_TEMPERATURE" 12 "RELAY_FET_JUNCTION_TEMPERATURE" 8 "BRIDGE_FET_JUNCTION_TEMPERATURE" 4 "CORE1_DEGRADATION" 0 "NO_DEGRADATION_ON_THIS_ECU_SIDE" ;
VAL_ 1427 EPASTP_a265_degradedECU 3 "BOTH_ECU_SIDES" 2 "OTHER_ECU_SIDE" 1 "OWN_ECU_SIDE" 0 "NONE" ;
VAL_ 1427 EPASTP_a267_velocityEstimatorSta 5 "BACKUP_MOTOR" 4 "BACKUP_WHEELS_B" 3 "BACKUP_WHEELS_A" 2 "WHEELS_REDUCED" 1 "WHEELS_NORMAL" 0 "NOT_INITIALIZED" ;
